VERSION "created by canmatrix"

NS_ :

BS_:

BU_:

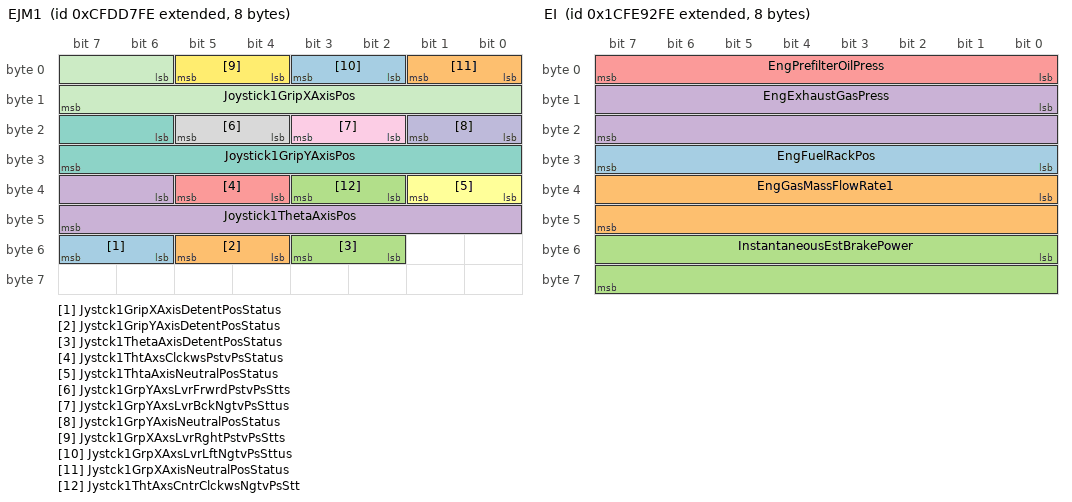
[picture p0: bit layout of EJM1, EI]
BO_ 2365446142 EJM1: 8 Vector__XXX
 SG_ Jystck1GripXAxisDetentPosStatus : 54|2@1+ (1,0) [0|3] "" Vector__XXX
 SG_ Jystck1GripYAxisDetentPosStatus : 52|2@1+ (1,0) [0|3] "" Vector__XXX
 SG_ Jystck1ThetaAxisDetentPosStatus : 50|2@1+ (1,0) [0|3] "" Vector__XXX
 SG_ Joystick1ThetaAxisPos : 38|10@1+ (0.1,0) [0|102] "%" Vector__XXX
 SG_ Jystck1ThtAxsClckwsPstvPsStatus : 36|2@1+ (1,0) [0|3] "" Vector__XXX
 SG_ Jystck1ThtaAxisNeutralPosStatus : 32|2@1+ (1,0) [0|3] "" Vector__XXX
 SG_ Joystick1GripYAxisPos : 22|10@1+ (0.1,0) [0|102] "%" Vector__XXX
 SG_ Jystck1GrpYAxsLvrFrwrdPstvPsStts : 20|2@1+ (1,0) [0|3] "" Vector__XXX
 SG_ Jystck1GrpYAxsLvrBckNgtvPsSttus : 18|2@1+ (1,0) [0|3] "" Vector__XXX
 SG_ Jystck1GrpYAxisNeutralPosStatus : 16|2@1+ (1,0) [0|3] "" Vector__XXX
 SG_ Joystick1GripXAxisPos : 6|10@1+ (0.1,0) [0|102] "%" Vector__XXX
 SG_ Jystck1GrpXAxsLvrRghtPstvPsStts : 4|2@1+ (1,0) [0|3] "" Vector__XXX
 SG_ Jystck1GrpXAxsLvrLftNgtvPsSttus : 2|2@1+ (1,0) [0|3] "" Vector__XXX
 SG_ Jystck1GrpXAxisNeutralPosStatus : 0|2@1+ (1,0) [0|3] "" Vector__XXX
 SG_ Jystck1ThtAxsCntrClckwsNgtvPsStt : 34|2@1+ (1,0) [0|3] "" Vector__XXX

BO_ 2633929470 EI: 8 Vector__XXX
 SG_ EngFuelRackPos : 24|8@1+ (0.4,0) [0|100] "%" Vector__XXX
 SG_ EngGasMassFlowRate1 : 32|16@1+ (0.05,0) [0|3212.75] "kg/h" Vector__XXX
 SG_ InstantaneousEstBrakePower : 48|16@1+ (0.5,0) [0|32127.5] "kW" Vector__XXX
 SG_ EngExhaustGasPress : 8|16@1+ (0.0078125,-250) [-250|251.99] "kPa" Vector__XXX
 SG_ EngPrefilterOilPress : 0|8@1+ (4,0) [0|1000] "kPa" Vector__XXX

BO_ 2633937406 EH: 8 Vector__XXX
 SG_ TotalECURunTime : 32|32@1+ (0.05,0) [0|210554060.75] "hr" Vector__XXX
 SG_ TotalECUDistance : 0|32@1+ (0.125,0) [0|526385151.9] "km" Vector__XXX

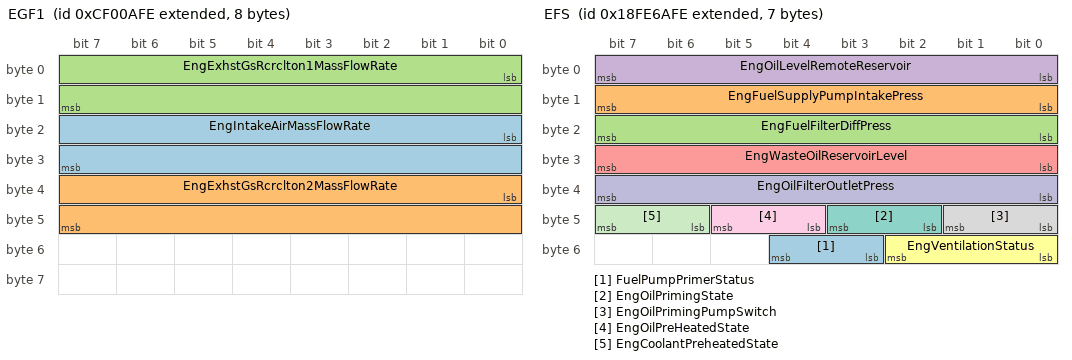
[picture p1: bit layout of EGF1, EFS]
BO_ 2364541694 EGF1: 8 Vector__XXX
 SG_ EngIntakeAirMassFlowRate : 16|16@1+ (0.05,0) [0|3212.75] "kg/h" Vector__XXX
 SG_ EngExhstGsRcrclton2MassFlowRate : 32|16@1+ (0.05,0) [0|3212.75] "kg/h" Vector__XXX
 SG_ EngExhstGsRcrclton1MassFlowRate : 0|16@1+ (0.05,0) [0|3212.75] "kg/h" Vector__XXX

BO_ 2566810366 EFS: 7 Vector__XXX
 SG_ FuelPumpPrimerStatus : 51|2@1+ (1,0) [0|3] "" Vector__XXX
 SG_ EngFuelSupplyPumpIntakePress : 8|8@1+ (2,0) [0|500] "kPa" Vector__XXX
 SG_ EngFuelFilterDiffPress : 16|8@1+ (2,0) [0|500] "kPa" Vector__XXX
 SG_ EngOilLevelRemoteReservoir : 0|8@1+ (0.4,0) [0|100] "%" Vector__XXX
 SG_ EngWasteOilReservoirLevel : 24|8@1+ (0.4,0) [0|100] "%" Vector__XXX
 SG_ EngVentilationStatus : 48|3@1+ (1,0) [0|7] "" Vector__XXX
 SG_ EngOilPrimingState : 42|2@1+ (1,0) [0|3] "" Vector__XXX
 SG_ EngOilPrimingPumpSwitch : 40|2@1+ (1,0) [0|3] "" Vector__XXX
 SG_ EngOilPreHeatedState : 44|2@1+ (1,0) [0|3] "" Vector__XXX
 SG_ EngOilFilterOutletPress : 32|8@1+ (4,0) [0|1000] "kPa" Vector__XXX
 SG_ EngCoolantPreheatedState : 46|2@1+ (1,0) [0|3] "" Vector__XXX

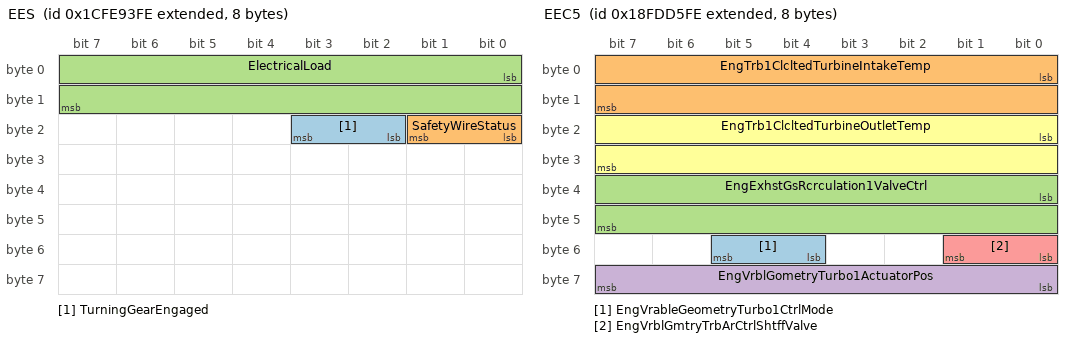
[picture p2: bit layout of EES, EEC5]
BO_ 2633929726 EES: 8 Vector__XXX
 SG_ TurningGearEngaged : 18|2@1+ (1,0) [0|3] "" Vector__XXX
 SG_ SafetyWireStatus : 16|2@1+ (1,0) [0|3] "" Vector__XXX
 SG_ ElectricalLoad : 0|16@1+ (0.5,0) [0|32127.5] "kW" Vector__XXX

BO_ 2566772222 EEC5: 8 Vector__XXX
 SG_ EngVrableGeometryTurbo1CtrlMode : 52|2@1+ (1,0) [0|3] "" Vector__XXX
 SG_ EngTrb1ClcltedTurbineIntakeTemp : 0|16@1+ (0.03125,-273) [-273|1734.96875] "deg C" Vector__XXX
 SG_ EngExhstGsRcrculation1ValveCtrl : 32|16@1+ (0.0025,0) [0|160.6375] "%" Vector__XXX
 SG_ EngVrblGometryTurbo1ActuatorPos : 56|8@1+ (0.4,0) [0|100] "%" Vector__XXX
 SG_ EngVrblGmtryTrbArCtrlShtffValve : 48|2@1+ (1,0) [0|3] "" Vector__XXX
 SG_ EngTrb1ClcltedTurbineOutletTemp : 16|16@1+ (0.03125,-273) [-273|1734.96875] "deg C" Vector__XXX

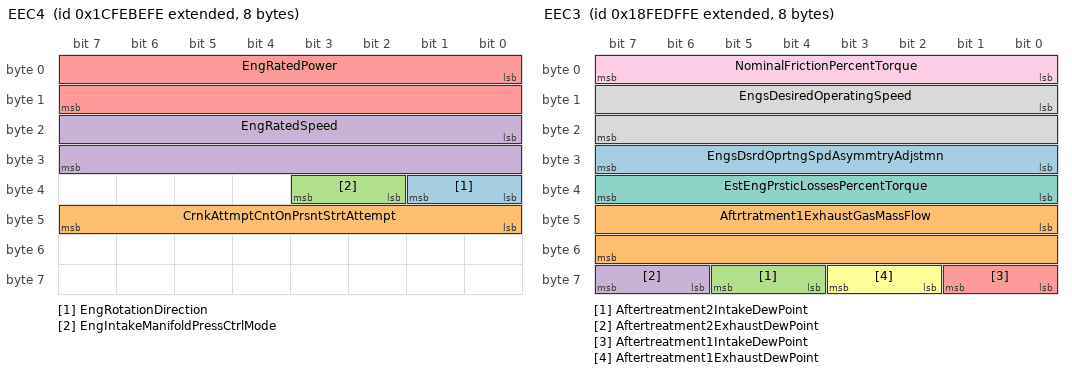
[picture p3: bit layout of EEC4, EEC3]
BO_ 2633940734 EEC4: 8 Vector__XXX
 SG_ EngRotationDirection : 32|2@1+ (1,0) [0|3] "" Vector__XXX
 SG_ CrnkAttmptCntOnPrsntStrtAttempt : 40|8@1+ (1,0) [0|250] "" Vector__XXX
 SG_ EngIntakeManifoldPressCtrlMode : 34|2@1+ (1,0) [0|3] "" Vector__XXX
 SG_ EngRatedSpeed : 16|16@1+ (0.125,0) [0|8031.875] "rpm" Vector__XXX
 SG_ EngRatedPower : 0|16@1+ (0.5,0) [0|32127.5] "kW" Vector__XXX

BO_ 2566840318 EEC3: 8 Vector__XXX
 SG_ EngsDsrdOprtngSpdAsymmtryAdjstmn : 24|8@1+ (1,0) [0|250] "" Vector__XXX
 SG_ Aftrtratment1ExhaustGasMassFlow : 40|16@1+ (0.2,0) [0|12851] "kg/h" Vector__XXX
 SG_ Aftertreatment2IntakeDewPoint : 60|2@1+ (1,0) [0|3] "" Vector__XXX
 SG_ Aftertreatment2ExhaustDewPoint : 62|2@1+ (1,0) [0|3] "" Vector__XXX
 SG_ Aftertreatment1IntakeDewPoint : 56|2@1+ (1,0) [0|3] "" Vector__XXX
 SG_ Aftertreatment1ExhaustDewPoint : 58|2@1+ (1,0) [0|3] "" Vector__XXX
 SG_ EstEngPrsticLossesPercentTorque : 32|8@1+ (1,-125) [-125|125] "%" Vector__XXX
 SG_ EngsDesiredOperatingSpeed : 8|16@1+ (0.125,0) [0|8031.875] "rpm" Vector__XXX
 SG_ NominalFrictionPercentTorque : 0|8@1+ (1,-125) [-125|125] "%" Vector__XXX

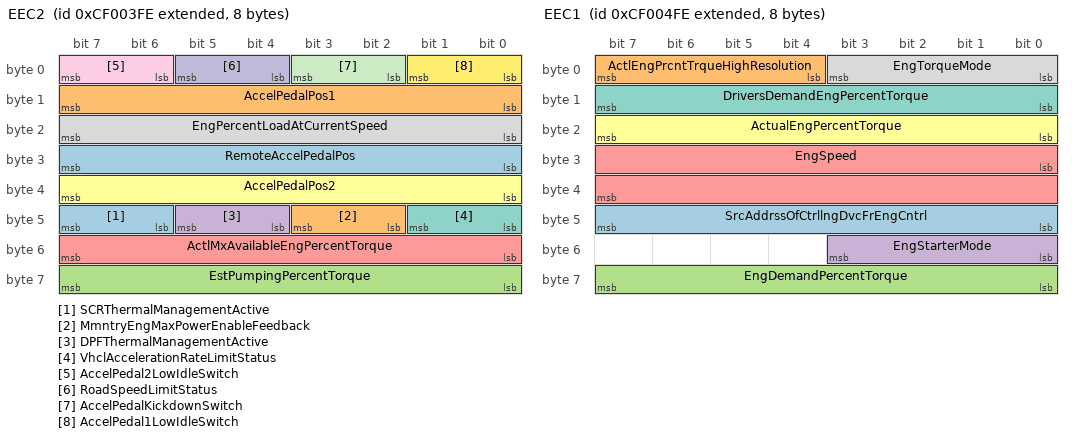
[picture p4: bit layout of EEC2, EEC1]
BO_ 2364539902 EEC2: 8 Vector__XXX
 SG_ SCRThermalManagementActive : 46|2@1+ (1,0) [0|3] "" Vector__XXX
 SG_ MmntryEngMaxPowerEnableFeedback : 42|2@1+ (1,0) [0|3] "" Vector__XXX
 SG_ EstPumpingPercentTorque : 56|8@1+ (1,-125) [-125|125] "%" Vector__XXX
 SG_ DPFThermalManagementActive : 44|2@1+ (1,0) [0|3] "" Vector__XXX
 SG_ ActlMxAvailableEngPercentTorque : 48|8@1+ (0.4,0) [0|100] "%" Vector__XXX
 SG_ AccelPedalPos2 : 32|8@1+ (0.4,0) [0|100] "%" Vector__XXX
 SG_ VhclAccelerationRateLimitStatus : 40|2@1+ (1,0) [0|3] "" Vector__XXX
 SG_ EngPercentLoadAtCurrentSpeed : 16|8@1+ (1,0) [0|250] "%" Vector__XXX
 SG_ AccelPedal2LowIdleSwitch : 6|2@1+ (1,0) [0|3] "" Vector__XXX
 SG_ RoadSpeedLimitStatus : 4|2@1+ (1,0) [0|3] "" Vector__XXX
 SG_ AccelPedalKickdownSwitch : 2|2@1+ (1,0) [0|3] "" Vector__XXX
 SG_ AccelPedal1LowIdleSwitch : 0|2@1+ (1,0) [0|3] "" Vector__XXX
 SG_ RemoteAccelPedalPos : 24|8@1+ (0.4,0) [0|100] "%" Vector__XXX
 SG_ AccelPedalPos1 : 8|8@1+ (0.4,0) [0|100] "%" Vector__XXX

BO_ 2364540158 EEC1: 8 Vector__XXX
 SG_ SrcAddrssOfCtrllngDvcFrEngCntrl : 40|8@1+ (1,0) [0|255] "" Vector__XXX
 SG_ ActlEngPrcntTrqueHighResolution : 4|4@1+ (0.125,0) [0|0.875] "%" Vector__XXX
 SG_ EngDemandPercentTorque : 56|8@1+ (1,-125) [-125|125] "%" Vector__XXX
 SG_ EngStarterMode : 48|4@1+ (1,0) [0|15] "" Vector__XXX
 SG_ EngSpeed : 24|16@1+ (0.125,0) [0|8031.875] "rpm" Vector__XXX
 SG_ ActualEngPercentTorque : 16|8@1+ (1,-125) [-125|125] "%" Vector__XXX
 SG_ DriversDemandEngPercentTorque : 8|8@1+ (1,-125) [-125|125] "%" Vector__XXX
 SG_ EngTorqueMode : 0|4@1+ (1,0) [0|15] "" Vector__XXX

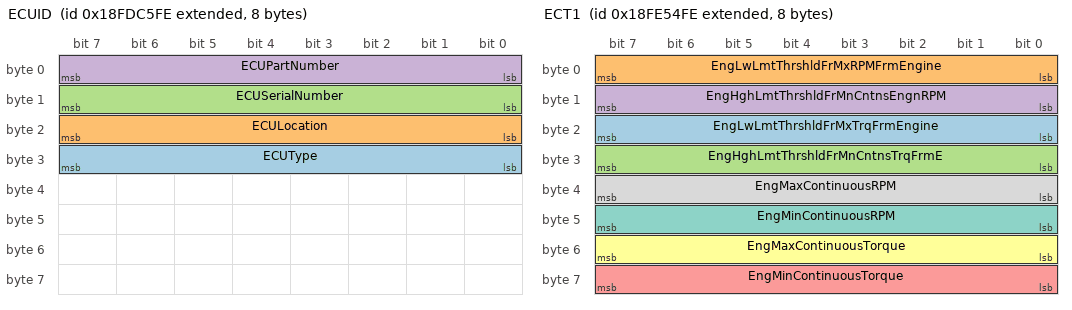
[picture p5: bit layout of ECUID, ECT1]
BO_ 2566768126 ECUID: 8 Vector__XXX
 SG_ ECUType : 24|8@1+ (1,0) [0|255] "" Vector__XXX
 SG_ ECULocation : 16|8@1+ (1,0) [0|255] "" Vector__XXX
 SG_ ECUSerialNumber : 8|8@1+ (1,0) [0|255] "" Vector__XXX
 SG_ ECUPartNumber : 0|8@1+ (1,0) [0|255] "" Vector__XXX

BO_ 2566804734 ECT1: 8 Vector__XXX
 SG_ EngLwLmtThrshldFrMxTrqFrmEngine : 16|8@1+ (1,-125) [-125|125] "%" Vector__XXX
 SG_ EngLwLmtThrshldFrMxRPMFrmEngine : 0|8@1+ (32,0) [0|8000] "rpm" Vector__XXX
 SG_ EngHghLmtThrshldFrMnCntnsTrqFrmE : 24|8@1+ (1,-125) [-125|125] "%" Vector__XXX
 SG_ EngHghLmtThrshldFrMnCntnsEngnRPM : 8|8@1+ (32,0) [0|8000] "rpm" Vector__XXX
 SG_ EngMinContinuousTorque : 56|8@1+ (1,-125) [-125|125] "%" Vector__XXX
 SG_ EngMaxContinuousTorque : 48|8@1+ (1,-125) [-125|125] "%" Vector__XXX
 SG_ EngMinContinuousRPM : 40|8@1+ (32,0) [0|8000] "rpm" Vector__XXX
 SG_ EngMaxContinuousRPM : 32|8@1+ (32,0) [0|8000] "rpm" Vector__XXX

BO_ 2566841342 EC1: 39 Vector__XXX
 SG_ SupportTSC1CtrlPurposeGroup4 : 304|8@1+ (1,0) [0|255] "" Vector__XXX
 SG_ SupportTSC1CtrlPurposeGroup3 : 296|8@1+ (1,0) [0|255] "" Vector__XXX
 SG_ SupportTSC1CtrlPurposeGroup2 : 288|8@1+ (1,0) [0|255] "" Vector__XXX
 SG_ SupportTSC1CtrlPurposeGroup1 : 280|8@1+ (1,0) [0|255] "" Vector__XXX
 SG_ SupportVariableRateTSC1Message : 272|8@1+ (1,0) [0|255] "" Vector__XXX
 SG_ EngDefaultTorqueLimit : 256|16@1+ (1,0) [0|64255] "Nm" Vector__XXX
 SG_ EngMomentOfInertia : 240|16@1+ (0.004,0) [0|257.02] "kg*m*m" Vector__XXX
 SG_ EngExRngRqdSpdCtrlRngUpperLimit : 224|16@1+ (0.125,0) [0|8031.875] "rpm" Vector__XXX
 SG_ EngRqdTorqueCtrlRangeUpperLimit : 216|8@1+ (1,-125) [-125|125] "%" Vector__XXX
 SG_ EngRqdTorqueCtrlRangeLowerLimit : 208|8@1+ (1,-125) [-125|125] "%" Vector__XXX
 SG_ EngRqedSpeedCtrlRangeUpperLimit : 200|8@1+ (10,0) [0|2500] "rpm" Vector__XXX
 SG_ EngRqedSpeedCtrlRangeLowerLimit : 192|8@1+ (10,0) [0|2500] "rpm" Vector__XXX
 SG_ EngMxMomentaryOverrideTimeLimit : 184|8@1+ (0.1,0) [0|25] "s" Vector__XXX
 SG_ EngMxMmntaryOverrideSpeedPoint7 : 168|16@1+ (0.125,0) [0|8031.875] "rpm" Vector__XXX
 SG_ EngReferenceTorque : 152|16@1+ (1,0) [0|64255] "Nm" Vector__XXX
 SG_ EngSpeedAtHighIdlePoint6 : 120|16@1+ (0.125,0) [0|8031.875] "rpm" Vector__XXX
 SG_ EngGainOfEndspeedGovernor : 136|16@1+ (0.00078125,0) [0|50.2] "%/rpm" Vector__XXX
 SG_ EngPercentTorqueAtPoint5 : 112|8@1+ (1,-125) [-125|125] "%" Vector__XXX
 SG_ EngSpeedAtPoint5 : 96|16@1+ (0.125,0) [0|8031.875] "rpm" Vector__XXX
 SG_ EngPercentTorqueAtPoint4 : 88|8@1+ (1,-125) [-125|125] "%" Vector__XXX
 SG_ EngSpeedAtPoint4 : 72|16@1+ (0.125,0) [0|8031.875] "rpm" Vector__XXX
 SG_ EngPercentTorqueAtPoint3 : 64|8@1+ (1,-125) [-125|125] "%" Vector__XXX
 SG_ EngSpeedAtPoint3 : 48|16@1+ (0.125,0) [0|8031.875] "rpm" Vector__XXX
 SG_ EngPercentTorqueAtPoint2 : 40|8@1+ (1,-125) [-125|125] "%" Vector__XXX
 SG_ EngSpeedAtPoint2 : 24|16@1+ (0.125,0) [0|8031.875] "rpm" Vector__XXX
 SG_ EngPercentTorqueAtIdlePoint1 : 16|8@1+ (1,-125) [-125|125] "%" Vector__XXX
 SG_ EngSpeedAtIdlePoint1 : 0|16@1+ (0.125,0) [0|8031.875] "rpm" Vector__XXX

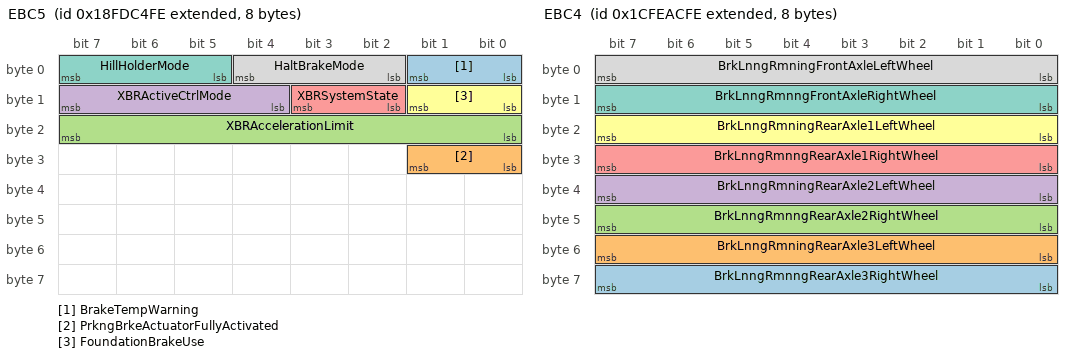
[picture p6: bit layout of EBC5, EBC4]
BO_ 2566767870 EBC5: 8 Vector__XXX
 SG_ BrakeTempWarning : 0|2@1+ (1,0) [0|3] "" Vector__XXX
 SG_ PrkngBrkeActuatorFullyActivated : 24|2@1+ (1,0) [0|3] "" Vector__XXX
 SG_ XBRAccelerationLimit : 16|8@1+ (0.1,-12.5) [-12.5|12.5] "m/s/s" Vector__XXX
 SG_ XBRActiveCtrlMode : 12|4@1+ (1,0) [0|15] "" Vector__XXX
 SG_ XBRSystemState : 10|2@1+ (1,0) [0|3] "" Vector__XXX
 SG_ FoundationBrakeUse : 8|2@1+ (1,0) [0|3] "" Vector__XXX
 SG_ HillHolderMode : 5|3@1+ (1,0) [0|7] "" Vector__XXX
 SG_ HaltBrakeMode : 2|3@1+ (1,0) [0|7] "" Vector__XXX

BO_ 2633936126 EBC4: 8 Vector__XXX
 SG_ BrkLnngRmnngRearAxle3RightWheel : 56|8@1+ (0.4,0) [0|100] "%" Vector__XXX
 SG_ BrkLnngRmningRearAxle3LeftWheel : 48|8@1+ (0.4,0) [0|100] "%" Vector__XXX
 SG_ BrkLnngRmnngRearAxle2RightWheel : 40|8@1+ (0.4,0) [0|100] "%" Vector__XXX
 SG_ BrkLnngRmningRearAxle2LeftWheel : 32|8@1+ (0.4,0) [0|100] "%" Vector__XXX
 SG_ BrkLnngRmnngRearAxle1RightWheel : 24|8@1+ (0.4,0) [0|100] "%" Vector__XXX
 SG_ BrkLnngRmningRearAxle1LeftWheel : 16|8@1+ (0.4,0) [0|100] "%" Vector__XXX
 SG_ BrkLnngRmnngFrontAxleRightWheel : 8|8@1+ (0.4,0) [0|100] "%" Vector__XXX
 SG_ BrkLnngRmningFrontAxleLeftWheel : 0|8@1+ (0.4,0) [0|100] "%" Vector__XXX

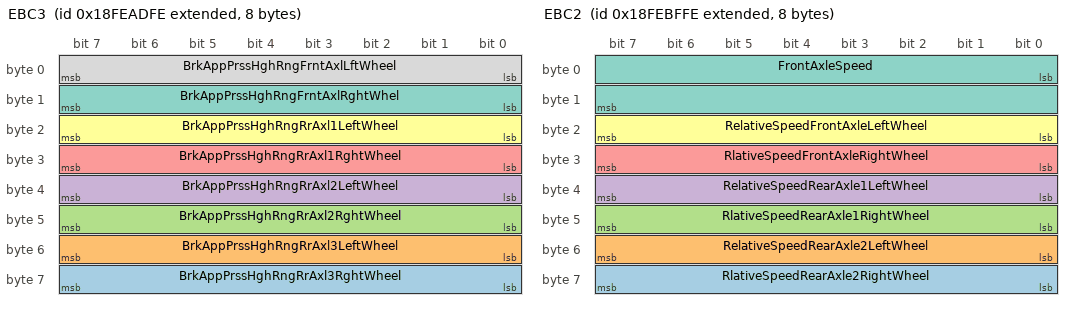
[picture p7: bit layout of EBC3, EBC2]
BO_ 2566827518 EBC3: 8 Vector__XXX
 SG_ BrkAppPrssHghRngRrAxl3RghtWheel : 56|8@1+ (5,0) [0|1250] "kPa" Vector__XXX
 SG_ BrkAppPrssHghRngRrAxl3LeftWheel : 48|8@1+ (5,0) [0|1250] "kPa" Vector__XXX
 SG_ BrkAppPrssHghRngRrAxl2RghtWheel : 40|8@1+ (5,0) [0|1250] "kPa" Vector__XXX
 SG_ BrkAppPrssHghRngRrAxl2LeftWheel : 32|8@1+ (5,0) [0|1250] "kPa" Vector__XXX
 SG_ BrkAppPrssHghRngRrAxl1RghtWheel : 24|8@1+ (5,0) [0|1250] "kPa" Vector__XXX
 SG_ BrkAppPrssHghRngRrAxl1LeftWheel : 16|8@1+ (5,0) [0|1250] "kPa" Vector__XXX
 SG_ BrkAppPrssHghRngFrntAxlRghtWhel : 8|8@1+ (5,0) [0|1250] "kPa" Vector__XXX
 SG_ BrkAppPrssHghRngFrntAxlLftWheel : 0|8@1+ (5,0) [0|1250] "kPa" Vector__XXX

BO_ 2566832126 EBC2: 8 Vector__XXX
 SG_ RlativeSpeedRearAxle2RightWheel : 56|8@1+ (0.0625,-7.8125) [-7.8125|7.8125] "km/h" Vector__XXX
 SG_ RelativeSpeedRearAxle2LeftWheel : 48|8@1+ (0.0625,-7.8125) [-7.8125|7.8125] "km/h" Vector__XXX
 SG_ RlativeSpeedRearAxle1RightWheel : 40|8@1+ (0.0625,-7.8125) [-7.8125|7.8125] "km/h" Vector__XXX
 SG_ RelativeSpeedRearAxle1LeftWheel : 32|8@1+ (0.0625,-7.8125) [-7.8125|7.8125] "km/h" Vector__XXX
 SG_ RlativeSpeedFrontAxleRightWheel : 24|8@1+ (0.0625,-7.8125) [-7.8125|7.8125] "km/h" Vector__XXX
 SG_ RelativeSpeedFrontAxleLeftWheel : 16|8@1+ (0.0625,-7.8125) [-7.8125|7.8125] "km/h" Vector__XXX
 SG_ FrontAxleSpeed : 0|16@1+ (0.00390625,0) [0|250.996] "km/h" Vector__XXX

BO_ 2565865982 EBC1: 8 Vector__XXX
 SG_ EngAuxShutdownSwitch : 28|2@1+ (1,0) [0|3] "" Vector__XXX
 SG_ SrcAddrssOfCtrllngDvcFrBrkCntrl : 48|8@1+ (1,0) [0|255] "" Vector__XXX
 SG_ BrakePedalPos : 8|8@1+ (0.4,0) [0|100] "%" Vector__XXX
 SG_ TrctrMntdTrilerABSWarningSignal : 62|2@1+ (1,0) [0|3] "" Vector__XXX
 SG_ TrailerABSStatus : 60|2@1+ (1,0) [0|3] "" Vector__XXX
 SG_ HaltBrakeSwitch : 58|2@1+ (1,0) [0|3] "" Vector__XXX
 SG_ ATC_ASRInformationSignal : 46|2@1+ (1,0) [0|3] "" Vector__XXX
 SG_ ABS_EBSAmberWarningSignal : 44|2@1+ (1,0) [0|3] "" Vector__XXX
 SG_ EBSRedWarningSignal : 42|2@1+ (1,0) [0|3] "" Vector__XXX
 SG_ ABSFullyOperational : 40|2@1+ (1,0) [0|3] "" Vector__XXX
 SG_ EngRetarderSelection : 32|8@1+ (0.4,0) [0|100] "%" Vector__XXX
 SG_ RemoteAccelEnableSwitch : 30|2@1+ (1,0) [0|3] "" Vector__XXX
 SG_ EngDerateSwitch : 26|2@1+ (1,0) [0|3] "" Vector__XXX
 SG_ AccelInterlockSwitch : 24|2@1+ (1,0) [0|3] "" Vector__XXX
 SG_ TractionCtrlOverrideSwitch : 22|2@1+ (1,0) [0|3] "" Vector__XXX
 SG_ ASRHillHolderSwitch : 20|2@1+ (1,0) [0|3] "" Vector__XXX
 SG_ ASROffroadSwitch : 18|2@1+ (1,0) [0|3] "" Vector__XXX
 SG_ ABSOffroadSwitch : 16|2@1+ (1,0) [0|3] "" Vector__XXX
 SG_ EBSBrakeSwitch : 6|2@1+ (1,0) [0|3] "" Vector__XXX
 SG_ AntiLockBrakingActive : 4|2@1+ (1,0) [0|3] "" Vector__XXX
 SG_ ASRBrakeCtrlActive : 2|2@1+ (1,0) [0|3] "" Vector__XXX
 SG_ ASREngCtrlActive : 0|2@1+ (1,0) [0|3] "" Vector__XXX

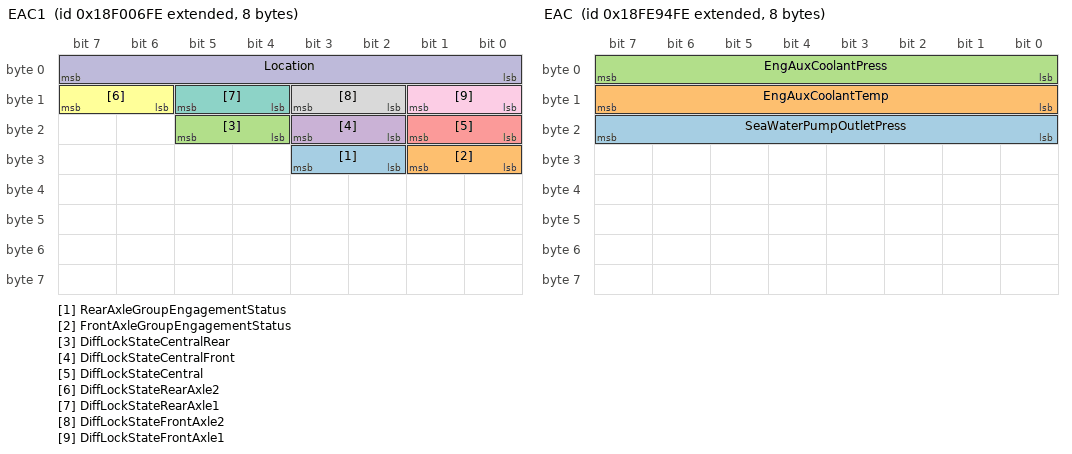
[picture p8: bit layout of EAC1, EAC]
BO_ 2565867262 EAC1: 8 Vector__XXX
 SG_ RearAxleGroupEngagementStatus : 26|2@1+ (1,0) [0|3] "" Vector__XXX
 SG_ FrontAxleGroupEngagementStatus : 24|2@1+ (1,0) [0|3] "" Vector__XXX
 SG_ DiffLockStateCentralRear : 20|2@1+ (1,0) [0|3] "" Vector__XXX
 SG_ DiffLockStateCentralFront : 18|2@1+ (1,0) [0|3] "" Vector__XXX
 SG_ DiffLockStateCentral : 16|2@1+ (1,0) [0|3] "" Vector__XXX
 SG_ DiffLockStateRearAxle2 : 14|2@1+ (1,0) [0|3] "" Vector__XXX
 SG_ DiffLockStateRearAxle1 : 12|2@1+ (1,0) [0|3] "" Vector__XXX
 SG_ DiffLockStateFrontAxle2 : 10|2@1+ (1,0) [0|3] "" Vector__XXX
 SG_ DiffLockStateFrontAxle1 : 8|2@1+ (1,0) [0|3] "" Vector__XXX
 SG_ Location : 0|8@1+ (1,0) [0|255] "" Vector__XXX

BO_ 2566821118 EAC: 8 Vector__XXX
 SG_ SeaWaterPumpOutletPress : 16|8@1+ (2,0) [0|500] "kPa" Vector__XXX
 SG_ EngAuxCoolantTemp : 8|8@1+ (1,-40) [-40|210] "deg C" Vector__XXX
 SG_ EngAuxCoolantPress : 0|8@1+ (4,0) [0|1000] "kPa" Vector__XXX

BO_ 2566810622 DI: 8 Vector__XXX
 SG_ Driver2 : 8|8@1+ (1,0) [0|255] "" Vector__XXX
 SG_ Driver1 : 0|8@1+ (1,0) [0|255] "" Vector__XXX

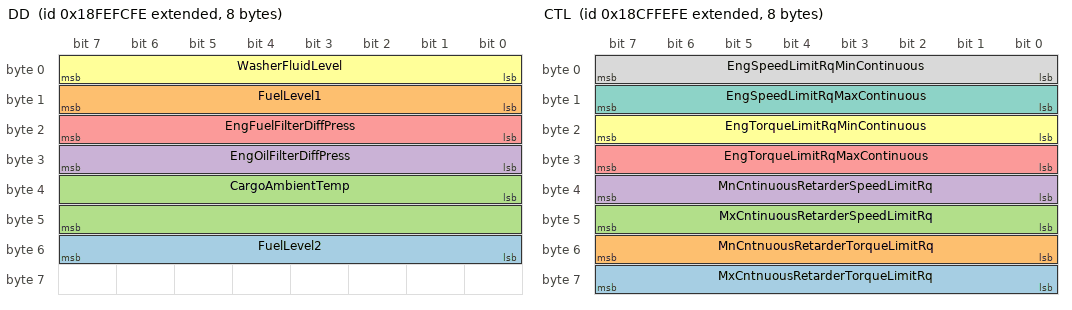
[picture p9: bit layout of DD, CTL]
BO_ 2566847742 DD: 8 Vector__XXX
 SG_ FuelLevel2 : 48|8@1+ (0.4,0) [0|100] "%" Vector__XXX
 SG_ FuelLevel1 : 8|8@1+ (0.4,0) [0|100] "%" Vector__XXX
 SG_ CargoAmbientTemp : 32|16@1+ (0.03125,-273) [-273|1734.96875] "deg C" Vector__XXX
 SG_ EngOilFilterDiffPress : 24|8@1+ (0.5,0) [0|125] "kPa" Vector__XXX
 SG_ EngFuelFilterDiffPress : 16|8@1+ (2,0) [0|500] "kPa" Vector__XXX
 SG_ WasherFluidLevel : 0|8@1+ (0.4,0) [0|100] "%" Vector__XXX

BO_ 2566811902 CVW: 8 Vector__XXX
 SG_ PoweredVehicleWeight : 0|16@1+ (10,0) [0|642550] "kg" Vector__XXX
 SG_ GrossCombinationVehicleWeight : 16|16@1+ (10,0) [0|642550] "kg" Vector__XXX

BO_ 2563768062 CTL: 8 Vector__XXX
 SG_ MxCntnuousRetarderTorqueLimitRq : 56|8@1+ (1,-125) [-125|125] "%" Vector__XXX
 SG_ MnCntnuousRetarderTorqueLimitRq : 48|8@1+ (1,-125) [-125|125] "%" Vector__XXX
 SG_ MxCntinuousRetarderSpeedLimitRq : 40|8@1+ (32,0) [0|8000] "rpm" Vector__XXX
 SG_ MnCntinuousRetarderSpeedLimitRq : 32|8@1+ (32,0) [0|8000] "rpm" Vector__XXX
 SG_ EngTorqueLimitRqMaxContinuous : 24|8@1+ (1,-125) [-125|125] "%" Vector__XXX
 SG_ EngTorqueLimitRqMinContinuous : 16|8@1+ (1,-125) [-125|125] "%" Vector__XXX
 SG_ EngSpeedLimitRqMaxContinuous : 8|8@1+ (32,0) [0|8000] "rpm" Vector__XXX
 SG_ EngSpeedLimitRqMinContinuous : 0|8@1+ (32,0) [0|8000] "rpm" Vector__XXX

BO_ 2633924862 CT6: 8 Vector__XXX
 SG_ EngAverageCombustionTime : 16|16@1+ (0.01,0) [0|642.55] "ms" Vector__XXX
 SG_ EngDesiredCombustionTime : 0|16@1+ (0.01,0) [0|642.55] "ms" Vector__XXX

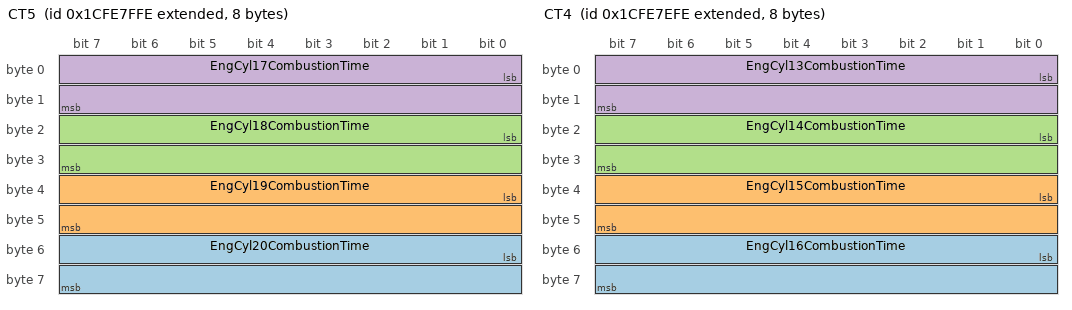
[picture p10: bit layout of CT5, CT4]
BO_ 2633924606 CT5: 8 Vector__XXX
 SG_ EngCyl20CombustionTime : 48|16@1+ (0.01,0) [0|642.55] "ms" Vector__XXX
 SG_ EngCyl19CombustionTime : 32|16@1+ (0.01,0) [0|642.55] "ms" Vector__XXX
 SG_ EngCyl18CombustionTime : 16|16@1+ (0.01,0) [0|642.55] "ms" Vector__XXX
 SG_ EngCyl17CombustionTime : 0|16@1+ (0.01,0) [0|642.55] "ms" Vector__XXX

BO_ 2633924350 CT4: 8 Vector__XXX
 SG_ EngCyl16CombustionTime : 48|16@1+ (0.01,0) [0|642.55] "ms" Vector__XXX
 SG_ EngCyl15CombustionTime : 32|16@1+ (0.01,0) [0|642.55] "ms" Vector__XXX
 SG_ EngCyl14CombustionTime : 16|16@1+ (0.01,0) [0|642.55] "ms" Vector__XXX
 SG_ EngCyl13CombustionTime : 0|16@1+ (0.01,0) [0|642.55] "ms" Vector__XXX

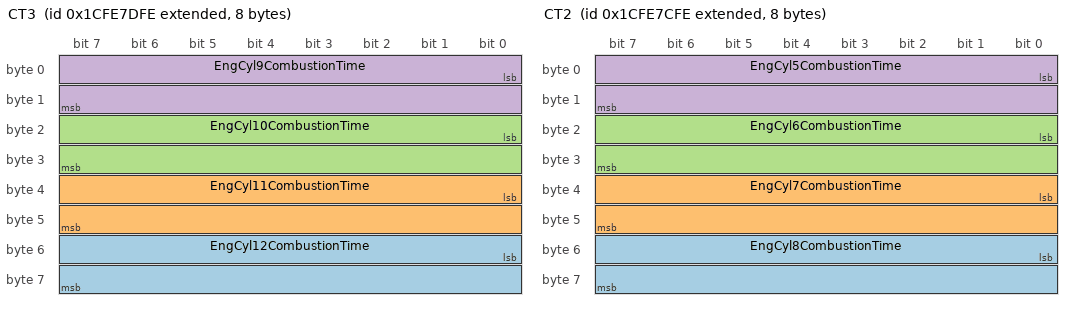
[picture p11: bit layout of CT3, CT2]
BO_ 2633924094 CT3: 8 Vector__XXX
 SG_ EngCyl12CombustionTime : 48|16@1+ (0.01,0) [0|642.55] "ms" Vector__XXX
 SG_ EngCyl11CombustionTime : 32|16@1+ (0.01,0) [0|642.55] "ms" Vector__XXX
 SG_ EngCyl10CombustionTime : 16|16@1+ (0.01,0) [0|642.55] "ms" Vector__XXX
 SG_ EngCyl9CombustionTime : 0|16@1+ (0.01,0) [0|642.55] "ms" Vector__XXX

BO_ 2633923838 CT2: 8 Vector__XXX
 SG_ EngCyl8CombustionTime : 48|16@1+ (0.01,0) [0|642.55] "ms" Vector__XXX
 SG_ EngCyl7CombustionTime : 32|16@1+ (0.01,0) [0|642.55] "ms" Vector__XXX
 SG_ EngCyl6CombustionTime : 16|16@1+ (0.01,0) [0|642.55] "ms" Vector__XXX
 SG_ EngCyl5CombustionTime : 0|16@1+ (0.01,0) [0|642.55] "ms" Vector__XXX

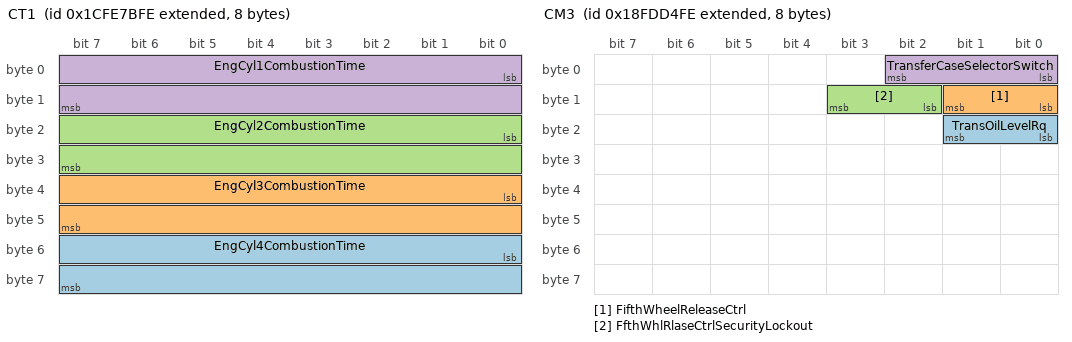
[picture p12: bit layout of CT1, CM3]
BO_ 2633923582 CT1: 8 Vector__XXX
 SG_ EngCyl4CombustionTime : 48|16@1+ (0.01,0) [0|642.55] "ms" Vector__XXX
 SG_ EngCyl3CombustionTime : 32|16@1+ (0.01,0) [0|642.55] "ms" Vector__XXX
 SG_ EngCyl2CombustionTime : 16|16@1+ (0.01,0) [0|642.55] "ms" Vector__XXX
 SG_ EngCyl1CombustionTime : 0|16@1+ (0.01,0) [0|642.55] "ms" Vector__XXX

BO_ 2633878014 CMI: 8 Vector__XXX
 SG_ TotalCountOfConfigChangesMade : 0|16@1+ (1,0) [0|64255] "counts" Vector__XXX

BO_ 2566771966 CM3: 8 Vector__XXX
 SG_ TransOilLevelRq : 16|2@1+ (1,0) [0|3] "" Vector__XXX
 SG_ FifthWheelReleaseCtrl : 8|2@1+ (1,0) [0|3] "" Vector__XXX
 SG_ FfthWhlRlaseCtrlSecurityLockout : 10|2@1+ (1,0) [0|3] "" Vector__XXX
 SG_ TransferCaseSelectorSwitch : 0|3@1+ (1,0) [0|7] "" Vector__XXX

BO_ 2564882174 CM1: 8 Vector__XXX
 SG_ DslPrtcltFltrRgnrtonForceSwitch : 42|2@1+ (1,0) [0|3] "" Vector__XXX
 SG_ DslPrtcltFltrRgnrtnInhbitSwitch : 40|2@1+ (1,0) [0|3] "" Vector__XXX
 SG_ SelectedMaxVehicleSpeedLimit : 56|8@1+ (1,0) [0|250] "" Vector__XXX
 SG_ RqCabZoneHeating : 54|2@1+ (1,0) [0|3] "" Vector__XXX
 SG_ RqEngZoneHeating : 52|2@1+ (1,0) [0|3] "" Vector__XXX
 SG_ AuxHeaterModeRq : 48|4@1+ (1,0) [0|15] "" Vector__XXX
 SG_ EngAutomaticStartEnableSwitch : 46|2@1+ (1,0) [0|3] "" Vector__XXX
 SG_ AtmaticGearShiftingEnableSwitch : 44|2@1+ (1,0) [0|3] "" Vector__XXX
 SG_ VhclLmtngSpdGvernorEnableSwitch : 38|2@1+ (1,0) [0|3] "" Vector__XXX
 SG_ VhclLmtngSpdGvrnrIncrmentSwitch : 36|2@1+ (1,0) [0|3] "" Vector__XXX
 SG_ VhclLmtngSpdGvrnrDcrementSwitch : 34|2@1+ (1,0) [0|3] "" Vector__XXX
 SG_ SeatBeltSwitch : 30|2@1+ (1,0) [0|3] "" Vector__XXX
 SG_ OperatorSeatDirectionSwitch : 28|2@1+ (1,0) [0|3] "" Vector__XXX
 SG_ BatteryMainSwitchHoldRq : 26|2@1+ (1,0) [0|3] "" Vector__XXX
 SG_ AuxHeaterCoolantPumpRq : 24|2@1+ (1,0) [0|3] "" Vector__XXX
 SG_ CabInteriorTempCmd : 8|16@1+ (0.03125,-273) [-273|1734.96875] "deg C" Vector__XXX
 SG_ RqedPercentFanSpeed : 0|8@1+ (0.4,0) [0|100] "%" Vector__XXX

BO_ 2563833598 CL: 8 Vector__XXX
 SG_ IlluminationBrightnessPercent : 0|8@1+ (0.4,0) [0|100] "%" Vector__XXX

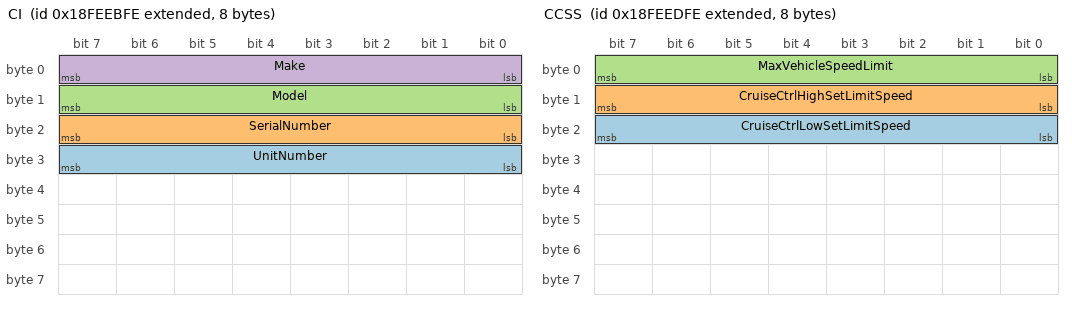
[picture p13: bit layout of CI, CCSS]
BO_ 2566843390 CI: 8 Vector__XXX
 SG_ UnitNumber : 24|8@1+ (1,0) [0|255] "" Vector__XXX
 SG_ SerialNumber : 16|8@1+ (1,0) [0|255] "" Vector__XXX
 SG_ Model : 8|8@1+ (1,0) [0|255] "" Vector__XXX
 SG_ Make : 0|8@1+ (1,0) [0|255] "" Vector__XXX

BO_ 2566844926 CCVS: 8 Vector__XXX
 SG_ ParkBrakeReleaseInhibitRq : 6|2@1+ (1,0) [0|3] "" Vector__XXX
 SG_ PTOGovernorState : 48|5@1+ (1,0) [0|31] "" Vector__XXX
 SG_ EngShutdownOverrideSwitch : 62|2@1+ (1,0) [0|3] "" Vector__XXX
 SG_ EngTestModeSwitch : 60|2@1+ (1,0) [0|3] "" Vector__XXX
 SG_ EngIdleDecrementSwitch : 58|2@1+ (1,0) [0|3] "" Vector__XXX
 SG_ EngIdleIncrementSwitch : 56|2@1+ (1,0) [0|3] "" Vector__XXX
 SG_ CruiseCtrlStates : 53|3@1+ (1,0) [0|7] "" Vector__XXX
 SG_ CruiseCtrlSetSpeed : 40|8@1+ (1,0) [0|250] "km/h" Vector__XXX
 SG_ CruiseCtrlAccelerateSwitch : 38|2@1+ (1,0) [0|3] "" Vector__XXX
 SG_ CruiseCtrlResumeSwitch : 36|2@1+ (1,0) [0|3] "" Vector__XXX
 SG_ CruiseCtrlCoastSwitch : 34|2@1+ (1,0) [0|3] "" Vector__XXX
 SG_ CruiseCtrlSetSwitch : 32|2@1+ (1,0) [0|3] "" Vector__XXX
 SG_ ClutchSwitch : 30|2@1+ (1,0) [0|3] "" Vector__XXX
 SG_ BrakeSwitch : 28|2@1+ (1,0) [0|3] "" Vector__XXX
 SG_ CruiseCtrlEnableSwitch : 26|2@1+ (1,0) [0|3] "" Vector__XXX
 SG_ CruiseCtrlActive : 24|2@1+ (1,0) [0|3] "" Vector__XXX
 SG_ WheelBasedVehicleSpeed : 8|16@1+ (0.00390625,0) [0|250.996] "km/h" Vector__XXX
 SG_ CruiseCtrlPauseSwitch : 4|2@1+ (1,0) [0|3] "" Vector__XXX
 SG_ ParkingBrakeSwitch : 2|2@1+ (1,0) [0|3] "" Vector__XXX
 SG_ TwoSpeedAxleSwitch : 0|2@1+ (1,0) [0|3] "" Vector__XXX

BO_ 2566843902 CCSS: 8 Vector__XXX
 SG_ CruiseCtrlLowSetLimitSpeed : 16|8@1+ (1,0) [0|250] "km/h" Vector__XXX
 SG_ CruiseCtrlHighSetLimitSpeed : 8|8@1+ (1,0) [0|250] "km/h" Vector__XXX
 SG_ MaxVehicleSpeedLimit : 0|8@1+ (1,0) [0|250] "km/h" Vector__XXX

BO_ 2566809598 CCC: 8 Vector__XXX
 SG_ AuxHeaterMaxOutputPower : 0|16@1+ (2,0) [0|128510] "W" Vector__XXX

BO_ 2633940222 CBI: 16 Vector__XXX
 SG_ TripServiceBrakeApps : 96|32@1+ (1,0) [0|4227858431] "appl" Vector__XXX
 SG_ TripServiceBrakeDistance : 64|32@1+ (0.125,0) [0|526385151.9] "km" Vector__XXX
 SG_ TripCompressionBrakeDistance : 32|32@1+ (0.125,0) [0|526385151.9] "km" Vector__XXX
 SG_ TotalCompressionBrakeDistance : 0|32@1+ (0.125,0) [0|526385151.9] "km" Vector__XXX

BO_ 2566775294 CACI: 8 Vector__XXX
 SG_ CbA_CRfrgrntCmprssorOutletPress : 0|8@1+ (16,0) [0|4000] "kPa" Vector__XXX

BO_ 2566803710 BT1: 8 Vector__XXX
 SG_ Battery2Temp : 8|8@1+ (1,-40) [-40|210] "deg C" Vector__XXX
 SG_ Battery1Temp : 0|8@1+ (1,-40) [-40|210] "deg C" Vector__XXX

BO_ 2365400830 BJM9: 8 Vector__XXX
 SG_ Joystick9Button9PressedStatus : 62|2@1+ (1,0) [0|3] "" Vector__XXX
 SG_ Joystick9Button10PressedStatus : 60|2@1+ (1,0) [0|3] "" Vector__XXX
 SG_ Joystick9Button11PressedStatus : 58|2@1+ (1,0) [0|3] "" Vector__XXX
 SG_ Joystick9Button12PressedStatus : 56|2@1+ (1,0) [0|3] "" Vector__XXX
 SG_ Joystick9Button5PressedStatus : 54|2@1+ (1,0) [0|3] "" Vector__XXX
 SG_ Joystick9Button6PressedStatus : 52|2@1+ (1,0) [0|3] "" Vector__XXX
 SG_ Joystick9Button7PressedStatus : 50|2@1+ (1,0) [0|3] "" Vector__XXX
 SG_ Joystick9Button8PressedStatus : 48|2@1+ (1,0) [0|3] "" Vector__XXX
 SG_ Joystick9Button1PressedStatus : 46|2@1+ (1,0) [0|3] "" Vector__XXX
 SG_ Joystick9Button2PressedStatus : 44|2@1+ (1,0) [0|3] "" Vector__XXX
 SG_ Joystick9Button3PressedStatus : 42|2@1+ (1,0) [0|3] "" Vector__XXX
 SG_ Joystick9Button4PressedStatus : 40|2@1+ (1,0) [0|3] "" Vector__XXX
 SG_ Joystick9XAxisDetentPosStatus : 38|2@1+ (1,0) [0|3] "" Vector__XXX
 SG_ Joystick9YAxisDetentPosStatus : 36|2@1+ (1,0) [0|3] "" Vector__XXX
 SG_ Joystick9YAxisPos : 22|10@1+ (0.1,0) [0|102] "%" Vector__XXX
 SG_ Jystck9YAxsLvrFrwrdPstvPsStatus : 20|2@1+ (1,0) [0|3] "" Vector__XXX
 SG_ Jystck9YAxsLvrBckNgtvePosStatus : 18|2@1+ (1,0) [0|3] "" Vector__XXX
 SG_ Joystick9YAxisNeutralPosStatus : 16|2@1+ (1,0) [0|3] "" Vector__XXX
 SG_ Joystick9XAxisPos : 6|10@1+ (0.1,0) [0|102] "%" Vector__XXX
 SG_ Jystck9XAxsLvrRghtPstvPosStatus : 4|2@1+ (1,0) [0|3] "" Vector__XXX
 SG_ Jystck9XAxsLvrLftNgtvePosStatus : 2|2@1+ (1,0) [0|3] "" Vector__XXX
 SG_ Joystick9XAxisNeutralPosStatus : 0|2@1+ (1,0) [0|3] "" Vector__XXX

BO_ 2365401342 BJM8: 8 Vector__XXX
 SG_ Joystick8Button9PressedStatus : 62|2@1+ (1,0) [0|3] "" Vector__XXX
 SG_ Joystick8Button10PressedStatus : 60|2@1+ (1,0) [0|3] "" Vector__XXX
 SG_ Joystick8Button11PressedStatus : 58|2@1+ (1,0) [0|3] "" Vector__XXX
 SG_ Joystick8Button12PressedStatus : 56|2@1+ (1,0) [0|3] "" Vector__XXX
 SG_ Joystick8Button5PressedStatus : 54|2@1+ (1,0) [0|3] "" Vector__XXX
 SG_ Joystick8Button6PressedStatus : 52|2@1+ (1,0) [0|3] "" Vector__XXX
 SG_ Joystick8Button7PressedStatus : 50|2@1+ (1,0) [0|3] "" Vector__XXX
 SG_ Joystick8Button8PressedStatus : 48|2@1+ (1,0) [0|3] "" Vector__XXX
 SG_ Joystick8Button1PressedStatus : 46|2@1+ (1,0) [0|3] "" Vector__XXX
 SG_ Joystick8Button2PressedStatus : 44|2@1+ (1,0) [0|3] "" Vector__XXX
 SG_ Joystick8Button3PressedStatus : 42|2@1+ (1,0) [0|3] "" Vector__XXX
 SG_ Joystick8Button4PressedStatus : 40|2@1+ (1,0) [0|3] "" Vector__XXX
 SG_ Joystick8XAxisDetentPosStatus : 38|2@1+ (1,0) [0|3] "" Vector__XXX
 SG_ Joystick8YAxisDetentPosStatus : 36|2@1+ (1,0) [0|3] "" Vector__XXX
 SG_ Joystick8YAxisPos : 22|10@1+ (0.1,0) [0|102] "%" Vector__XXX
 SG_ Jystck8YAxsLvrFrwrdPstvPsStatus : 20|2@1+ (1,0) [0|3] "" Vector__XXX
 SG_ Jystck8YAxsLvrBckNgtvePosStatus : 18|2@1+ (1,0) [0|3] "" Vector__XXX
 SG_ Joystick8YAxisNeutralPosStatus : 16|2@1+ (1,0) [0|3] "" Vector__XXX
 SG_ Joystick8XAxisPos : 6|10@1+ (0.1,0) [0|102] "%" Vector__XXX
 SG_ Jystck8XAxsLvrRghtPstvPosStatus : 4|2@1+ (1,0) [0|3] "" Vector__XXX
 SG_ Jystck8XAxsLvrLftNgtvePosStatus : 2|2@1+ (1,0) [0|3] "" Vector__XXX
 SG_ Joystick8XAxisNeutralPosStatus : 0|2@1+ (1,0) [0|3] "" Vector__XXX

BO_ 2365401854 BJM7: 8 Vector__XXX
 SG_ Joystick7Button9PressedStatus : 62|2@1+ (1,0) [0|3] "" Vector__XXX
 SG_ Joystick7Button10PressedStatus : 60|2@1+ (1,0) [0|3] "" Vector__XXX
 SG_ Joystick7Button11PressedStatus : 58|2@1+ (1,0) [0|3] "" Vector__XXX
 SG_ Joystick7Button12PressedStatus : 56|2@1+ (1,0) [0|3] "" Vector__XXX
 SG_ Joystick7Button5PressedStatus : 54|2@1+ (1,0) [0|3] "" Vector__XXX
 SG_ Joystick7Button6PressedStatus : 52|2@1+ (1,0) [0|3] "" Vector__XXX
 SG_ Joystick7Button7PressedStatus : 50|2@1+ (1,0) [0|3] "" Vector__XXX
 SG_ Joystick7Button8PressedStatus : 48|2@1+ (1,0) [0|3] "" Vector__XXX
 SG_ Joystick7Button1PressedStatus : 46|2@1+ (1,0) [0|3] "" Vector__XXX
 SG_ Joystick7Button2PressedStatus : 44|2@1+ (1,0) [0|3] "" Vector__XXX
 SG_ Joystick7Button3PressedStatus : 42|2@1+ (1,0) [0|3] "" Vector__XXX
 SG_ Joystick7Button4PressedStatus : 40|2@1+ (1,0) [0|3] "" Vector__XXX
 SG_ Joystick7XAxisDetentPosStatus : 38|2@1+ (1,0) [0|3] "" Vector__XXX
 SG_ Joystick7YAxisDetentPosStatus : 36|2@1+ (1,0) [0|3] "" Vector__XXX
 SG_ Joystick7YAxisPos : 22|10@1+ (0.1,0) [0|102] "%" Vector__XXX
 SG_ Jystck7YAxsLvrFrwrdPstvPsStatus : 20|2@1+ (1,0) [0|3] "" Vector__XXX
 SG_ Jystck7YAxsLvrBckNgtvePosStatus : 18|2@1+ (1,0) [0|3] "" Vector__XXX
 SG_ Joystick7YAxisNeutralPosStatus : 16|2@1+ (1,0) [0|3] "" Vector__XXX
 SG_ Joystick7XAxisPos : 6|10@1+ (0.1,0) [0|102] "%" Vector__XXX
 SG_ Jystck7XAxsLvrRghtPstvPosStatus : 4|2@1+ (1,0) [0|3] "" Vector__XXX
 SG_ Jystck7XAxsLvrLftNgtvePosStatus : 2|2@1+ (1,0) [0|3] "" Vector__XXX
 SG_ Joystick7XAxisNeutralPosStatus : 0|2@1+ (1,0) [0|3] "" Vector__XXX

BO_ 2365402366 BJM6: 8 Vector__XXX
 SG_ Joystick6Button9PressedStatus : 62|2@1+ (1,0) [0|3] "" Vector__XXX
 SG_ Joystick6Button10PressedStatus : 60|2@1+ (1,0) [0|3] "" Vector__XXX
 SG_ Joystick6Button11PressedStatus : 58|2@1+ (1,0) [0|3] "" Vector__XXX
 SG_ Joystick6Button12PressedStatus : 56|2@1+ (1,0) [0|3] "" Vector__XXX
 SG_ Joystick6Button5PressedStatus : 54|2@1+ (1,0) [0|3] "" Vector__XXX
 SG_ Joystick6Button6PressedStatus : 52|2@1+ (1,0) [0|3] "" Vector__XXX
 SG_ Joystick6Button7PressedStatus : 50|2@1+ (1,0) [0|3] "" Vector__XXX
 SG_ Joystick6Button8PressedStatus : 48|2@1+ (1,0) [0|3] "" Vector__XXX
 SG_ Joystick6Button1PressedStatus : 46|2@1+ (1,0) [0|3] "" Vector__XXX
 SG_ Joystick6Button2PressedStatus : 44|2@1+ (1,0) [0|3] "" Vector__XXX
 SG_ Joystick6Button3PressedStatus : 42|2@1+ (1,0) [0|3] "" Vector__XXX
 SG_ Joystick6Button4PressedStatus : 40|2@1+ (1,0) [0|3] "" Vector__XXX
 SG_ Joystick6XAxisDetentPosStatus : 38|2@1+ (1,0) [0|3] "" Vector__XXX
 SG_ Joystick6YAxisDetentPosStatus : 36|2@1+ (1,0) [0|3] "" Vector__XXX
 SG_ Joystick6YAxisPos : 22|10@1+ (0.1,0) [0|102] "%" Vector__XXX
 SG_ Jystck6YAxsLvrFrwrdPstvPsStatus : 20|2@1+ (1,0) [0|3] "" Vector__XXX
 SG_ Jystck6YAxsLvrBckNgtvePosStatus : 18|2@1+ (1,0) [0|3] "" Vector__XXX
 SG_ Joystick6YAxisNeutralPosStatus : 16|2@1+ (1,0) [0|3] "" Vector__XXX
 SG_ Joystick6XAxisPos : 6|10@1+ (0.1,0) [0|102] "%" Vector__XXX
 SG_ Jystck6XAxsLvrRghtPstvPosStatus : 4|2@1+ (1,0) [0|3] "" Vector__XXX
 SG_ Jystck6XAxsLvrLftNgtvePosStatus : 2|2@1+ (1,0) [0|3] "" Vector__XXX
 SG_ Joystick6XAxisNeutralPosStatus : 0|2@1+ (1,0) [0|3] "" Vector__XXX

BO_ 2365402878 BJM5: 8 Vector__XXX
 SG_ Joystick5Button9PressedStatus : 62|2@1+ (1,0) [0|3] "" Vector__XXX
 SG_ Joystick5Button10PressedStatus : 60|2@1+ (1,0) [0|3] "" Vector__XXX
 SG_ Joystick5Button11PressedStatus : 58|2@1+ (1,0) [0|3] "" Vector__XXX
 SG_ Joystick5Button12PressedStatus : 56|2@1+ (1,0) [0|3] "" Vector__XXX
 SG_ Joystick5Button5PressedStatus : 54|2@1+ (1,0) [0|3] "" Vector__XXX
 SG_ Joystick5Button6PressedStatus : 52|2@1+ (1,0) [0|3] "" Vector__XXX
 SG_ Joystick5Button7PressedStatus : 50|2@1+ (1,0) [0|3] "" Vector__XXX
 SG_ Joystick5Button8PressedStatus : 48|2@1+ (1,0) [0|3] "" Vector__XXX
 SG_ Joystick5Button1PressedStatus : 46|2@1+ (1,0) [0|3] "" Vector__XXX
 SG_ Joystick5Button2PressedStatus : 44|2@1+ (1,0) [0|3] "" Vector__XXX
 SG_ Joystick5Button3PressedStatus : 42|2@1+ (1,0) [0|3] "" Vector__XXX
 SG_ Joystick5Button4PressedStatus : 40|2@1+ (1,0) [0|3] "" Vector__XXX
 SG_ Joystick5XAxisDetentPosStatus : 38|2@1+ (1,0) [0|3] "" Vector__XXX
 SG_ Joystick5YAxisDetentPosStatus : 36|2@1+ (1,0) [0|3] "" Vector__XXX
 SG_ Joystick5YAxisPos : 22|10@1+ (0.1,0) [0|102] "%" Vector__XXX
 SG_ Jystck5YAxsLvrFrwrdPstvPsStatus : 20|2@1+ (1,0) [0|3] "" Vector__XXX
 SG_ Jystck5YAxsLvrBckNgtvePosStatus : 18|2@1+ (1,0) [0|3] "" Vector__XXX
 SG_ Joystick5YAxisNeutralPosStatus : 16|2@1+ (1,0) [0|3] "" Vector__XXX
 SG_ Joystick5XAxisPos : 6|10@1+ (0.1,0) [0|102] "%" Vector__XXX
 SG_ Jystck5XAxsLvrRghtPstvPosStatus : 4|2@1+ (1,0) [0|3] "" Vector__XXX
 SG_ Jystck5XAxsLvrLftNgtvePosStatus : 2|2@1+ (1,0) [0|3] "" Vector__XXX
 SG_ Joystick5XAxisNeutralPosStatus : 0|2@1+ (1,0) [0|3] "" Vector__XXX

BO_ 2365403390 BJM4: 8 Vector__XXX
 SG_ Joystick4Button9PressedStatus : 62|2@1+ (1,0) [0|3] "" Vector__XXX
 SG_ Joystick4Button10PressedStatus : 60|2@1+ (1,0) [0|3] "" Vector__XXX
 SG_ Joystick4Button11PressedStatus : 58|2@1+ (1,0) [0|3] "" Vector__XXX
 SG_ Joystick4Button12PressedStatus : 56|2@1+ (1,0) [0|3] "" Vector__XXX
 SG_ Joystick4Button5PressedStatus : 54|2@1+ (1,0) [0|3] "" Vector__XXX
 SG_ Joystick4Button6PressedStatus : 52|2@1+ (1,0) [0|3] "" Vector__XXX
 SG_ Joystick4Button7PressedStatus : 50|2@1+ (1,0) [0|3] "" Vector__XXX
 SG_ Joystick4Button8PressedStatus : 48|2@1+ (1,0) [0|3] "" Vector__XXX
 SG_ Joystick4Button1PressedStatus : 46|2@1+ (1,0) [0|3] "" Vector__XXX
 SG_ Joystick4Button2PressedStatus : 44|2@1+ (1,0) [0|3] "" Vector__XXX
 SG_ Joystick4Button3PressedStatus : 42|2@1+ (1,0) [0|3] "" Vector__XXX
 SG_ Joystick4Button4PressedStatus : 40|2@1+ (1,0) [0|3] "" Vector__XXX
 SG_ Joystick4XAxisDetentPosStatus : 38|2@1+ (1,0) [0|3] "" Vector__XXX
 SG_ Joystick4YAxisDetentPosStatus : 36|2@1+ (1,0) [0|3] "" Vector__XXX
 SG_ Joystick4YAxisPos : 22|10@1+ (0.1,0) [0|102] "%" Vector__XXX
 SG_ Jystck4YAxsLvrFrwrdPstvPsStatus : 20|2@1+ (1,0) [0|3] "" Vector__XXX
 SG_ Jystck4YAxsLvrBckNgtvePosStatus : 18|2@1+ (1,0) [0|3] "" Vector__XXX
 SG_ Joystick4YAxisNeutralPosStatus : 16|2@1+ (1,0) [0|3] "" Vector__XXX
 SG_ Joystick4XAxisPos : 6|10@1+ (0.1,0) [0|102] "%" Vector__XXX
 SG_ Jystck4XAxsLvrRghtPstvPosStatus : 4|2@1+ (1,0) [0|3] "" Vector__XXX
 SG_ Jystck4XAxsLvrLftNgtvePosStatus : 2|2@1+ (1,0) [0|3] "" Vector__XXX
 SG_ Joystick4XAxisNeutralPosStatus : 0|2@1+ (1,0) [0|3] "" Vector__XXX

CM_ BO_ 2365446142  "Extended Joystick Message 1";
CM_ BO_ 2633929470  "Engine Information";
CM_ BO_ 2633937406  "ECU History";
CM_ BO_ 2364541694  "Engine Gas Flow Rate";
CM_ BO_ 2566810366  "Engine Fuel/lube systems";
CM_ BO_ 2633929726  "Engine Electrical System/Module Information";
CM_ BO_ 2566772222  "Electronic Engine Controller 5";
CM_ BO_ 2633940734  "Electronic Engine Controller 4";
CM_ BO_ 2566840318  "Electronic Engine Controller 3";
CM_ BO_ 2364539902  "Electronic Engine Controller 2";
CM_ BO_ 2364540158  "Electronic Engine Controller 1";
CM_ BO_ 2566768126  "ECU Identification Information";
CM_ BO_ 2566804734  "Engine Continuous Torque & Speed Limit";
CM_ BO_ 2566841342  "Engine Configuration 1";
CM_ BO_ 2566767870  "Electronic Brake Controller 5";
CM_ BO_ 2633936126  "Wheel Brake Lining Remaining Information";
CM_ BO_ 2566827518  "Wheel Application Pressure High Range Information";
CM_ BO_ 2566832126  "Wheel Speed Information";
CM_ BO_ 2565865982  "Electronic Brake Controller 1";
CM_ BO_ 2565867262  "Electronic Axle Controller 1";
CM_ BO_ 2566821118  "Engine Auxiliary Coolant";
CM_ BO_ 2566810622  "Driver's Identification";
CM_ BO_ 2566847742  "Dash Display";
CM_ BO_ 2566811902  "Combination Vehicle Weight";
CM_ BO_ 2563768062  "Continuous Torque & Speed Limit Request";
CM_ BO_ 2633924862  "Combustion Time 6";
CM_ BO_ 2633924606  "Combustion Time 5";
CM_ BO_ 2633924350  "Combustion Time 4";
CM_ BO_ 2633924094  "Combustion Time 3";
CM_ BO_ 2633923838  "Combustion Time 2";
CM_ BO_ 2633923582  "Combustion Time 1";
CM_ BO_ 2633878014  "Electronic Control Module Information";
CM_ BO_ 2566771966  "Cab Message 3";
CM_ BO_ 2564882174  "Cab Message 1";
CM_ BO_ 2563833598  "Cab Illumination Message";
CM_ BO_ 2566843390  "Component Identification";
CM_ BO_ 2566844926  "Cruise Control/Vehicle Speed";
CM_ BO_ 2566843902  "Cruise Control/Vehicle Speed Setup";
CM_ BO_ 2566809598  "Climate Control Configuration";
CM_ BO_ 2633940222  "Compression/Service Brake Information";
CM_ BO_ 2566775294  "Cab A/C Climate System Information";
CM_ BO_ 2566803710  "Battery Temperature";
CM_ BO_ 2365400830  "Basic Joystick Message 9";
CM_ BO_ 2365401342  "Basic Joystick Message 8";
CM_ BO_ 2365401854  "Basic Joystick Message 7";
CM_ BO_ 2365402366  "Basic Joystick Message 6";
CM_ BO_ 2365402878  "Basic Joystick Message 5";
CM_ BO_ 2365403390  "Basic Joystick Message 4";
CM_ SG_ 2365446142 Jystck1GripXAxisDetentPosStatus "Reports when the current joystick grip position is in the detent position for that axis of travel.";
CM_ SG_ 2365446142 Jystck1GripYAxisDetentPosStatus "Reports when the current joystick grip position is in the detent position for that axis of travel.";
CM_ SG_ 2365446142 Jystck1ThetaAxisDetentPosStatus "Reports when the current joystick position is in the detent position for that axis of travel.";
CM_ SG_ 2365446142 Joystick1ThetaAxisPos "The position of the joystick in the relative motion of travel from the neutral position.";
CM_ SG_ 2365446142 Jystck1ThtAxsClckwsPstvPsStatus "Reports when the current joystick position is on the positive travel side (forward, right, clockwise, up) relative to the";
CM_ SG_ 2365446142 Jystck1ThtaAxisNeutralPosStatus "Reports when the current joystick position is in the neutral position for that axis of travel.";
CM_ SG_ 2365446142 Joystick1GripYAxisPos "The position of the joystick grip in the relative motion of travel from the neutral position.";
CM_ SG_ 2365446142 Jystck1GrpYAxsLvrFrwrdPstvPsStts "Reports when the current joystick grip position is on the positive travel side (forward, right, clockwise, up) relative to the";
CM_ SG_ 2365446142 Jystck1GrpYAxsLvrBckNgtvPsSttus "Reports when the current joystick grip position is on the negative travel side (back, left, counterclockwise, down) relative";
CM_ SG_ 2365446142 Jystck1GrpYAxisNeutralPosStatus "Reports when the current joystick grip position is in the neutral position for that axis of travel.";
CM_ SG_ 2365446142 Joystick1GripXAxisPos "The position of the joystick grip in the relative motion of travel from the neutral position.";
CM_ SG_ 2365446142 Jystck1GrpXAxsLvrRghtPstvPsStts "Reports when the current joystick grip position is on the positive travel side (forward, right, clockwise, up) relative to the";
CM_ SG_ 2365446142 Jystck1GrpXAxsLvrLftNgtvPsSttus "Reports when the current joystick grip position is on the negative travel side (back, left, counterclockwise, down) relative";
CM_ SG_ 2365446142 Jystck1GrpXAxisNeutralPosStatus "Reports when the current joystick grip position is in the neutral position for that axis of travel.";
CM_ SG_ 2365446142 Jystck1ThtAxsCntrClckwsNgtvPsStt "Reports when the current joystick position is on the negative travel side (back, left, counterclockwise, down) relative to the";
CM_ SG_ 2633929470 EngFuelRackPos "Measured position of the engine fuel rack.";
CM_ SG_ 2633929470 EngGasMassFlowRate1 "Gas mass flow rate delivered to an engine through its first fuel control system.";
CM_ SG_ 2633929470 InstantaneousEstBrakePower "Estimate of the power developed by the engine.";
CM_ SG_ 2633929470 EngExhaustGasPress "Gage pressure of the exhaust gasses as measured at the turbine intake of the turbocharger.";
CM_ SG_ 2633929470 EngPrefilterOilPress "Gage pressure of the engine oil before the oil reaches the oil filter.";
CM_ SG_ 2633937406 TotalECURunTime "Total time accumulated over the life of the ECU, from ignition switch ON to ignition switch OFF.";
CM_ SG_ 2633937406 TotalECUDistance "Total distance accumulated over the life of the ECU.";
CM_ SG_ 2364541694 EngIntakeAirMassFlowRate "Mass flow rate of fresh air entering the engine air intake, before any EGR mixer, if used.";
CM_ SG_ 2364541694 EngExhstGsRcrclton2MassFlowRate "Flow rate of gas through the second EGR system.";
CM_ SG_ 2364541694 EngExhstGsRcrclton1MassFlowRate "Flow rate of gas through the EGR system.";
CM_ SG_ 2566810366 FuelPumpPrimerStatus "Parameter used to transmit the actual status of the fuel priming system.";
CM_ SG_ 2566810366 EngFuelSupplyPumpIntakePress "Absolute pressure of fuel at the fuel supply pump intake.";
CM_ SG_ 2566810366 EngFuelFilterDiffPress "Differential pressure measured across the fuel filter located between the fuel tank and the supply pump.";
CM_ SG_ 2566810366 EngOilLevelRemoteReservoir "Ratio of current volume of engine oil in a remote reservoir to the maximum required volume.";
CM_ SG_ 2566810366 EngWasteOilReservoirLevel "Level of crankcase blowby emulsion collected by a container.";
CM_ SG_ 2566810366 EngVentilationStatus "Engine ventilation control states.";
CM_ SG_ 2566810366 EngOilPrimingState "Determination of whether or not the engine is (or has recently been) sufficiently lubricated for starting purposes.";
CM_ SG_ 2566810366 EngOilPrimingPumpSwitch "Switch input for activating the engine oil priming pump.";
CM_ SG_ 2566810366 EngOilPreHeatedState "Indicates whether the engine oil pre-heated sufficiently for starting purposes.";
CM_ SG_ 2566810366 EngOilFilterOutletPress "Oil pressure (gauge) measured just downstream of oil filter.";
CM_ SG_ 2566810366 EngCoolantPreheatedState "Indicates whether the engine coolant is pre-heated sufficiently for starting purposes.";
CM_ SG_ 2633929726 TurningGearEngaged "Status signal which indicates that the turning gear is engaged.";
CM_ SG_ 2633929726 SafetyWireStatus "Status signal which indicates that the safety wire has been activated.";
CM_ SG_ 2633929726 ElectricalLoad "Electrical power delivered by the engine to the electrical system connected to the generator.";
CM_ SG_ 2566772222 EngVrableGeometryTurbo1CtrlMode "Indicates if the variable geometry turbocharger control status is either open loop or closed loop.";
CM_ SG_ 2566772222 EngTrb1ClcltedTurbineIntakeTemp "Calculated value of turbine intake temperature based on engine operating conditions, such as intake manifold";
CM_ SG_ 2566772222 EngExhstGsRcrculation1ValveCtrl "Desired percentage of maximum Exhaust Gas Recirculation (EGR) valve opening.";
CM_ SG_ 2566772222 EngVrblGometryTurbo1ActuatorPos "Sensor that measures the position of the variable geometry turbocharger actuator.";
CM_ SG_ 2566772222 EngVrblGmtryTrbArCtrlShtffValve "Isolates vehicle brake air from the Variable Geometry Turbocharger (VGT) system when engine is not running.";
CM_ SG_ 2566772222 EngTrb1ClcltedTurbineOutletTemp "Calculated value of turbocharger compressor outlet air temperature.";
CM_ SG_ 2633940734 EngRotationDirection "Direction of engine rotation, as reported by the engine.";
CM_ SG_ 2633940734 CrnkAttmptCntOnPrsntStrtAttempt "Reports the number of cranking cycles undergone during the present start attempt.";
CM_ SG_ 2633940734 EngIntakeManifoldPressCtrlMode "Indicates that the Boost Pressure Closed Loop Control status either open loop or closed loop.";
CM_ SG_ 2633940734 EngRatedSpeed "The maximum governed rotational velocity of the engine crankshaft under full load conditions.";
CM_ SG_ 2633940734 EngRatedPower "Net brake power that the engine will deliver continuously, specified for a given application at a rated speed.";
CM_ SG_ 2566840318 EngsDsrdOprtngSpdAsymmtryAdjstmn "This byte is utilized in transmission gear selection routines and indicates the engine's preference of lower versus higher";
CM_ SG_ 2566840318 Aftrtratment1ExhaustGasMassFlow "Measured/calculated exhaust gas mass upstream of the aftertreatment system in exhaust bank 1 and 2.";
CM_ SG_ 2566840318 Aftertreatment2IntakeDewPoint "Indicates that the temperature on the intake side of the aftertreatment system has exceeded the dew point, as estimated";
CM_ SG_ 2566840318 Aftertreatment2ExhaustDewPoint "Indicates that the temperature on the exhaust side of the aftertreatment has exceeded the dew point, as estimated by the";
CM_ SG_ 2566840318 Aftertreatment1IntakeDewPoint "Indicates that the temperature on the intake side of the aftertreatment system has exceeded the dew point, as estimated";
CM_ SG_ 2566840318 Aftertreatment1ExhaustDewPoint "Indicates that the temperature on the exhaust side of the aftertreatment has exceeded the dew point, as estimated by the";
CM_ SG_ 2566840318 EstEngPrsticLossesPercentTorque "The calculated torque that indicates the estimated amount of torque loss due to engine parasitics, such as cooling fan, air";
CM_ SG_ 2566840318 EngsDesiredOperatingSpeed "An indication by the engine of the optimal operating speed of the engine for the current existing conditions.";
CM_ SG_ 2566840318 NominalFrictionPercentTorque "The calculated torque that indicates the amount of torque required by the basic engine itself added by the loss torque of";
CM_ SG_ 2364539902 SCRThermalManagementActive "Indicates that the exhaust temperatures have been elevated for regeneration of the SCR aftertreatment system or in";
CM_ SG_ 2364539902 MmntryEngMaxPowerEnableFeedback "Momentarily requesting Engine Maximum Power Enable - feature support feedback";
CM_ SG_ 2364539902 EstPumpingPercentTorque "The calculated torque that indicates the estimated amount of torque loss due to the engine air handling system.";
CM_ SG_ 2364539902 DPFThermalManagementActive "Indicates that the exhaust temperatures have been elevated for regeneration of the diesel particulate filter aftertreatment";
CM_ SG_ 2364539902 ActlMxAvailableEngPercentTorque "This is the maximum amount of torque that the engine can immediately deliver as a percentage of the reference engine";
CM_ SG_ 2364539902 AccelPedalPos2 "The ratio of actual position of the second analog engine speed/torque request input device (such as an accelerator pedal";
CM_ SG_ 2364539902 VhclAccelerationRateLimitStatus "Status (active or not active) of the system used to limit maximum forward vehicle acceleration.";
CM_ SG_ 2364539902 EngPercentLoadAtCurrentSpeed "The ratio of actual engine percent torque (indicated) to maximum indicated torque available at the current engine speed,";
CM_ SG_ 2364539902 AccelPedal2LowIdleSwitch "Switch signal which indicates the state of the accelerator pedal 2 low idle switch.";
CM_ SG_ 2364539902 RoadSpeedLimitStatus "Status (active or not active) of the system used to limit maximum vehicle velocity.";
CM_ SG_ 2364539902 AccelPedalKickdownSwitch "Switch signal which indicates whether the accelerator pedal kickdown switch is opened or closed.";
CM_ SG_ 2364539902 AccelPedal1LowIdleSwitch "Switch signal which indicates the state of the accelerator pedal 1 low idle switch.";
CM_ SG_ 2364539902 RemoteAccelPedalPos "The ratio of actual position of the remote analog engine speed/torque request input device (such as an accelerator pedal";
CM_ SG_ 2364539902 AccelPedalPos1 "The ratio of actual position of the analog engine speed/torque request input device (such as an accelerator pedal or";
CM_ SG_ 2364540158 SrcAddrssOfCtrllngDvcFrEngCntrl "The source address of the SAE J1939 device currently controlling the engine.";
CM_ SG_ 2364540158 ActlEngPrcntTrqueHighResolution "This parameter displays an additional torque in percent of the reference engine torque.";
CM_ SG_ 2364540158 EngDemandPercentTorque "The requested torque output of the engine by all dynamic internal inputs, including smoke control, noise control and low";
CM_ SG_ 2364540158 EngStarterMode "There are several phases in a starting action and different reasons why a start cannot take place.";
CM_ SG_ 2364540158 EngSpeed "Actual engine speed which is calculated over a minimum crankshaft angle of 720 degrees divided by the number of cylinders.";
CM_ SG_ 2364540158 ActualEngPercentTorque "The calculated output torque of the engine.";
CM_ SG_ 2364540158 DriversDemandEngPercentTorque "The requested torque output of the engine by the driver.";
CM_ SG_ 2364540158 EngTorqueMode "State signal which indicates which engine torque mode is currently generating, limiting, or controlling the torque.";
CM_ SG_ 2566804734 EngLwLmtThrshldFrMxTrqFrmEngine "Minimum allowable value for maximum continuous torque from engine";
CM_ SG_ 2566804734 EngLwLmtThrshldFrMxRPMFrmEngine "Minimum allowable value for maximum continuous RPM from engine";
CM_ SG_ 2566804734 EngHghLmtThrshldFrMnCntnsTrqFrmE "Maximum allowable value for minimum continuous torque from engine";
CM_ SG_ 2566804734 EngHghLmtThrshldFrMnCntnsEngnRPM "Maximum allowable value for minimum continuous RPM from engine";
CM_ SG_ 2566804734 EngMinContinuousTorque "Applied limit for minimum continuous engine torque";
CM_ SG_ 2566804734 EngMaxContinuousTorque "Applied limit for maximum continuous engine torque.";
CM_ SG_ 2566804734 EngMinContinuousRPM "Applied limit for minimum continuous engine RPM";
CM_ SG_ 2566804734 EngMaxContinuousRPM "Applied limit for maximum continuous engine RPM";
CM_ SG_ 2566841342 SupportTSC1CtrlPurposeGroup4 "This parameter indicates which TSC1 control purposes are supported in group 4 of 4.";
CM_ SG_ 2566841342 SupportTSC1CtrlPurposeGroup3 "This parameter indicates which TSC1 control purposes are supported in group 3 of 4.";
CM_ SG_ 2566841342 SupportTSC1CtrlPurposeGroup2 "This parameter indicates which TSC1 control purposes are supported in group 2 of 4.";
CM_ SG_ 2566841342 SupportTSC1CtrlPurposeGroup1 "This parameter indicates which TSC1 control purposes are supported in group 1 of 4.";
CM_ SG_ 2566841342 SupportVariableRateTSC1Message "This parameter indicates which TSC1 transmission rates are supported by the engine ECU in addition to the required";
CM_ SG_ 2566841342 EngDefaultTorqueLimit "Companion parameter to Transmission Torque Limit (SPN 1845).";
CM_ SG_ 2566841342 EngMomentOfInertia "Moment of inertia for the engine, including items driven full-time by the engine such as fuel, oil and cooling pumps.";
CM_ SG_ 2566841342 EngExRngRqdSpdCtrlRngUpperLimit "The maximum engine speed regardless of load that the engine will allow when operating in a speed control/limit mode,";
CM_ SG_ 2566841342 EngRqdTorqueCtrlRangeUpperLimit "The maximum engine torque that the engine will allow when operating in a torque control/limit mode.";
CM_ SG_ 2566841342 EngRqdTorqueCtrlRangeLowerLimit "The minimum engine torque that the engine will allow when operating in a torque control/limit mode.";
CM_ SG_ 2566841342 EngRqedSpeedCtrlRangeUpperLimit "The maximum engine speed regardless of load that the engine will allow when operating in a speed control/limit mode,";
CM_ SG_ 2566841342 EngRqedSpeedCtrlRangeLowerLimit "The minimum engine speed that the engine will allow when operating in a speed control/limit mode.";
CM_ SG_ 2566841342 EngMxMomentaryOverrideTimeLimit "The maximum time limit allowed to override the engine's high idle speed.";
CM_ SG_ 2566841342 EngMxMmntaryOverrideSpeedPoint7 "The maximum engine speed above high idle allowed by the engine control during a momentary high idle override.";
CM_ SG_ 2566841342 EngReferenceTorque "This parameter is the 100% reference value for all defined indicated engine torque parameters.";
CM_ SG_ 2566841342 EngSpeedAtHighIdlePoint6 "Engine speed of high idle (point 6) of the engine torque map (see PGN 65251 and supporting document).";
CM_ SG_ 2566841342 EngGainOfEndspeedGovernor "The endspeed governor is defined as a linear line with the following equations (Capital letters mean physical values, small";
CM_ SG_ 2566841342 EngPercentTorqueAtPoint5 "The torque limit that indicates the available engine torque which can be provided by the engine at point 3, 4, and 5 of the";
CM_ SG_ 2566841342 EngSpeedAtPoint5 "Engine speed of point 3, 4, and 5 of the engine torque map (see PGN 65251 and supporting document).";
CM_ SG_ 2566841342 EngPercentTorqueAtPoint4 "The torque limit that indicates the available engine torque which can be provided by the engine at point 3, 4, and 5 of the";
CM_ SG_ 2566841342 EngSpeedAtPoint4 "Engine speed of point 3, 4, and 5 of the engine torque map (see PGN 65251 and supporting document).";
CM_ SG_ 2566841342 EngPercentTorqueAtPoint3 "The torque limit that indicates the available engine torque which can be provided by the engine at point 3, 4, and 5 of the";
CM_ SG_ 2566841342 EngSpeedAtPoint3 "Engine speed of point 3, 4, and 5 of the engine torque map (see PGN 65251 and supporting document).";
CM_ SG_ 2566841342 EngPercentTorqueAtPoint2 "The torque limit that indicates the available engine torque which can be provided by the engine at point 2 of the engine";
CM_ SG_ 2566841342 EngSpeedAtPoint2 "Engine speed of point 2 of the engine torque map (see PGN 65251 and supporting document).";
CM_ SG_ 2566841342 EngPercentTorqueAtIdlePoint1 "The torque limit that indicates the available engine torque which can be provided by the engine at idle speed.";
CM_ SG_ 2566841342 EngSpeedAtIdlePoint1 "Stationary low idle speed of engine which includes influences due to engine temperature (after power up) and other";
CM_ SG_ 2566767870 BrakeTempWarning "This parameter indicates if the temperature in the service brakes exceeds a certain value.";
CM_ SG_ 2566767870 PrkngBrkeActuatorFullyActivated "Signal which indicates when the parking brake actuator is fully activated.";
CM_ SG_ 2566767870 XBRAccelerationLimit "The brake system may temporarily or generally limit the maximum brake performance available for external systems.";
CM_ SG_ 2566767870 XBRActiveCtrlMode "This parameter indicates which XBR Control Mode is executed by the brake system.";
CM_ SG_ 2566767870 XBRSystemState "This parameter indicates which external brake control is allowed.";
CM_ SG_ 2566767870 FoundationBrakeUse "This parameter indicates if the brake system presently uses the foundation brakes.";
CM_ SG_ 2566767870 HillHolderMode "Signal which indicates the current mode of the hill holder function.";
CM_ SG_ 2566767870 HaltBrakeMode "Signal which indicates the current mode of the halt brake function.";
CM_ SG_ 2633936126 BrkLnngRmnngRearAxle3RightWheel "The percentage of brake lining which can still be measured for the right wheel on the rear axle #3.";
CM_ SG_ 2633936126 BrkLnngRmningRearAxle3LeftWheel "The percentage of brake lining which can still be measured for the left wheel on the rear axle #3.";
CM_ SG_ 2633936126 BrkLnngRmnngRearAxle2RightWheel "The percentage of brake lining which can still be measured for the right wheel on the rear axle #2.";
CM_ SG_ 2633936126 BrkLnngRmningRearAxle2LeftWheel "The percentage of brake lining which can still be measured for the left wheel on the rear axle #2.";
CM_ SG_ 2633936126 BrkLnngRmnngRearAxle1RightWheel "The percentage of brake lining which can still be measured for the right wheel on the rear axle #1.";
CM_ SG_ 2633936126 BrkLnngRmningRearAxle1LeftWheel "The percentage of brake lining which can still be measured for the left wheel on the rear axle #1.";
CM_ SG_ 2633936126 BrkLnngRmnngFrontAxleRightWheel "The percentage of brake lining which can still be measured for the right wheel on the front axle.";
CM_ SG_ 2633936126 BrkLnngRmningFrontAxleLeftWheel "The percentage of brake lining which can still be measured for the left wheel on the front axle.";
CM_ SG_ 2566827518 BrkAppPrssHghRngRrAxl3RghtWheel "The brake application pressure for the right wheel on the rear axle #3.";
CM_ SG_ 2566827518 BrkAppPrssHghRngRrAxl3LeftWheel "The brake application pressure for the left wheel on the rear axle #3.";
CM_ SG_ 2566827518 BrkAppPrssHghRngRrAxl2RghtWheel "The brake application pressure for the right wheel on the rear axle #2.";
CM_ SG_ 2566827518 BrkAppPrssHghRngRrAxl2LeftWheel "The brake application pressure for the left wheel on the rear axle #2.";
CM_ SG_ 2566827518 BrkAppPrssHghRngRrAxl1RghtWheel "The brake application pressure for the right wheel on the rear axle #1.";
CM_ SG_ 2566827518 BrkAppPrssHghRngRrAxl1LeftWheel "The brake application pressure for the left wheel on the rear axle #1.";
CM_ SG_ 2566827518 BrkAppPrssHghRngFrntAxlRghtWhel "The brake application pressure for the right wheel on the front axle.";
CM_ SG_ 2566827518 BrkAppPrssHghRngFrntAxlLftWheel "The brake application pressure for the left wheel on the front axle.";
CM_ SG_ 2566832126 RlativeSpeedRearAxle2RightWheel "The speed of the rear axle #2, right wheel relative to the front axle speed, SPN 904.";
CM_ SG_ 2566832126 RelativeSpeedRearAxle2LeftWheel "The speed of the rear axle #2, left wheel relative to the front axle speed, SPN 904.";
CM_ SG_ 2566832126 RlativeSpeedRearAxle1RightWheel "The speed of the rear axle #1, right wheel relative to the front axle speed, SPN 904.";
CM_ SG_ 2566832126 RelativeSpeedRearAxle1LeftWheel "The speed of the rear axle #1, left wheel relative to the front axle speed, SPN 904.";
CM_ SG_ 2566832126 RlativeSpeedFrontAxleRightWheel "The speed of the front axle, right wheel relative to the front axle speed, SPN 904.";
CM_ SG_ 2566832126 RelativeSpeedFrontAxleLeftWheel "The speed of the front axle, left wheel relative to the front axle speed, SPN 904.";
CM_ SG_ 2566832126 FrontAxleSpeed "The average speed of the two front wheels.";
CM_ SG_ 2565865982 EngAuxShutdownSwitch "Switch signal which requests that all engine fueling stop.";
CM_ SG_ 2565865982 SrcAddrssOfCtrllngDvcFrBrkCntrl "The source address of the SAE J1939 device currently controlling the brake system.";
CM_ SG_ 2565865982 BrakePedalPos "Ratio of brake pedal position to maximum pedal position.";
CM_ SG_ 2565865982 TrctrMntdTrilerABSWarningSignal "This parameter commands the tractor-mounted trailer ABS optical warning signal.";
CM_ SG_ 2565865982 TrailerABSStatus "State signal which indicates that ABS in the trailer is actively controlling the brakes.";
CM_ SG_ 2565865982 HaltBrakeSwitch "Switch signal which indicates the position of the halt brake switch.";
CM_ SG_ 2565865982 ATC_ASRInformationSignal "This parameter commands the ATC/ASR driver information signal, for example a dash lamp.";
CM_ SG_ 2565865982 ABS_EBSAmberWarningSignal "This parameter commands the ABS/EBS amber/yellow optical warning signal";
CM_ SG_ 2565865982 EBSRedWarningSignal "This parameter commands the EBS red optical warning signal";
CM_ SG_ 2565865982 ABSFullyOperational "Signal which indicates whether an ABS system is fully operational or whether its functionality is reduced by a defect or by";
CM_ SG_ 2565865982 EngRetarderSelection "The position of the operator controlled selector, expressed as a percentage and determined by the ratio of the current";
CM_ SG_ 2565865982 RemoteAccelEnableSwitch "Switch signal which indicates that the remote accelerator has been enabled and controls the engine.";
CM_ SG_ 2565865982 EngDerateSwitch "Switch signal used to activate the torque limiting feature of the engine.";
CM_ SG_ 2565865982 AccelInterlockSwitch "Switch signal used to disable the accelerator and remote accelerator inputs, causing the engine to return to idle.";
CM_ SG_ 2565865982 TractionCtrlOverrideSwitch "Switch signal which indicates the position of the traction control override switch.";
CM_ SG_ 2565865982 ASRHillHolderSwitch "Switch signal which indicates the position of the ASR [hill holder] switch.";
CM_ SG_ 2565865982 ASROffroadSwitch "Switch signal which indicates the position of the ASR off-road switch.";
CM_ SG_ 2565865982 ABSOffroadSwitch "Switch signal which indicates the position of the ABS off-road switch.";
CM_ SG_ 2565865982 EBSBrakeSwitch "Switch signal which indicates that the brake pedal is being pressed.";
CM_ SG_ 2565865982 AntiLockBrakingActive "State signal which indicates that the ABS is active.";
CM_ SG_ 2565865982 ASRBrakeCtrlActive "State signal which indicates that ASR brake control is active.";
CM_ SG_ 2565865982 ASREngCtrlActive "State signal which indicates that ASR engine control has been commanded to be active.";
CM_ SG_ 2565867262 RearAxleGroupEngagementStatus "Rear axle group engagement status";
CM_ SG_ 2565867262 FrontAxleGroupEngagementStatus "Front axle group engagement status";
CM_ SG_ 2565867262 DiffLockStateCentralRear "State used which indicates the condition of the central rear differential lock.";
CM_ SG_ 2565867262 DiffLockStateCentralFront "State used which indicates the condition of the central front differential lock.";
CM_ SG_ 2565867262 DiffLockStateCentral "State used which indicates the condition of the central differential lock.";
CM_ SG_ 2565867262 DiffLockStateRearAxle2 "State used which indicates the condition of the rear axle 2 differential lock.";
CM_ SG_ 2565867262 DiffLockStateRearAxle1 "State used which indicates the condition of the rear axle 1 differential lock.";
CM_ SG_ 2565867262 DiffLockStateFrontAxle2 "State used which indicates the condition of the front axle 2 differential lock.";
CM_ SG_ 2565867262 DiffLockStateFrontAxle1 "State used which indicates the condition of the front axle 1 differential lock.";
CM_ SG_ 2565867262 Location "To identify to which of several similar devices (such as tires or fuel tanks) the information applies.";
CM_ SG_ 2566821118 SeaWaterPumpOutletPress "Gauge pressure of liquid found at outlet of sea water pump in sea water cooling system.";
CM_ SG_ 2566821118 EngAuxCoolantTemp "Temperature of coolant found in the intercooler which is located after the turbocharger.";
CM_ SG_ 2566821118 EngAuxCoolantPress "Gage pressure of coolant found in the intercooler which is located after the turbocharger.";
CM_ SG_ 2566847742 FuelLevel2 "Ratio of volume of fuel to the total volume of fuel in the second or right-side storage container.";
CM_ SG_ 2566847742 FuelLevel1 "Ratio of volume of fuel to the total volume of fuel storage container.";
CM_ SG_ 2566847742 CargoAmbientTemp "Temperature of air inside vehicle container used to accommodate cargo.";
CM_ SG_ 2566847742 EngOilFilterDiffPress "Change in engine oil pressure, measured across the filter, due to the filter and any accumulation of solid or semisolid";
CM_ SG_ 2566847742 EngFuelFilterDiffPress "Differential pressure measured across the fuel filter located between the fuel tank and the supply pump.";
CM_ SG_ 2566847742 WasherFluidLevel "Ratio of volume of liquid to total container volume of fluid reservoir in windshield wash system.";
CM_ SG_ 2566811902 PoweredVehicleWeight "Total mass imposed by the tires of the powered vehicle on the road surface.";
CM_ SG_ 2566811902 GrossCombinationVehicleWeight "The total weight of the truck and all attached trailers.";
CM_ SG_ 2563768062 MxCntnuousRetarderTorqueLimitRq "Requested maximum continuous retarder torque (operating range: -125 to 0%)";
CM_ SG_ 2563768062 MnCntnuousRetarderTorqueLimitRq "Requested minimum continuous retarder torque (operating range: -125 to 0%)";
CM_ SG_ 2563768062 MxCntinuousRetarderSpeedLimitRq "Requested maximum continuous retarder speed";
CM_ SG_ 2563768062 MnCntinuousRetarderSpeedLimitRq "Requested minimum continuous retarder speed";
CM_ SG_ 2563768062 EngTorqueLimitRqMaxContinuous "Requested maximum continuous engine torque (operating range: 0 to 125%)";
CM_ SG_ 2563768062 EngTorqueLimitRqMinContinuous "Requested minimum continuous engine torque (operating range: 0 to 125%)";
CM_ SG_ 2563768062 EngSpeedLimitRqMaxContinuous "Requested maximum continuous engine speed";
CM_ SG_ 2563768062 EngSpeedLimitRqMinContinuous "Requested minimum continuous engine speed";
CM_ SG_ 2633924862 EngAverageCombustionTime "The average combustion time of all cylinders of an engine.";
CM_ SG_ 2633924862 EngDesiredCombustionTime "The desired combustion time based upon engine load and speed lookup maps.";
CM_ SG_ 2633924606 EngCyl20CombustionTime "The amount of time from when the ignition of the fuel is initiated to when the fuel is completely ignited (i.";
CM_ SG_ 2633924606 EngCyl19CombustionTime "The amount of time from when the ignition of the fuel is initiated to when the fuel is completely ignited (i.";
CM_ SG_ 2633924606 EngCyl18CombustionTime "The amount of time from when the ignition of the fuel is initiated to when the fuel is completely ignited (i.";
CM_ SG_ 2633924606 EngCyl17CombustionTime "The amount of time from when the ignition of the fuel is initiated to when the fuel is completely ignited (i.";
CM_ SG_ 2633924350 EngCyl16CombustionTime "The amount of time from when the ignition of the fuel is initiated to when the fuel is completely ignited (i.";
CM_ SG_ 2633924350 EngCyl15CombustionTime "The amount of time from when the ignition of the fuel is initiated to when the fuel is completely ignited (i.";
CM_ SG_ 2633924350 EngCyl14CombustionTime "The amount of time from when the ignition of the fuel is initiated to when the fuel is completely ignited (i.";
CM_ SG_ 2633924350 EngCyl13CombustionTime "The amount of time from when the ignition of the fuel is initiated to when the fuel is completely ignited (i.";
CM_ SG_ 2633924094 EngCyl12CombustionTime "The amount of time from when the ignition of the fuel is initiated to when the fuel is completely ignited (i.";
CM_ SG_ 2633924094 EngCyl11CombustionTime "The amount of time from when the ignition of the fuel is initiated to when the fuel is completely ignited (i.";
CM_ SG_ 2633924094 EngCyl10CombustionTime "The amount of time from when the ignition of the fuel is initiated to when the fuel is completely ignited (i.";
CM_ SG_ 2633924094 EngCyl9CombustionTime "The amount of time from when the ignition of the fuel is initiated to when the fuel is completely ignited (i.";
CM_ SG_ 2633923838 EngCyl8CombustionTime "The amount of time from when the ignition of the fuel is initiated to when the fuel is completely ignited (i.";
CM_ SG_ 2633923838 EngCyl7CombustionTime "The amount of time from when the ignition of the fuel is initiated to when the fuel is completely ignited (i.";
CM_ SG_ 2633923838 EngCyl6CombustionTime "The amount of time from when the ignition of the fuel is initiated to when the fuel is completely ignited (i.";
CM_ SG_ 2633923838 EngCyl5CombustionTime "The amount of time from when the ignition of the fuel is initiated to when the fuel is completely ignited (i.";
CM_ SG_ 2633923582 EngCyl4CombustionTime "The amount of time from when the ignition of the fuel is initiated to when the fuel is completely ignited (i.";
CM_ SG_ 2633923582 EngCyl3CombustionTime "The amount of time from when the ignition of the fuel is initiated to when the fuel is completely ignited (i.";
CM_ SG_ 2633923582 EngCyl2CombustionTime "The amount of time from when the ignition of the fuel is initiated to when the fuel is completely ignited (i.";
CM_ SG_ 2633923582 EngCyl1CombustionTime "The amount of time from when the ignition of the fuel is initiated to when the fuel is completely ignited (i.";
CM_ SG_ 2633878014 TotalCountOfConfigChangesMade "Total number of times changes have been made to any of the configurable parameters.";
CM_ SG_ 2566771966 TransOilLevelRq "Conveys operator or vehicle system desire for a transmission oil level reading to be taken.";
CM_ SG_ 2566771966 FifthWheelReleaseCtrl "Operator input used to release the fifth wheel.";
CM_ SG_ 2566771966 FfthWhlRlaseCtrlSecurityLockout "Operator's fifth wheel release control interlock.";
CM_ SG_ 2566771966 TransferCaseSelectorSwitch "Operator switch to select the condition of the transfer case.";
CM_ SG_ 2564882174 DslPrtcltFltrRgnrtonForceSwitch "Indicates the state of a switch available to the operator that forces diesel particulate filter regeneration.";
CM_ SG_ 2564882174 DslPrtcltFltrRgnrtnInhbitSwitch "Indicates the state of a switch available to the operator that inhibits diesel particulate filter regeneration.";
CM_ SG_ 2564882174 SelectedMaxVehicleSpeedLimit "User selected maximum vehicle speed.";
CM_ SG_ 2564882174 RqCabZoneHeating "Request to activate cab zone heating.";
CM_ SG_ 2564882174 RqEngZoneHeating "Request to activate engine zone heating.";
CM_ SG_ 2564882174 AuxHeaterModeRq "Request to activate the auxiliary heater.";
CM_ SG_ 2564882174 EngAutomaticStartEnableSwitch "Switch signal which enables the idle management system to be enabled.";
CM_ SG_ 2564882174 AtmaticGearShiftingEnableSwitch "Indicates that automated gear shifting is enabled via a switch";
CM_ SG_ 2564882174 VhclLmtngSpdGvernorEnableSwitch "Switch signal which enables the Vehicle Limiting Speed Governor (VLSG) such that the vehicle speed may be either";
CM_ SG_ 2564882174 VhclLmtngSpdGvrnrIncrmentSwitch "Switch signal which increases the Vehicle Limiting Speed Governor (VLSG).";
CM_ SG_ 2564882174 VhclLmtngSpdGvrnrDcrementSwitch "Switch signal which decreases the Vehicle Limiting Speed Governor (VLSG).";
CM_ SG_ 2564882174 SeatBeltSwitch "State of switch used to determine if Seat Belt is buckled";
CM_ SG_ 2564882174 OperatorSeatDirectionSwitch "Senses whether the operator seat is in the forward driving position";
CM_ SG_ 2564882174 BatteryMainSwitchHoldRq "Request to hold the battery main switch.";
CM_ SG_ 2564882174 AuxHeaterCoolantPumpRq "Indicates whether to activate the auxiliary heater coolant water pump.";
CM_ SG_ 2564882174 CabInteriorTempCmd "Parameter used to command a certain cab interior temperature.";
CM_ SG_ 2564882174 RqedPercentFanSpeed "Fan speed as a ratio of the actual fan drive (current speed) to the fully engaged fan drive (maximum fan speed).";
CM_ SG_ 2563833598 IlluminationBrightnessPercent "Commanded backlight brightness level for all cab displays";
CM_ SG_ 2566844926 ParkBrakeReleaseInhibitRq "Park Brake Release Inhibit Request signals the desire that an applied park brake remain applied and limit the ability of the";
CM_ SG_ 2566844926 PTOGovernorState "This parameter is used to indicate the current state or mode of operation by the power takeoff (PTO) governor.";
CM_ SG_ 2566844926 EngShutdownOverrideSwitch "Switch signal which indicates the position of the engine shutdown override switch.";
CM_ SG_ 2566844926 EngTestModeSwitch "Switch signal which indicates the position of the engine test mode switch.";
CM_ SG_ 2566844926 EngIdleDecrementSwitch "Switch signal which indicates the position of the idle decrement switch.";
CM_ SG_ 2566844926 EngIdleIncrementSwitch "Switch signal which indicates the position of the idle increment switch.";
CM_ SG_ 2566844926 CruiseCtrlStates "This parameter is used to indicate the current state, or mode, of operation by the cruise control device.";
CM_ SG_ 2566844926 CruiseCtrlSetSpeed "Value of set (chosen) velocity of velocity control system.";
CM_ SG_ 2566844926 CruiseCtrlAccelerateSwitch "Switch signal of the cruise control activator which indicates that the activator is in the position [accelerate.";
CM_ SG_ 2566844926 CruiseCtrlResumeSwitch "Switch signal of the cruise control activator which indicates that the activator is in the position [resume.";
CM_ SG_ 2566844926 CruiseCtrlCoastSwitch "Switch signal of the cruise control activator which indicates that the activator is in the position [coast (decelerate).";
CM_ SG_ 2566844926 CruiseCtrlSetSwitch "Switch signal of the cruise control activator which indicates that the activator is in the position [set.";
CM_ SG_ 2566844926 ClutchSwitch "Switch signal which indicates that the clutch pedal is being pressed.";
CM_ SG_ 2566844926 BrakeSwitch "Switch signal which indicates that the driver operated brake foot pedal is being pressed.";
CM_ SG_ 2566844926 CruiseCtrlEnableSwitch "Switch signal which indicates that it is possible to manage the cruise control function.";
CM_ SG_ 2566844926 CruiseCtrlActive "Cruise control is switched on.";
CM_ SG_ 2566844926 WheelBasedVehicleSpeed "Speed of the vehicle as calculated from wheel or tailshaft speed.";
CM_ SG_ 2566844926 CruiseCtrlPauseSwitch "Switch signal which indicates the position of the Cruise Control Pause Switch used on Remote Cruise Control applications.";
CM_ SG_ 2566844926 ParkingBrakeSwitch "Switch signal which indicates when the parking brake is set.";
CM_ SG_ 2566844926 TwoSpeedAxleSwitch "Switch signal which indicates the current axle range.";
CM_ SG_ 2566843902 CruiseCtrlLowSetLimitSpeed "Minimum vehicle velocity at which cruise can be set or minimum vehicle velocity for cruise operation before it will exit";
CM_ SG_ 2566843902 CruiseCtrlHighSetLimitSpeed "Maximum vehicle velocity at which cruise can be set.";
CM_ SG_ 2566843902 MaxVehicleSpeedLimit "Maximum vehicle velocity allowed.";
CM_ SG_ 2566809598 AuxHeaterMaxOutputPower "The maximum output power of the auxiliary heater.";
CM_ SG_ 2633940222 TripServiceBrakeApps "Total number of times the service brakes have been activated since the last trip reset.";
CM_ SG_ 2633940222 TripServiceBrakeDistance "Total distance over which the service brakes have been active since the last trip reset.";
CM_ SG_ 2633940222 TripCompressionBrakeDistance "Total distance over which the compression brakes have been active since the last trip reset.";
CM_ SG_ 2633940222 TotalCompressionBrakeDistance "Total distance over which the compression brakes have been active for the life of the engine.";
CM_ SG_ 2566775294 CbA_CRfrgrntCmprssorOutletPress "This is the gage pressure at the compressor outlet in the cab air conditioning system.";
CM_ SG_ 2566803710 Battery2Temp "Temperature of the battery 2.";
CM_ SG_ 2566803710 Battery1Temp "Temperature of the battery 1.";
CM_ SG_ 2365400830 Joystick9Button9PressedStatus "Reports when the joystick button has been pressed.";
CM_ SG_ 2365400830 Joystick9Button10PressedStatus "Reports when the joystick button has been pressed.";
CM_ SG_ 2365400830 Joystick9Button11PressedStatus "Reports when the joystick button has been pressed.";
CM_ SG_ 2365400830 Joystick9Button12PressedStatus "Reports when the joystick button has been pressed.";
CM_ SG_ 2365400830 Joystick9Button5PressedStatus "Reports when the joystick button has been pressed.";
CM_ SG_ 2365400830 Joystick9Button6PressedStatus "Reports when the joystick button has been pressed.";
CM_ SG_ 2365400830 Joystick9Button7PressedStatus "Reports when the joystick button has been pressed.";
CM_ SG_ 2365400830 Joystick9Button8PressedStatus "Reports when the joystick button has been pressed.";
CM_ SG_ 2365400830 Joystick9Button1PressedStatus "Reports when the joystick button has been pressed.";
CM_ SG_ 2365400830 Joystick9Button2PressedStatus "Reports when the joystick button has been pressed.";
CM_ SG_ 2365400830 Joystick9Button3PressedStatus "Reports when the joystick button has been pressed.";
CM_ SG_ 2365400830 Joystick9Button4PressedStatus "Reports when the joystick button has been pressed.";
CM_ SG_ 2365400830 Joystick9XAxisDetentPosStatus "Reports when the current joystick position is in the detent position for that axis of travel.";
CM_ SG_ 2365400830 Joystick9YAxisDetentPosStatus "Reports when the current joystick position is in the detent position for that axis of travel.";
CM_ SG_ 2365400830 Joystick9YAxisPos "The position of the joystick in the relative motion of travel from the neutral position.";
CM_ SG_ 2365400830 Jystck9YAxsLvrFrwrdPstvPsStatus "Reports when the current joystick position is on the positive travel side (forward, right, clockwise, up) relative to the";
CM_ SG_ 2365400830 Jystck9YAxsLvrBckNgtvePosStatus "Reports when the current joystick position is on the negative travel side (back, left, counterclockwise, down) relative to the";
CM_ SG_ 2365400830 Joystick9YAxisNeutralPosStatus "Reports when the current joystick position is in the neutral position for that axis of travel.";
CM_ SG_ 2365400830 Joystick9XAxisPos "The position of the joystick in the relative motion of travel from the neutral position.";
CM_ SG_ 2365400830 Jystck9XAxsLvrRghtPstvPosStatus "Reports when the current joystick position is on the positive travel side (forward, right, clockwise, up) relative to the";
CM_ SG_ 2365400830 Jystck9XAxsLvrLftNgtvePosStatus "Reports when the current joystick position is on the negative travel side (back, left, counterclockwise, down) relative to the";
CM_ SG_ 2365400830 Joystick9XAxisNeutralPosStatus "Reports when the current joystick position is in the neutral position for that axis of travel.";
CM_ SG_ 2365401342 Joystick8Button9PressedStatus "Reports when the joystick button has been pressed.";
CM_ SG_ 2365401342 Joystick8Button10PressedStatus "Reports when the joystick button has been pressed.";
CM_ SG_ 2365401342 Joystick8Button11PressedStatus "Reports when the joystick button has been pressed.";
CM_ SG_ 2365401342 Joystick8Button12PressedStatus "Reports when the joystick button has been pressed.";
CM_ SG_ 2365401342 Joystick8Button5PressedStatus "Reports when the joystick button has been pressed.";
CM_ SG_ 2365401342 Joystick8Button6PressedStatus "Reports when the joystick button has been pressed.";
CM_ SG_ 2365401342 Joystick8Button7PressedStatus "Reports when the joystick button has been pressed.";
CM_ SG_ 2365401342 Joystick8Button8PressedStatus "Reports when the joystick button has been pressed.";
CM_ SG_ 2365401342 Joystick8Button1PressedStatus "Reports when the joystick button has been pressed.";
CM_ SG_ 2365401342 Joystick8Button2PressedStatus "Reports when the joystick button has been pressed.";
CM_ SG_ 2365401342 Joystick8Button3PressedStatus "Reports when the joystick button has been pressed.";
CM_ SG_ 2365401342 Joystick8Button4PressedStatus "Reports when the joystick button has been pressed.";
CM_ SG_ 2365401342 Joystick8XAxisDetentPosStatus "Reports when the current joystick position is in the detent position for that axis of travel.";
CM_ SG_ 2365401342 Joystick8YAxisDetentPosStatus "Reports when the current joystick position is in the detent position for that axis of travel.";
CM_ SG_ 2365401342 Joystick8YAxisPos "The position of the joystick in the relative motion of travel from the neutral position.";
CM_ SG_ 2365401342 Jystck8YAxsLvrFrwrdPstvPsStatus "Reports when the current joystick position is on the positive travel side (forward, right, clockwise, up) relative to the";
CM_ SG_ 2365401342 Jystck8YAxsLvrBckNgtvePosStatus "Reports when the current joystick position is on the negative travel side (back, left, counterclockwise, down) relative to the";
CM_ SG_ 2365401342 Joystick8YAxisNeutralPosStatus "Reports when the current joystick position is in the neutral position for that axis of travel.";
CM_ SG_ 2365401342 Joystick8XAxisPos "The position of the joystick in the relative motion of travel from the neutral position.";
CM_ SG_ 2365401342 Jystck8XAxsLvrRghtPstvPosStatus "Reports when the current joystick position is on the positive travel side (forward, right, clockwise, up) relative to the";
CM_ SG_ 2365401342 Jystck8XAxsLvrLftNgtvePosStatus "Reports when the current joystick position is on the negative travel side (back, left, counterclockwise, down) relative to the";
CM_ SG_ 2365401342 Joystick8XAxisNeutralPosStatus "Reports when the current joystick position is in the neutral position for that axis of travel.";
CM_ SG_ 2365401854 Joystick7Button9PressedStatus "Reports when the joystick button has been pressed.";
CM_ SG_ 2365401854 Joystick7Button10PressedStatus "Reports when the joystick button has been pressed.";
CM_ SG_ 2365401854 Joystick7Button11PressedStatus "Reports when the joystick button has been pressed.";
CM_ SG_ 2365401854 Joystick7Button12PressedStatus "Reports when the joystick button has been pressed.";
CM_ SG_ 2365401854 Joystick7Button5PressedStatus "Reports when the joystick button has been pressed.";
CM_ SG_ 2365401854 Joystick7Button6PressedStatus "Reports when the joystick button has been pressed.";
CM_ SG_ 2365401854 Joystick7Button7PressedStatus "Reports when the joystick button has been pressed.";
CM_ SG_ 2365401854 Joystick7Button8PressedStatus "Reports when the joystick button has been pressed.";
CM_ SG_ 2365401854 Joystick7Button1PressedStatus "Reports when the joystick button has been pressed.";
CM_ SG_ 2365401854 Joystick7Button2PressedStatus "Reports when the joystick button has been pressed.";
CM_ SG_ 2365401854 Joystick7Button3PressedStatus "Reports when the joystick button has been pressed.";
CM_ SG_ 2365401854 Joystick7Button4PressedStatus "Reports when the joystick button has been pressed.";
CM_ SG_ 2365401854 Joystick7XAxisDetentPosStatus "Reports when the current joystick position is in the detent position for that axis of travel.";
CM_ SG_ 2365401854 Joystick7YAxisDetentPosStatus "Reports when the current joystick position is in the detent position for that axis of travel.";
CM_ SG_ 2365401854 Joystick7YAxisPos "The position of the joystick in the relative motion of travel from the neutral position.";
CM_ SG_ 2365401854 Jystck7YAxsLvrFrwrdPstvPsStatus "Reports when the current joystick position is on the positive travel side (forward, right, clockwise, up) relative to the";
CM_ SG_ 2365401854 Jystck7YAxsLvrBckNgtvePosStatus "Reports when the current joystick position is on the negative travel side (back, left, counterclockwise, down) relative to the";
CM_ SG_ 2365401854 Joystick7YAxisNeutralPosStatus "Reports when the current joystick position is in the neutral position for that axis of travel.";
CM_ SG_ 2365401854 Joystick7XAxisPos "The position of the joystick in the relative motion of travel from the neutral position.";
CM_ SG_ 2365401854 Jystck7XAxsLvrRghtPstvPosStatus "Reports when the current joystick position is on the positive travel side (forward, right, clockwise, up) relative to the";
CM_ SG_ 2365401854 Jystck7XAxsLvrLftNgtvePosStatus "Reports when the current joystick position is on the negative travel side (back, left, counterclockwise, down) relative to the";
CM_ SG_ 2365401854 Joystick7XAxisNeutralPosStatus "Reports when the current joystick position is in the neutral position for that axis of travel.";
CM_ SG_ 2365402366 Joystick6Button9PressedStatus "Reports when the joystick button has been pressed.";
CM_ SG_ 2365402366 Joystick6Button10PressedStatus "Reports when the joystick button has been pressed.";
CM_ SG_ 2365402366 Joystick6Button11PressedStatus "Reports when the joystick button has been pressed.";
CM_ SG_ 2365402366 Joystick6Button12PressedStatus "Reports when the joystick button has been pressed.";
CM_ SG_ 2365402366 Joystick6Button5PressedStatus "Reports when the joystick button has been pressed.";
CM_ SG_ 2365402366 Joystick6Button6PressedStatus "Reports when the joystick button has been pressed.";
CM_ SG_ 2365402366 Joystick6Button7PressedStatus "Reports when the joystick button has been pressed.";
CM_ SG_ 2365402366 Joystick6Button8PressedStatus "Reports when the joystick button has been pressed.";
CM_ SG_ 2365402366 Joystick6Button1PressedStatus "Reports when the joystick button has been pressed.";
CM_ SG_ 2365402366 Joystick6Button2PressedStatus "Reports when the joystick button has been pressed.";
CM_ SG_ 2365402366 Joystick6Button3PressedStatus "Reports when the joystick button has been pressed.";
CM_ SG_ 2365402366 Joystick6Button4PressedStatus "Reports when the joystick button has been pressed.";
CM_ SG_ 2365402366 Joystick6XAxisDetentPosStatus "Reports when the current joystick position is in the detent position for that axis of travel.";
CM_ SG_ 2365402366 Joystick6YAxisDetentPosStatus "Reports when the current joystick position is in the detent position for that axis of travel.";
CM_ SG_ 2365402366 Joystick6YAxisPos "The position of the joystick in the relative motion of travel from the neutral position.";
CM_ SG_ 2365402366 Jystck6YAxsLvrFrwrdPstvPsStatus "Reports when the current joystick position is on the positive travel side (forward, right, clockwise, up) relative to the";
CM_ SG_ 2365402366 Jystck6YAxsLvrBckNgtvePosStatus "Reports when the current joystick position is on the negative travel side (back, left, counterclockwise, down) relative to the";
CM_ SG_ 2365402366 Joystick6YAxisNeutralPosStatus "Reports when the current joystick position is in the neutral position for that axis of travel.";
CM_ SG_ 2365402366 Joystick6XAxisPos "The position of the joystick in the relative motion of travel from the neutral position.";
CM_ SG_ 2365402366 Jystck6XAxsLvrRghtPstvPosStatus "Reports when the current joystick position is on the positive travel side (forward, right, clockwise, up) relative to the";
CM_ SG_ 2365402366 Jystck6XAxsLvrLftNgtvePosStatus "Reports when the current joystick position is on the negative travel side (back, left, counterclockwise, down) relative to the";
CM_ SG_ 2365402366 Joystick6XAxisNeutralPosStatus "Reports when the current joystick position is in the neutral position for that axis of travel.";
CM_ SG_ 2365402878 Joystick5Button9PressedStatus "Reports when the joystick button has been pressed.";
CM_ SG_ 2365402878 Joystick5Button10PressedStatus "Reports when the joystick button has been pressed.";
CM_ SG_ 2365402878 Joystick5Button11PressedStatus "Reports when the joystick button has been pressed.";
CM_ SG_ 2365402878 Joystick5Button12PressedStatus "Reports when the joystick button has been pressed.";
CM_ SG_ 2365402878 Joystick5Button5PressedStatus "Reports when the joystick button has been pressed.";
CM_ SG_ 2365402878 Joystick5Button6PressedStatus "Reports when the joystick button has been pressed.";
CM_ SG_ 2365402878 Joystick5Button7PressedStatus "Reports when the joystick button has been pressed.";
CM_ SG_ 2365402878 Joystick5Button8PressedStatus "Reports when the joystick button has been pressed.";
CM_ SG_ 2365402878 Joystick5Button1PressedStatus "Reports when the joystick button has been pressed.";
CM_ SG_ 2365402878 Joystick5Button2PressedStatus "Reports when the joystick button has been pressed.";
CM_ SG_ 2365402878 Joystick5Button3PressedStatus "Reports when the joystick button has been pressed.";
CM_ SG_ 2365402878 Joystick5Button4PressedStatus "Reports when the joystick button has been pressed.";
CM_ SG_ 2365402878 Joystick5XAxisDetentPosStatus "Reports when the current joystick position is in the detent position for that axis of travel.";
CM_ SG_ 2365402878 Joystick5YAxisDetentPosStatus "Reports when the current joystick position is in the detent position for that axis of travel.";
CM_ SG_ 2365402878 Joystick5YAxisPos "The position of the joystick in the relative motion of travel from the neutral position.";
CM_ SG_ 2365402878 Jystck5YAxsLvrFrwrdPstvPsStatus "Reports when the current joystick position is on the positive travel side (forward, right, clockwise, up) relative to the";
CM_ SG_ 2365402878 Jystck5YAxsLvrBckNgtvePosStatus "Reports when the current joystick position is on the negative travel side (back, left, counterclockwise, down) relative to the";
CM_ SG_ 2365402878 Joystick5YAxisNeutralPosStatus "Reports when the current joystick position is in the neutral position for that axis of travel.";
CM_ SG_ 2365402878 Joystick5XAxisPos "The position of the joystick in the relative motion of travel from the neutral position.";
CM_ SG_ 2365402878 Jystck5XAxsLvrRghtPstvPosStatus "Reports when the current joystick position is on the positive travel side (forward, right, clockwise, up) relative to the";
CM_ SG_ 2365402878 Jystck5XAxsLvrLftNgtvePosStatus "Reports when the current joystick position is on the negative travel side (back, left, counterclockwise, down) relative to the";
CM_ SG_ 2365402878 Joystick5XAxisNeutralPosStatus "Reports when the current joystick position is in the neutral position for that axis of travel.";
CM_ SG_ 2365403390 Joystick4Button9PressedStatus "Reports when the joystick button has been pressed.";
CM_ SG_ 2365403390 Joystick4Button10PressedStatus "Reports when the joystick button has been pressed.";
CM_ SG_ 2365403390 Joystick4Button11PressedStatus "Reports when the joystick button has been pressed.";
CM_ SG_ 2365403390 Joystick4Button12PressedStatus "Reports when the joystick button has been pressed.";
CM_ SG_ 2365403390 Joystick4Button5PressedStatus "Reports when the joystick button has been pressed.";
CM_ SG_ 2365403390 Joystick4Button6PressedStatus "Reports when the joystick button has been pressed.";
CM_ SG_ 2365403390 Joystick4Button7PressedStatus "Reports when the joystick button has been pressed.";
CM_ SG_ 2365403390 Joystick4Button8PressedStatus "Reports when the joystick button has been pressed.";
CM_ SG_ 2365403390 Joystick4Button1PressedStatus "Reports when the joystick button has been pressed.";
CM_ SG_ 2365403390 Joystick4Button2PressedStatus "Reports when the joystick button has been pressed.";
CM_ SG_ 2365403390 Joystick4Button3PressedStatus "Reports when the joystick button has been pressed.";
CM_ SG_ 2365403390 Joystick4Button4PressedStatus "Reports when the joystick button has been pressed.";
CM_ SG_ 2365403390 Joystick4XAxisDetentPosStatus "Reports when the current joystick position is in the detent position for that axis of travel.";
CM_ SG_ 2365403390 Joystick4YAxisDetentPosStatus "Reports when the current joystick position is in the detent position for that axis of travel.";
CM_ SG_ 2365403390 Joystick4YAxisPos "The position of the joystick in the relative motion of travel from the neutral position.";
CM_ SG_ 2365403390 Jystck4YAxsLvrFrwrdPstvPsStatus "Reports when the current joystick position is on the positive travel side (forward, right, clockwise, up) relative to the";
CM_ SG_ 2365403390 Jystck4YAxsLvrBckNgtvePosStatus "Reports when the current joystick position is on the negative travel side (back, left, counterclockwise, down) relative to the";
CM_ SG_ 2365403390 Joystick4YAxisNeutralPosStatus "Reports when the current joystick position is in the neutral position for that axis of travel.";
CM_ SG_ 2365403390 Joystick4XAxisPos "The position of the joystick in the relative motion of travel from the neutral position.";
CM_ SG_ 2365403390 Jystck4XAxsLvrRghtPstvPosStatus "Reports when the current joystick position is on the positive travel side (forward, right, clockwise, up) relative to the";
CM_ SG_ 2365403390 Jystck4XAxsLvrLftNgtvePosStatus "Reports when the current joystick position is on the negative travel side (back, left, counterclockwise, down) relative to the";
CM_ SG_ 2365403390 Joystick4XAxisNeutralPosStatus "Reports when the current joystick position is in the neutral position for that axis of travel.";

BA_DEF_ BO_ "GenMsgCycleTime" INT 0 3600000;
BA_DEF_ BO_ "GenMsgSendType" ENUM  "cyclic","reserved","cyclicIfActive","reserved","reserved","reserved","reserved","reserved","noMsgSendType";
BA_DEF_ BO_ "GenMsgStartDelayTime" INT 0 100000;
BA_DEF_ BO_ "VFrameFormat" ENUM  "StandardCAN","ExtendedCAN","reserved","J1939PG";
BA_DEF_ SG_ "GenSigStartValue" INT 0 10000;
BA_DEF_ SG_ "SPN" INT 0 524287;
BA_DEF_ SG_ "SigType" ENUM  "Default","Range","RangeSigned","ASCII","Discrete","Control","ReferencePGN","DTC","StringDelimiter","StringLength","StringLengthControl";
BA_DEF_ SG_ "SystemSignalLongSymbol" STRING;
BA_DEF_DEF_ "GenMsgCycleTime" 0;
BA_DEF_DEF_ "GenMsgSendType" "noMsgSendType";
BA_DEF_DEF_ "GenMsgStartDelayTime" 0;
BA_DEF_DEF_ "GenSigStartValue" 0;
BA_DEF_DEF_ "SPN" 0;
BA_DEF_DEF_ "SigType" "Default";
BA_DEF_DEF_ "VFrameFormat" "J1939PG";
BA_ "GenMsgCycleTime" BO_ 2365446142 100;
BA_ "GenMsgSendType" BO_ 2365446142 0;
BA_ "GenMsgCycleTime" BO_ 2633929470 100;
BA_ "GenMsgSendType" BO_ 2633929470 0;
BA_ "GenMsgCycleTime" BO_ 2364541694 50;
BA_ "GenMsgSendType" BO_ 2364541694 0;
BA_ "GenMsgCycleTime" BO_ 2566810366 500;
BA_ "GenMsgSendType" BO_ 2566810366 0;
BA_ "GenMsgCycleTime" BO_ 2633929726 100;
BA_ "GenMsgSendType" BO_ 2633929726 0;
BA_ "GenMsgCycleTime" BO_ 2566840318 250;
BA_ "GenMsgSendType" BO_ 2566840318 0;
BA_ "GenMsgCycleTime" BO_ 2364539902 50;
BA_ "GenMsgSendType" BO_ 2364539902 0;
BA_ "GenMsgCycleTime" BO_ 2364540158 100;
BA_ "GenMsgSendType" BO_ 2364540158 0;
BA_ "GenMsgCycleTime" BO_ 2566804734 5000;
BA_ "GenMsgSendType" BO_ 2566804734 0;
BA_ "GenMsgCycleTime" BO_ 2566767870 100;
BA_ "GenMsgSendType" BO_ 2566767870 0;
BA_ "GenMsgCycleTime" BO_ 2566827518 100;
BA_ "GenMsgSendType" BO_ 2566827518 0;
BA_ "GenMsgCycleTime" BO_ 2566832126 100;
BA_ "GenMsgSendType" BO_ 2566832126 0;
BA_ "GenMsgCycleTime" BO_ 2565865982 100;
BA_ "GenMsgSendType" BO_ 2565865982 0;
BA_ "GenMsgCycleTime" BO_ 2565867262 500;
BA_ "GenMsgSendType" BO_ 2565867262 0;
BA_ "GenMsgCycleTime" BO_ 2566821118 500;
BA_ "GenMsgSendType" BO_ 2566821118 0;
BA_ "GenMsgCycleTime" BO_ 2566847742 1000;
BA_ "GenMsgSendType" BO_ 2566847742 0;
BA_ "GenMsgCycleTime" BO_ 2563768062 5000;
BA_ "GenMsgSendType" BO_ 2563768062 0;
BA_ "GenMsgCycleTime" BO_ 2564882174 1000;
BA_ "GenMsgSendType" BO_ 2564882174 0;
BA_ "GenMsgCycleTime" BO_ 2566844926 100;
BA_ "GenMsgSendType" BO_ 2566844926 0;
BA_ "GenMsgCycleTime" BO_ 2566775294 1000;
BA_ "GenMsgSendType" BO_ 2566775294 0;
BA_ "GenMsgCycleTime" BO_ 2566803710 1000;
BA_ "GenMsgSendType" BO_ 2566803710 0;
BA_ "SPN" SG_ 2365446142 Jystck1GripXAxisDetentPosStatus 2682;
BA_ "SigType" SG_ 2365446142 Jystck1GripXAxisDetentPosStatus 4;
BA_ "SPN" SG_ 2365446142 Jystck1GripYAxisDetentPosStatus 2683;
BA_ "SigType" SG_ 2365446142 Jystck1GripYAxisDetentPosStatus 4;
BA_ "SPN" SG_ 2365446142 Jystck1ThetaAxisDetentPosStatus 2684;
BA_ "SigType" SG_ 2365446142 Jystck1ThetaAxisDetentPosStatus 4;
BA_ "SPN" SG_ 2365446142 Joystick1ThetaAxisPos 2664;
BA_ "SigType" SG_ 2365446142 Joystick1ThetaAxisPos 1;
BA_ "SPN" SG_ 2365446142 Jystck1ThtAxsClckwsPstvPsStatus 2669;
BA_ "SigType" SG_ 2365446142 Jystck1ThtAxsClckwsPstvPsStatus 4;
BA_ "SPN" SG_ 2365446142 Jystck1ThtaAxisNeutralPosStatus 2679;
BA_ "SigType" SG_ 2365446142 Jystck1ThtaAxisNeutralPosStatus 4;
BA_ "SPN" SG_ 2365446142 Joystick1GripYAxisPos 2663;
BA_ "SigType" SG_ 2365446142 Joystick1GripYAxisPos 1;
BA_ "SPN" SG_ 2365446142 Jystck1GrpYAxsLvrFrwrdPstvPsStts 2668;
BA_ "SigType" SG_ 2365446142 Jystck1GrpYAxsLvrFrwrdPstvPsStts 4;
BA_ "SPN" SG_ 2365446142 Jystck1GrpYAxsLvrBckNgtvPsSttus 2673;
BA_ "SigType" SG_ 2365446142 Jystck1GrpYAxsLvrBckNgtvPsSttus 4;
BA_ "SPN" SG_ 2365446142 Jystck1GrpYAxisNeutralPosStatus 2678;
BA_ "SigType" SG_ 2365446142 Jystck1GrpYAxisNeutralPosStatus 4;
BA_ "SPN" SG_ 2365446142 Joystick1GripXAxisPos 2662;
BA_ "SigType" SG_ 2365446142 Joystick1GripXAxisPos 1;
BA_ "SPN" SG_ 2365446142 Jystck1GrpXAxsLvrRghtPstvPsStts 2667;
BA_ "SigType" SG_ 2365446142 Jystck1GrpXAxsLvrRghtPstvPsStts 4;
BA_ "SPN" SG_ 2365446142 Jystck1GrpXAxsLvrLftNgtvPsSttus 2672;
BA_ "SigType" SG_ 2365446142 Jystck1GrpXAxsLvrLftNgtvPsSttus 4;
BA_ "SPN" SG_ 2365446142 Jystck1GrpXAxisNeutralPosStatus 2677;
BA_ "SigType" SG_ 2365446142 Jystck1GrpXAxisNeutralPosStatus 4;
BA_ "SPN" SG_ 2365446142 Jystck1ThtAxsCntrClckwsNgtvPsStt 2674;
BA_ "SigType" SG_ 2365446142 Jystck1ThtAxsCntrClckwsNgtvPsStt 4;
BA_ "SystemSignalLongSymbol" SG_ 2365446142 Jystck1ThtAxsCntrClckwsNgtvPsStt "Jystck1ThtAxsCntrClckwsNgtvPsStts";
BA_ "SPN" SG_ 2633929470 EngFuelRackPos 1210;
BA_ "SigType" SG_ 2633929470 EngFuelRackPos 1;
BA_ "SPN" SG_ 2633929470 EngGasMassFlowRate1 1241;
BA_ "SigType" SG_ 2633929470 EngGasMassFlowRate1 1;
BA_ "SPN" SG_ 2633929470 InstantaneousEstBrakePower 1242;
BA_ "SigType" SG_ 2633929470 InstantaneousEstBrakePower 1;
BA_ "SPN" SG_ 2633929470 EngExhaustGasPress 1209;
BA_ "SigType" SG_ 2633929470 EngExhaustGasPress 1;
BA_ "SPN" SG_ 2633929470 EngPrefilterOilPress 1208;
BA_ "SigType" SG_ 2633929470 EngPrefilterOilPress 1;
BA_ "SPN" SG_ 2633937406 TotalECURunTime 1033;
BA_ "SigType" SG_ 2633937406 TotalECURunTime 1;
BA_ "SPN" SG_ 2633937406 TotalECUDistance 1032;
BA_ "SigType" SG_ 2633937406 TotalECUDistance 1;
BA_ "SPN" SG_ 2364541694 EngIntakeAirMassFlowRate 132;
BA_ "SigType" SG_ 2364541694 EngIntakeAirMassFlowRate 1;
BA_ "SPN" SG_ 2364541694 EngExhstGsRcrclton2MassFlowRate 5257;
BA_ "SigType" SG_ 2364541694 EngExhstGsRcrclton2MassFlowRate 1;
BA_ "SPN" SG_ 2364541694 EngExhstGsRcrclton1MassFlowRate 2659;
BA_ "SigType" SG_ 2364541694 EngExhstGsRcrclton1MassFlowRate 1;
BA_ "SPN" SG_ 2566810366 FuelPumpPrimerStatus 4083;
BA_ "SigType" SG_ 2566810366 FuelPumpPrimerStatus 4;
BA_ "SPN" SG_ 2566810366 EngFuelSupplyPumpIntakePress 1381;
BA_ "SigType" SG_ 2566810366 EngFuelSupplyPumpIntakePress 1;
BA_ "SPN" SG_ 2566810366 EngFuelFilterDiffPress 1382;
BA_ "SigType" SG_ 2566810366 EngFuelFilterDiffPress 1;
BA_ "SPN" SG_ 2566810366 EngOilLevelRemoteReservoir 1380;
BA_ "SigType" SG_ 2566810366 EngOilLevelRemoteReservoir 1;
BA_ "SPN" SG_ 2566810366 EngWasteOilReservoirLevel 3548;
BA_ "SigType" SG_ 2566810366 EngWasteOilReservoirLevel 1;
BA_ "SPN" SG_ 2566810366 EngVentilationStatus 3554;
BA_ "SPN" SG_ 2566810366 EngOilPrimingState 3551;
BA_ "SigType" SG_ 2566810366 EngOilPrimingState 4;
BA_ "SPN" SG_ 2566810366 EngOilPrimingPumpSwitch 3550;
BA_ "SigType" SG_ 2566810366 EngOilPrimingPumpSwitch 4;
BA_ "SPN" SG_ 2566810366 EngOilPreHeatedState 3552;
BA_ "SigType" SG_ 2566810366 EngOilPreHeatedState 4;
BA_ "SPN" SG_ 2566810366 EngOilFilterOutletPress 3549;
BA_ "SigType" SG_ 2566810366 EngOilFilterOutletPress 1;
BA_ "SPN" SG_ 2566810366 EngCoolantPreheatedState 3553;
BA_ "SigType" SG_ 2566810366 EngCoolantPreheatedState 4;
BA_ "SPN" SG_ 2633929726 TurningGearEngaged 1206;
BA_ "SigType" SG_ 2633929726 TurningGearEngaged 4;
BA_ "SPN" SG_ 2633929726 SafetyWireStatus 1205;
BA_ "SigType" SG_ 2633929726 SafetyWireStatus 4;
BA_ "SPN" SG_ 2633929726 ElectricalLoad 1204;
BA_ "SigType" SG_ 2633929726 ElectricalLoad 1;
BA_ "SPN" SG_ 2566772222 EngVrableGeometryTurbo1CtrlMode 5457;
BA_ "SigType" SG_ 2566772222 EngVrableGeometryTurbo1CtrlMode 4;
BA_ "SPN" SG_ 2566772222 EngTrb1ClcltedTurbineIntakeTemp 2789;
BA_ "SigType" SG_ 2566772222 EngTrb1ClcltedTurbineIntakeTemp 1;
BA_ "SPN" SG_ 2566772222 EngExhstGsRcrculation1ValveCtrl 2791;
BA_ "SigType" SG_ 2566772222 EngExhstGsRcrculation1ValveCtrl 1;
BA_ "SPN" SG_ 2566772222 EngVrblGometryTurbo1ActuatorPos 2795;
BA_ "SigType" SG_ 2566772222 EngVrblGometryTurbo1ActuatorPos 1;
BA_ "SPN" SG_ 2566772222 EngVrblGmtryTrbArCtrlShtffValve 2792;
BA_ "SigType" SG_ 2566772222 EngVrblGmtryTrbArCtrlShtffValve 4;
BA_ "SPN" SG_ 2566772222 EngTrb1ClcltedTurbineOutletTemp 2790;
BA_ "SigType" SG_ 2566772222 EngTrb1ClcltedTurbineOutletTemp 1;
BA_ "SPN" SG_ 2633940734 EngRotationDirection 3669;
BA_ "SigType" SG_ 2633940734 EngRotationDirection 4;
BA_ "SPN" SG_ 2633940734 CrnkAttmptCntOnPrsntStrtAttempt 3671;
BA_ "SigType" SG_ 2633940734 CrnkAttmptCntOnPrsntStrtAttempt 1;
BA_ "SPN" SG_ 2633940734 EngIntakeManifoldPressCtrlMode 5465;
BA_ "SigType" SG_ 2633940734 EngIntakeManifoldPressCtrlMode 4;
BA_ "SPN" SG_ 2633940734 EngRatedSpeed 189;
BA_ "SigType" SG_ 2633940734 EngRatedSpeed 1;
BA_ "SPN" SG_ 2633940734 EngRatedPower 166;
BA_ "SigType" SG_ 2633940734 EngRatedPower 1;
BA_ "SPN" SG_ 2566840318 EngsDsrdOprtngSpdAsymmtryAdjstmn 519;
BA_ "SigType" SG_ 2566840318 EngsDsrdOprtngSpdAsymmtryAdjstmn 1;
BA_ "SystemSignalLongSymbol" SG_ 2566840318 EngsDsrdOprtngSpdAsymmtryAdjstmn "EngsDsrdOprtngSpdAsymmtryAdjstmnt";
BA_ "SPN" SG_ 2566840318 Aftrtratment1ExhaustGasMassFlow 3236;
BA_ "SigType" SG_ 2566840318 Aftrtratment1ExhaustGasMassFlow 1;
BA_ "SPN" SG_ 2566840318 Aftertreatment2IntakeDewPoint 3239;
BA_ "SigType" SG_ 2566840318 Aftertreatment2IntakeDewPoint 4;
BA_ "SPN" SG_ 2566840318 Aftertreatment2ExhaustDewPoint 3240;
BA_ "SigType" SG_ 2566840318 Aftertreatment2ExhaustDewPoint 4;
BA_ "SPN" SG_ 2566840318 Aftertreatment1IntakeDewPoint 3237;
BA_ "SigType" SG_ 2566840318 Aftertreatment1IntakeDewPoint 4;
BA_ "SPN" SG_ 2566840318 Aftertreatment1ExhaustDewPoint 3238;
BA_ "SigType" SG_ 2566840318 Aftertreatment1ExhaustDewPoint 4;
BA_ "SPN" SG_ 2566840318 EstEngPrsticLossesPercentTorque 2978;
BA_ "SigType" SG_ 2566840318 EstEngPrsticLossesPercentTorque 1;
BA_ "SPN" SG_ 2566840318 EngsDesiredOperatingSpeed 515;
BA_ "SigType" SG_ 2566840318 EngsDesiredOperatingSpeed 1;
BA_ "SPN" SG_ 2566840318 NominalFrictionPercentTorque 514;
BA_ "SigType" SG_ 2566840318 NominalFrictionPercentTorque 1;
BA_ "SPN" SG_ 2364539902 SCRThermalManagementActive 5400;
BA_ "SigType" SG_ 2364539902 SCRThermalManagementActive 4;
BA_ "SPN" SG_ 2364539902 MmntryEngMaxPowerEnableFeedback 5021;
BA_ "SigType" SG_ 2364539902 MmntryEngMaxPowerEnableFeedback 4;
BA_ "SPN" SG_ 2364539902 EstPumpingPercentTorque 5398;
BA_ "SigType" SG_ 2364539902 EstPumpingPercentTorque 1;
BA_ "SPN" SG_ 2364539902 DPFThermalManagementActive 5399;
BA_ "SigType" SG_ 2364539902 DPFThermalManagementActive 4;
BA_ "SPN" SG_ 2364539902 ActlMxAvailableEngPercentTorque 3357;
BA_ "SigType" SG_ 2364539902 ActlMxAvailableEngPercentTorque 1;
BA_ "SPN" SG_ 2364539902 AccelPedalPos2 29;
BA_ "SigType" SG_ 2364539902 AccelPedalPos2 1;
BA_ "SPN" SG_ 2364539902 VhclAccelerationRateLimitStatus 2979;
BA_ "SigType" SG_ 2364539902 VhclAccelerationRateLimitStatus 4;
BA_ "SPN" SG_ 2364539902 EngPercentLoadAtCurrentSpeed 92;
BA_ "SigType" SG_ 2364539902 EngPercentLoadAtCurrentSpeed 1;
BA_ "SPN" SG_ 2364539902 AccelPedal2LowIdleSwitch 2970;
BA_ "SigType" SG_ 2364539902 AccelPedal2LowIdleSwitch 4;
BA_ "SPN" SG_ 2364539902 RoadSpeedLimitStatus 1437;
BA_ "SigType" SG_ 2364539902 RoadSpeedLimitStatus 4;
BA_ "SPN" SG_ 2364539902 AccelPedalKickdownSwitch 559;
BA_ "SigType" SG_ 2364539902 AccelPedalKickdownSwitch 4;
BA_ "SPN" SG_ 2364539902 AccelPedal1LowIdleSwitch 558;
BA_ "SigType" SG_ 2364539902 AccelPedal1LowIdleSwitch 4;
BA_ "SPN" SG_ 2364539902 RemoteAccelPedalPos 974;
BA_ "SigType" SG_ 2364539902 RemoteAccelPedalPos 1;
BA_ "SPN" SG_ 2364539902 AccelPedalPos1 91;
BA_ "SigType" SG_ 2364539902 AccelPedalPos1 1;
BA_ "SPN" SG_ 2364540158 SrcAddrssOfCtrllngDvcFrEngCntrl 1483;
BA_ "SigType" SG_ 2364540158 SrcAddrssOfCtrllngDvcFrEngCntrl 1;
BA_ "SPN" SG_ 2364540158 ActlEngPrcntTrqueHighResolution 4154;
BA_ "SigType" SG_ 2364540158 ActlEngPrcntTrqueHighResolution 1;
BA_ "SPN" SG_ 2364540158 EngDemandPercentTorque 2432;
BA_ "SigType" SG_ 2364540158 EngDemandPercentTorque 1;
BA_ "SPN" SG_ 2364540158 EngStarterMode 1675;
BA_ "SigType" SG_ 2364540158 EngStarterMode 4;
BA_ "SPN" SG_ 2364540158 EngSpeed 190;
BA_ "SigType" SG_ 2364540158 EngSpeed 1;
BA_ "SPN" SG_ 2364540158 ActualEngPercentTorque 513;
BA_ "SigType" SG_ 2364540158 ActualEngPercentTorque 1;
BA_ "SPN" SG_ 2364540158 DriversDemandEngPercentTorque 512;
BA_ "SigType" SG_ 2364540158 DriversDemandEngPercentTorque 1;
BA_ "SPN" SG_ 2364540158 EngTorqueMode 899;
BA_ "SigType" SG_ 2364540158 EngTorqueMode 4;
BA_ "SPN" SG_ 2566768126 ECUType 2904;
BA_ "SigType" SG_ 2566768126 ECUType 8;
BA_ "SPN" SG_ 2566768126 ECULocation 2903;
BA_ "SigType" SG_ 2566768126 ECULocation 8;
BA_ "SPN" SG_ 2566768126 ECUSerialNumber 2902;
BA_ "SigType" SG_ 2566768126 ECUSerialNumber 8;
BA_ "SPN" SG_ 2566768126 ECUPartNumber 2901;
BA_ "SigType" SG_ 2566768126 ECUPartNumber 8;
BA_ "SPN" SG_ 2566804734 EngLwLmtThrshldFrMxTrqFrmEngine 1770;
BA_ "SigType" SG_ 2566804734 EngLwLmtThrshldFrMxTrqFrmEngine 1;
BA_ "SPN" SG_ 2566804734 EngLwLmtThrshldFrMxRPMFrmEngine 1768;
BA_ "SigType" SG_ 2566804734 EngLwLmtThrshldFrMxRPMFrmEngine 1;
BA_ "SPN" SG_ 2566804734 EngHghLmtThrshldFrMnCntnsTrqFrmE 1771;
BA_ "SigType" SG_ 2566804734 EngHghLmtThrshldFrMnCntnsTrqFrmE 1;
BA_ "SystemSignalLongSymbol" SG_ 2566804734 EngHghLmtThrshldFrMnCntnsTrqFrmE "EngHghLmtThrshldFrMnCntnsTrqFrmEngn";
BA_ "SPN" SG_ 2566804734 EngHghLmtThrshldFrMnCntnsEngnRPM 1769;
BA_ "SigType" SG_ 2566804734 EngHghLmtThrshldFrMnCntnsEngnRPM 1;
BA_ "SPN" SG_ 2566804734 EngMinContinuousTorque 1775;
BA_ "SigType" SG_ 2566804734 EngMinContinuousTorque 1;
BA_ "SPN" SG_ 2566804734 EngMaxContinuousTorque 1774;
BA_ "SigType" SG_ 2566804734 EngMaxContinuousTorque 1;
BA_ "SPN" SG_ 2566804734 EngMinContinuousRPM 1773;
BA_ "SigType" SG_ 2566804734 EngMinContinuousRPM 1;
BA_ "SPN" SG_ 2566804734 EngMaxContinuousRPM 1772;
BA_ "SigType" SG_ 2566804734 EngMaxContinuousRPM 1;
BA_ "SPN" SG_ 2566841342 SupportTSC1CtrlPurposeGroup4 3348;
BA_ "SigType" SG_ 2566841342 SupportTSC1CtrlPurposeGroup4 1;
BA_ "SPN" SG_ 2566841342 SupportTSC1CtrlPurposeGroup3 3347;
BA_ "SigType" SG_ 2566841342 SupportTSC1CtrlPurposeGroup3 1;
BA_ "SPN" SG_ 2566841342 SupportTSC1CtrlPurposeGroup2 3346;
BA_ "SigType" SG_ 2566841342 SupportTSC1CtrlPurposeGroup2 1;
BA_ "SPN" SG_ 2566841342 SupportTSC1CtrlPurposeGroup1 3345;
BA_ "SigType" SG_ 2566841342 SupportTSC1CtrlPurposeGroup1 1;
BA_ "SPN" SG_ 2566841342 SupportVariableRateTSC1Message 3344;
BA_ "SigType" SG_ 2566841342 SupportVariableRateTSC1Message 1;
BA_ "SPN" SG_ 2566841342 EngDefaultTorqueLimit 1846;
BA_ "SigType" SG_ 2566841342 EngDefaultTorqueLimit 1;
BA_ "SPN" SG_ 2566841342 EngMomentOfInertia 1794;
BA_ "SigType" SG_ 2566841342 EngMomentOfInertia 1;
BA_ "SPN" SG_ 2566841342 EngExRngRqdSpdCtrlRngUpperLimit 1712;
BA_ "SigType" SG_ 2566841342 EngExRngRqdSpdCtrlRngUpperLimit 1;
BA_ "SPN" SG_ 2566841342 EngRqdTorqueCtrlRangeUpperLimit 538;
BA_ "SigType" SG_ 2566841342 EngRqdTorqueCtrlRangeUpperLimit 1;
BA_ "SPN" SG_ 2566841342 EngRqdTorqueCtrlRangeLowerLimit 537;
BA_ "SigType" SG_ 2566841342 EngRqdTorqueCtrlRangeLowerLimit 1;
BA_ "SPN" SG_ 2566841342 EngRqedSpeedCtrlRangeUpperLimit 536;
BA_ "SigType" SG_ 2566841342 EngRqedSpeedCtrlRangeUpperLimit 1;
BA_ "SPN" SG_ 2566841342 EngRqedSpeedCtrlRangeLowerLimit 535;
BA_ "SigType" SG_ 2566841342 EngRqedSpeedCtrlRangeLowerLimit 1;
BA_ "SPN" SG_ 2566841342 EngMxMomentaryOverrideTimeLimit 534;
BA_ "SigType" SG_ 2566841342 EngMxMomentaryOverrideTimeLimit 1;
BA_ "SPN" SG_ 2566841342 EngMxMmntaryOverrideSpeedPoint7 533;
BA_ "SigType" SG_ 2566841342 EngMxMmntaryOverrideSpeedPoint7 1;
BA_ "SPN" SG_ 2566841342 EngReferenceTorque 544;
BA_ "SigType" SG_ 2566841342 EngReferenceTorque 1;
BA_ "SPN" SG_ 2566841342 EngSpeedAtHighIdlePoint6 532;
BA_ "SigType" SG_ 2566841342 EngSpeedAtHighIdlePoint6 1;
BA_ "SPN" SG_ 2566841342 EngGainOfEndspeedGovernor 545;
BA_ "SigType" SG_ 2566841342 EngGainOfEndspeedGovernor 1;
BA_ "SPN" SG_ 2566841342 EngPercentTorqueAtPoint5 543;
BA_ "SigType" SG_ 2566841342 EngPercentTorqueAtPoint5 1;
BA_ "SPN" SG_ 2566841342 EngSpeedAtPoint5 531;
BA_ "SigType" SG_ 2566841342 EngSpeedAtPoint5 1;
BA_ "SPN" SG_ 2566841342 EngPercentTorqueAtPoint4 542;
BA_ "SigType" SG_ 2566841342 EngPercentTorqueAtPoint4 1;
BA_ "SPN" SG_ 2566841342 EngSpeedAtPoint4 530;
BA_ "SigType" SG_ 2566841342 EngSpeedAtPoint4 1;
BA_ "SPN" SG_ 2566841342 EngPercentTorqueAtPoint3 541;
BA_ "SigType" SG_ 2566841342 EngPercentTorqueAtPoint3 1;
BA_ "SPN" SG_ 2566841342 EngSpeedAtPoint3 529;
BA_ "SigType" SG_ 2566841342 EngSpeedAtPoint3 1;
BA_ "SPN" SG_ 2566841342 EngPercentTorqueAtPoint2 540;
BA_ "SigType" SG_ 2566841342 EngPercentTorqueAtPoint2 1;
BA_ "SPN" SG_ 2566841342 EngSpeedAtPoint2 528;
BA_ "SigType" SG_ 2566841342 EngSpeedAtPoint2 1;
BA_ "SPN" SG_ 2566841342 EngPercentTorqueAtIdlePoint1 539;
BA_ "SigType" SG_ 2566841342 EngPercentTorqueAtIdlePoint1 1;
BA_ "SPN" SG_ 2566841342 EngSpeedAtIdlePoint1 188;
BA_ "SigType" SG_ 2566841342 EngSpeedAtIdlePoint1 1;
BA_ "SPN" SG_ 2566767870 BrakeTempWarning 3839;
BA_ "SigType" SG_ 2566767870 BrakeTempWarning 4;
BA_ "SPN" SG_ 2566767870 PrkngBrkeActuatorFullyActivated 5275;
BA_ "SigType" SG_ 2566767870 PrkngBrkeActuatorFullyActivated 4;
BA_ "SPN" SG_ 2566767870 XBRAccelerationLimit 2921;
BA_ "SigType" SG_ 2566767870 XBRAccelerationLimit 1;
BA_ "SPN" SG_ 2566767870 XBRActiveCtrlMode 2918;
BA_ "SigType" SG_ 2566767870 XBRActiveCtrlMode 4;
BA_ "SPN" SG_ 2566767870 XBRSystemState 2917;
BA_ "SigType" SG_ 2566767870 XBRSystemState 4;
BA_ "SPN" SG_ 2566767870 FoundationBrakeUse 2919;
BA_ "SigType" SG_ 2566767870 FoundationBrakeUse 4;
BA_ "SPN" SG_ 2566767870 HillHolderMode 2912;
BA_ "SPN" SG_ 2566767870 HaltBrakeMode 2913;
BA_ "SPN" SG_ 2633936126 BrkLnngRmnngRearAxle3RightWheel 1106;
BA_ "SigType" SG_ 2633936126 BrkLnngRmnngRearAxle3RightWheel 1;
BA_ "SPN" SG_ 2633936126 BrkLnngRmningRearAxle3LeftWheel 1105;
BA_ "SigType" SG_ 2633936126 BrkLnngRmningRearAxle3LeftWheel 1;
BA_ "SPN" SG_ 2633936126 BrkLnngRmnngRearAxle2RightWheel 1104;
BA_ "SigType" SG_ 2633936126 BrkLnngRmnngRearAxle2RightWheel 1;
BA_ "SPN" SG_ 2633936126 BrkLnngRmningRearAxle2LeftWheel 1103;
BA_ "SigType" SG_ 2633936126 BrkLnngRmningRearAxle2LeftWheel 1;
BA_ "SPN" SG_ 2633936126 BrkLnngRmnngRearAxle1RightWheel 1102;
BA_ "SigType" SG_ 2633936126 BrkLnngRmnngRearAxle1RightWheel 1;
BA_ "SPN" SG_ 2633936126 BrkLnngRmningRearAxle1LeftWheel 1101;
BA_ "SigType" SG_ 2633936126 BrkLnngRmningRearAxle1LeftWheel 1;
BA_ "SPN" SG_ 2633936126 BrkLnngRmnngFrontAxleRightWheel 1100;
BA_ "SigType" SG_ 2633936126 BrkLnngRmnngFrontAxleRightWheel 1;
BA_ "SPN" SG_ 2633936126 BrkLnngRmningFrontAxleLeftWheel 1099;
BA_ "SigType" SG_ 2633936126 BrkLnngRmningFrontAxleLeftWheel 1;
BA_ "SPN" SG_ 2566827518 BrkAppPrssHghRngRrAxl3RghtWheel 1098;
BA_ "SigType" SG_ 2566827518 BrkAppPrssHghRngRrAxl3RghtWheel 1;
BA_ "SPN" SG_ 2566827518 BrkAppPrssHghRngRrAxl3LeftWheel 1097;
BA_ "SigType" SG_ 2566827518 BrkAppPrssHghRngRrAxl3LeftWheel 1;
BA_ "SPN" SG_ 2566827518 BrkAppPrssHghRngRrAxl2RghtWheel 1096;
BA_ "SigType" SG_ 2566827518 BrkAppPrssHghRngRrAxl2RghtWheel 1;
BA_ "SPN" SG_ 2566827518 BrkAppPrssHghRngRrAxl2LeftWheel 1095;
BA_ "SigType" SG_ 2566827518 BrkAppPrssHghRngRrAxl2LeftWheel 1;
BA_ "SPN" SG_ 2566827518 BrkAppPrssHghRngRrAxl1RghtWheel 1094;
BA_ "SigType" SG_ 2566827518 BrkAppPrssHghRngRrAxl1RghtWheel 1;
BA_ "SPN" SG_ 2566827518 BrkAppPrssHghRngRrAxl1LeftWheel 1093;
BA_ "SigType" SG_ 2566827518 BrkAppPrssHghRngRrAxl1LeftWheel 1;
BA_ "SPN" SG_ 2566827518 BrkAppPrssHghRngFrntAxlRghtWhel 1092;
BA_ "SigType" SG_ 2566827518 BrkAppPrssHghRngFrntAxlRghtWhel 1;
BA_ "SPN" SG_ 2566827518 BrkAppPrssHghRngFrntAxlLftWheel 1091;
BA_ "SigType" SG_ 2566827518 BrkAppPrssHghRngFrntAxlLftWheel 1;
BA_ "SPN" SG_ 2566832126 RlativeSpeedRearAxle2RightWheel 910;
BA_ "SigType" SG_ 2566832126 RlativeSpeedRearAxle2RightWheel 1;
BA_ "SPN" SG_ 2566832126 RelativeSpeedRearAxle2LeftWheel 909;
BA_ "SigType" SG_ 2566832126 RelativeSpeedRearAxle2LeftWheel 1;
BA_ "SPN" SG_ 2566832126 RlativeSpeedRearAxle1RightWheel 908;
BA_ "SigType" SG_ 2566832126 RlativeSpeedRearAxle1RightWheel 1;
BA_ "SPN" SG_ 2566832126 RelativeSpeedRearAxle1LeftWheel 907;
BA_ "SigType" SG_ 2566832126 RelativeSpeedRearAxle1LeftWheel 1;
BA_ "SPN" SG_ 2566832126 RlativeSpeedFrontAxleRightWheel 906;
BA_ "SigType" SG_ 2566832126 RlativeSpeedFrontAxleRightWheel 1;
BA_ "SPN" SG_ 2566832126 RelativeSpeedFrontAxleLeftWheel 905;
BA_ "SigType" SG_ 2566832126 RelativeSpeedFrontAxleLeftWheel 1;
BA_ "SPN" SG_ 2566832126 FrontAxleSpeed 904;
BA_ "SigType" SG_ 2566832126 FrontAxleSpeed 1;
BA_ "SPN" SG_ 2565865982 EngAuxShutdownSwitch 970;
BA_ "SigType" SG_ 2565865982 EngAuxShutdownSwitch 4;
BA_ "SPN" SG_ 2565865982 SrcAddrssOfCtrllngDvcFrBrkCntrl 1481;
BA_ "SigType" SG_ 2565865982 SrcAddrssOfCtrllngDvcFrBrkCntrl 1;
BA_ "SPN" SG_ 2565865982 BrakePedalPos 521;
BA_ "SigType" SG_ 2565865982 BrakePedalPos 1;
BA_ "SPN" SG_ 2565865982 TrctrMntdTrilerABSWarningSignal 1792;
BA_ "SigType" SG_ 2565865982 TrctrMntdTrilerABSWarningSignal 4;
BA_ "SPN" SG_ 2565865982 TrailerABSStatus 1836;
BA_ "SigType" SG_ 2565865982 TrailerABSStatus 4;
BA_ "SPN" SG_ 2565865982 HaltBrakeSwitch 2911;
BA_ "SigType" SG_ 2565865982 HaltBrakeSwitch 4;
BA_ "SPN" SG_ 2565865982 ATC_ASRInformationSignal 1793;
BA_ "SigType" SG_ 2565865982 ATC_ASRInformationSignal 4;
BA_ "SPN" SG_ 2565865982 ABS_EBSAmberWarningSignal 1438;
BA_ "SigType" SG_ 2565865982 ABS_EBSAmberWarningSignal 4;
BA_ "SPN" SG_ 2565865982 EBSRedWarningSignal 1439;
BA_ "SigType" SG_ 2565865982 EBSRedWarningSignal 4;
BA_ "SPN" SG_ 2565865982 ABSFullyOperational 1243;
BA_ "SigType" SG_ 2565865982 ABSFullyOperational 4;
BA_ "SPN" SG_ 2565865982 EngRetarderSelection 973;
BA_ "SigType" SG_ 2565865982 EngRetarderSelection 1;
BA_ "SPN" SG_ 2565865982 RemoteAccelEnableSwitch 969;
BA_ "SigType" SG_ 2565865982 RemoteAccelEnableSwitch 4;
BA_ "SPN" SG_ 2565865982 EngDerateSwitch 971;
BA_ "SigType" SG_ 2565865982 EngDerateSwitch 4;
BA_ "SPN" SG_ 2565865982 AccelInterlockSwitch 972;
BA_ "SigType" SG_ 2565865982 AccelInterlockSwitch 4;
BA_ "SPN" SG_ 2565865982 TractionCtrlOverrideSwitch 1238;
BA_ "SigType" SG_ 2565865982 TractionCtrlOverrideSwitch 4;
BA_ "SPN" SG_ 2565865982 ASRHillHolderSwitch 577;
BA_ "SigType" SG_ 2565865982 ASRHillHolderSwitch 4;
BA_ "SPN" SG_ 2565865982 ASROffroadSwitch 576;
BA_ "SigType" SG_ 2565865982 ASROffroadSwitch 4;
BA_ "SPN" SG_ 2565865982 ABSOffroadSwitch 575;
BA_ "SigType" SG_ 2565865982 ABSOffroadSwitch 4;
BA_ "SPN" SG_ 2565865982 EBSBrakeSwitch 1121;
BA_ "SigType" SG_ 2565865982 EBSBrakeSwitch 4;
BA_ "SPN" SG_ 2565865982 AntiLockBrakingActive 563;
BA_ "SigType" SG_ 2565865982 AntiLockBrakingActive 4;
BA_ "SPN" SG_ 2565865982 ASRBrakeCtrlActive 562;
BA_ "SigType" SG_ 2565865982 ASRBrakeCtrlActive 4;
BA_ "SPN" SG_ 2565865982 ASREngCtrlActive 561;
BA_ "SigType" SG_ 2565865982 ASREngCtrlActive 4;
BA_ "SPN" SG_ 2565867262 RearAxleGroupEngagementStatus 3820;
BA_ "SigType" SG_ 2565867262 RearAxleGroupEngagementStatus 4;
BA_ "SPN" SG_ 2565867262 FrontAxleGroupEngagementStatus 3819;
BA_ "SigType" SG_ 2565867262 FrontAxleGroupEngagementStatus 4;
BA_ "SPN" SG_ 2565867262 DiffLockStateCentralRear 566;
BA_ "SigType" SG_ 2565867262 DiffLockStateCentralRear 4;
BA_ "SPN" SG_ 2565867262 DiffLockStateCentralFront 565;
BA_ "SigType" SG_ 2565867262 DiffLockStateCentralFront 4;
BA_ "SPN" SG_ 2565867262 DiffLockStateCentral 564;
BA_ "SigType" SG_ 2565867262 DiffLockStateCentral 4;
BA_ "SPN" SG_ 2565867262 DiffLockStateRearAxle2 570;
BA_ "SigType" SG_ 2565867262 DiffLockStateRearAxle2 4;
BA_ "SPN" SG_ 2565867262 DiffLockStateRearAxle1 569;
BA_ "SigType" SG_ 2565867262 DiffLockStateRearAxle1 4;
BA_ "SPN" SG_ 2565867262 DiffLockStateFrontAxle2 568;
BA_ "SigType" SG_ 2565867262 DiffLockStateFrontAxle2 4;
BA_ "SPN" SG_ 2565867262 DiffLockStateFrontAxle1 567;
BA_ "SigType" SG_ 2565867262 DiffLockStateFrontAxle1 4;
BA_ "SPN" SG_ 2565867262 Location 927;
BA_ "SigType" SG_ 2565867262 Location 1;
BA_ "SPN" SG_ 2566821118 SeaWaterPumpOutletPress 2435;
BA_ "SigType" SG_ 2566821118 SeaWaterPumpOutletPress 1;
BA_ "SPN" SG_ 2566821118 EngAuxCoolantTemp 1212;
BA_ "SigType" SG_ 2566821118 EngAuxCoolantTemp 1;
BA_ "SPN" SG_ 2566821118 EngAuxCoolantPress 1203;
BA_ "SigType" SG_ 2566821118 EngAuxCoolantPress 1;
BA_ "SPN" SG_ 2566810622 Driver2 1626;
BA_ "SigType" SG_ 2566810622 Driver2 8;
BA_ "SPN" SG_ 2566810622 Driver1 1625;
BA_ "SigType" SG_ 2566810622 Driver1 8;
BA_ "SPN" SG_ 2566847742 FuelLevel2 38;
BA_ "SigType" SG_ 2566847742 FuelLevel2 1;
BA_ "SPN" SG_ 2566847742 FuelLevel1 96;
BA_ "SigType" SG_ 2566847742 FuelLevel1 1;
BA_ "SPN" SG_ 2566847742 CargoAmbientTemp 169;
BA_ "SigType" SG_ 2566847742 CargoAmbientTemp 1;
BA_ "SPN" SG_ 2566847742 EngOilFilterDiffPress 99;
BA_ "SigType" SG_ 2566847742 EngOilFilterDiffPress 1;
BA_ "SPN" SG_ 2566847742 EngFuelFilterDiffPress 1382;
BA_ "SigType" SG_ 2566847742 EngFuelFilterDiffPress 1;
BA_ "SPN" SG_ 2566847742 WasherFluidLevel 80;
BA_ "SigType" SG_ 2566847742 WasherFluidLevel 1;
BA_ "SPN" SG_ 2566811902 PoweredVehicleWeight 1585;
BA_ "SigType" SG_ 2566811902 PoweredVehicleWeight 1;
BA_ "SPN" SG_ 2566811902 GrossCombinationVehicleWeight 1760;
BA_ "SigType" SG_ 2566811902 GrossCombinationVehicleWeight 1;
BA_ "SPN" SG_ 2563768062 MxCntnuousRetarderTorqueLimitRq 1791;
BA_ "SigType" SG_ 2563768062 MxCntnuousRetarderTorqueLimitRq 1;
BA_ "SPN" SG_ 2563768062 MnCntnuousRetarderTorqueLimitRq 1790;
BA_ "SigType" SG_ 2563768062 MnCntnuousRetarderTorqueLimitRq 1;
BA_ "SPN" SG_ 2563768062 MxCntinuousRetarderSpeedLimitRq 1789;
BA_ "SigType" SG_ 2563768062 MxCntinuousRetarderSpeedLimitRq 1;
BA_ "SPN" SG_ 2563768062 MnCntinuousRetarderSpeedLimitRq 1788;
BA_ "SigType" SG_ 2563768062 MnCntinuousRetarderSpeedLimitRq 1;
BA_ "SPN" SG_ 2563768062 EngTorqueLimitRqMaxContinuous 1787;
BA_ "SigType" SG_ 2563768062 EngTorqueLimitRqMaxContinuous 1;
BA_ "SPN" SG_ 2563768062 EngTorqueLimitRqMinContinuous 1786;
BA_ "SigType" SG_ 2563768062 EngTorqueLimitRqMinContinuous 1;
BA_ "SPN" SG_ 2563768062 EngSpeedLimitRqMaxContinuous 1785;
BA_ "SigType" SG_ 2563768062 EngSpeedLimitRqMaxContinuous 1;
BA_ "SPN" SG_ 2563768062 EngSpeedLimitRqMinContinuous 1784;
BA_ "SigType" SG_ 2563768062 EngSpeedLimitRqMinContinuous 1;
BA_ "SPN" SG_ 2633924862 EngAverageCombustionTime 1465;
BA_ "SigType" SG_ 2633924862 EngAverageCombustionTime 1;
BA_ "SPN" SG_ 2633924862 EngDesiredCombustionTime 1464;
BA_ "SigType" SG_ 2633924862 EngDesiredCombustionTime 1;
BA_ "SPN" SG_ 2633924606 EngCyl20CombustionTime 1463;
BA_ "SigType" SG_ 2633924606 EngCyl20CombustionTime 1;
BA_ "SPN" SG_ 2633924606 EngCyl19CombustionTime 1462;
BA_ "SigType" SG_ 2633924606 EngCyl19CombustionTime 1;
BA_ "SPN" SG_ 2633924606 EngCyl18CombustionTime 1461;
BA_ "SigType" SG_ 2633924606 EngCyl18CombustionTime 1;
BA_ "SPN" SG_ 2633924606 EngCyl17CombustionTime 1460;
BA_ "SigType" SG_ 2633924606 EngCyl17CombustionTime 1;
BA_ "SPN" SG_ 2633924350 EngCyl16CombustionTime 1459;
BA_ "SigType" SG_ 2633924350 EngCyl16CombustionTime 1;
BA_ "SPN" SG_ 2633924350 EngCyl15CombustionTime 1458;
BA_ "SigType" SG_ 2633924350 EngCyl15CombustionTime 1;
BA_ "SPN" SG_ 2633924350 EngCyl14CombustionTime 1457;
BA_ "SigType" SG_ 2633924350 EngCyl14CombustionTime 1;
BA_ "SPN" SG_ 2633924350 EngCyl13CombustionTime 1456;
BA_ "SigType" SG_ 2633924350 EngCyl13CombustionTime 1;
BA_ "SPN" SG_ 2633924094 EngCyl12CombustionTime 1455;
BA_ "SigType" SG_ 2633924094 EngCyl12CombustionTime 1;
BA_ "SPN" SG_ 2633924094 EngCyl11CombustionTime 1454;
BA_ "SigType" SG_ 2633924094 EngCyl11CombustionTime 1;
BA_ "SPN" SG_ 2633924094 EngCyl10CombustionTime 1453;
BA_ "SigType" SG_ 2633924094 EngCyl10CombustionTime 1;
BA_ "SPN" SG_ 2633924094 EngCyl9CombustionTime 1452;
BA_ "SigType" SG_ 2633924094 EngCyl9CombustionTime 1;
BA_ "SPN" SG_ 2633923838 EngCyl8CombustionTime 1451;
BA_ "SigType" SG_ 2633923838 EngCyl8CombustionTime 1;
BA_ "SPN" SG_ 2633923838 EngCyl7CombustionTime 1450;
BA_ "SigType" SG_ 2633923838 EngCyl7CombustionTime 1;
BA_ "SPN" SG_ 2633923838 EngCyl6CombustionTime 1449;
BA_ "SigType" SG_ 2633923838 EngCyl6CombustionTime 1;
BA_ "SPN" SG_ 2633923838 EngCyl5CombustionTime 1448;
BA_ "SigType" SG_ 2633923838 EngCyl5CombustionTime 1;
BA_ "SPN" SG_ 2633923582 EngCyl4CombustionTime 1447;
BA_ "SigType" SG_ 2633923582 EngCyl4CombustionTime 1;
BA_ "SPN" SG_ 2633923582 EngCyl3CombustionTime 1446;
BA_ "SigType" SG_ 2633923582 EngCyl3CombustionTime 1;
BA_ "SPN" SG_ 2633923582 EngCyl2CombustionTime 1445;
BA_ "SigType" SG_ 2633923582 EngCyl2CombustionTime 1;
BA_ "SPN" SG_ 2633923582 EngCyl1CombustionTime 1444;
BA_ "SigType" SG_ 2633923582 EngCyl1CombustionTime 1;
BA_ "SPN" SG_ 2633878014 TotalCountOfConfigChangesMade 2887;
BA_ "SigType" SG_ 2633878014 TotalCountOfConfigChangesMade 1;
BA_ "SPN" SG_ 2566771966 TransOilLevelRq 3809;
BA_ "SigType" SG_ 2566771966 TransOilLevelRq 4;
BA_ "SPN" SG_ 2566771966 FifthWheelReleaseCtrl 3314;
BA_ "SigType" SG_ 2566771966 FifthWheelReleaseCtrl 4;
BA_ "SPN" SG_ 2566771966 FfthWhlRlaseCtrlSecurityLockout 3315;
BA_ "SigType" SG_ 2566771966 FfthWhlRlaseCtrlSecurityLockout 4;
BA_ "SPN" SG_ 2566771966 TransferCaseSelectorSwitch 2796;
BA_ "SPN" SG_ 2564882174 DslPrtcltFltrRgnrtonForceSwitch 3696;
BA_ "SigType" SG_ 2564882174 DslPrtcltFltrRgnrtonForceSwitch 4;
BA_ "SPN" SG_ 2564882174 DslPrtcltFltrRgnrtnInhbitSwitch 3695;
BA_ "SigType" SG_ 2564882174 DslPrtcltFltrRgnrtnInhbitSwitch 4;
BA_ "SPN" SG_ 2564882174 SelectedMaxVehicleSpeedLimit 2596;
BA_ "SigType" SG_ 2564882174 SelectedMaxVehicleSpeedLimit 1;
BA_ "SPN" SG_ 2564882174 RqCabZoneHeating 1686;
BA_ "SigType" SG_ 2564882174 RqCabZoneHeating 4;
BA_ "SPN" SG_ 2564882174 RqEngZoneHeating 1685;
BA_ "SigType" SG_ 2564882174 RqEngZoneHeating 4;
BA_ "SPN" SG_ 2564882174 AuxHeaterModeRq 1683;
BA_ "SigType" SG_ 2564882174 AuxHeaterModeRq 4;
BA_ "SPN" SG_ 2564882174 EngAutomaticStartEnableSwitch 1656;
BA_ "SigType" SG_ 2564882174 EngAutomaticStartEnableSwitch 4;
BA_ "SPN" SG_ 2564882174 AtmaticGearShiftingEnableSwitch 1666;
BA_ "SigType" SG_ 2564882174 AtmaticGearShiftingEnableSwitch 4;
BA_ "SPN" SG_ 2564882174 VhclLmtngSpdGvernorEnableSwitch 1653;
BA_ "SigType" SG_ 2564882174 VhclLmtngSpdGvernorEnableSwitch 4;
BA_ "SPN" SG_ 2564882174 VhclLmtngSpdGvrnrIncrmentSwitch 1654;
BA_ "SigType" SG_ 2564882174 VhclLmtngSpdGvrnrIncrmentSwitch 4;
BA_ "SPN" SG_ 2564882174 VhclLmtngSpdGvrnrDcrementSwitch 1655;
BA_ "SigType" SG_ 2564882174 VhclLmtngSpdGvrnrDcrementSwitch 4;
BA_ "SPN" SG_ 2564882174 SeatBeltSwitch 1856;
BA_ "SigType" SG_ 2564882174 SeatBeltSwitch 4;
BA_ "SPN" SG_ 2564882174 OperatorSeatDirectionSwitch 1714;
BA_ "SigType" SG_ 2564882174 OperatorSeatDirectionSwitch 4;
BA_ "SPN" SG_ 2564882174 BatteryMainSwitchHoldRq 1682;
BA_ "SigType" SG_ 2564882174 BatteryMainSwitchHoldRq 4;
BA_ "SPN" SG_ 2564882174 AuxHeaterCoolantPumpRq 1684;
BA_ "SigType" SG_ 2564882174 AuxHeaterCoolantPumpRq 4;
BA_ "SPN" SG_ 2564882174 CabInteriorTempCmd 1691;
BA_ "SigType" SG_ 2564882174 CabInteriorTempCmd 1;
BA_ "SPN" SG_ 2564882174 RqedPercentFanSpeed 986;
BA_ "SigType" SG_ 2564882174 RqedPercentFanSpeed 1;
BA_ "SPN" SG_ 2563833598 IlluminationBrightnessPercent 1487;
BA_ "SigType" SG_ 2563833598 IlluminationBrightnessPercent 1;
BA_ "SPN" SG_ 2566843390 UnitNumber 233;
BA_ "SigType" SG_ 2566843390 UnitNumber 8;
BA_ "SPN" SG_ 2566843390 SerialNumber 588;
BA_ "SigType" SG_ 2566843390 SerialNumber 8;
BA_ "SPN" SG_ 2566843390 Model 587;
BA_ "SigType" SG_ 2566843390 Model 8;
BA_ "SPN" SG_ 2566843390 Make 586;
BA_ "SigType" SG_ 2566843390 Make 8;
BA_ "SPN" SG_ 2566844926 ParkBrakeReleaseInhibitRq 3807;
BA_ "SigType" SG_ 2566844926 ParkBrakeReleaseInhibitRq 4;
BA_ "SPN" SG_ 2566844926 PTOGovernorState 976;
BA_ "SigType" SG_ 2566844926 PTOGovernorState 4;
BA_ "SPN" SG_ 2566844926 EngShutdownOverrideSwitch 1237;
BA_ "SigType" SG_ 2566844926 EngShutdownOverrideSwitch 4;
BA_ "SPN" SG_ 2566844926 EngTestModeSwitch 966;
BA_ "SigType" SG_ 2566844926 EngTestModeSwitch 4;
BA_ "SPN" SG_ 2566844926 EngIdleDecrementSwitch 967;
BA_ "SigType" SG_ 2566844926 EngIdleDecrementSwitch 4;
BA_ "SPN" SG_ 2566844926 EngIdleIncrementSwitch 968;
BA_ "SigType" SG_ 2566844926 EngIdleIncrementSwitch 4;
BA_ "SPN" SG_ 2566844926 CruiseCtrlStates 527;
BA_ "SPN" SG_ 2566844926 CruiseCtrlSetSpeed 86;
BA_ "SigType" SG_ 2566844926 CruiseCtrlSetSpeed 1;
BA_ "SPN" SG_ 2566844926 CruiseCtrlAccelerateSwitch 602;
BA_ "SigType" SG_ 2566844926 CruiseCtrlAccelerateSwitch 4;
BA_ "SPN" SG_ 2566844926 CruiseCtrlResumeSwitch 601;
BA_ "SigType" SG_ 2566844926 CruiseCtrlResumeSwitch 4;
BA_ "SPN" SG_ 2566844926 CruiseCtrlCoastSwitch 600;
BA_ "SigType" SG_ 2566844926 CruiseCtrlCoastSwitch 4;
BA_ "SPN" SG_ 2566844926 CruiseCtrlSetSwitch 599;
BA_ "SigType" SG_ 2566844926 CruiseCtrlSetSwitch 4;
BA_ "SPN" SG_ 2566844926 ClutchSwitch 598;
BA_ "SigType" SG_ 2566844926 ClutchSwitch 4;
BA_ "SPN" SG_ 2566844926 BrakeSwitch 597;
BA_ "SigType" SG_ 2566844926 BrakeSwitch 4;
BA_ "SPN" SG_ 2566844926 CruiseCtrlEnableSwitch 596;
BA_ "SigType" SG_ 2566844926 CruiseCtrlEnableSwitch 4;
BA_ "SPN" SG_ 2566844926 CruiseCtrlActive 595;
BA_ "SigType" SG_ 2566844926 CruiseCtrlActive 4;
BA_ "SPN" SG_ 2566844926 WheelBasedVehicleSpeed 84;
BA_ "SigType" SG_ 2566844926 WheelBasedVehicleSpeed 1;
BA_ "SPN" SG_ 2566844926 CruiseCtrlPauseSwitch 1633;
BA_ "SigType" SG_ 2566844926 CruiseCtrlPauseSwitch 4;
BA_ "SPN" SG_ 2566844926 ParkingBrakeSwitch 70;
BA_ "SigType" SG_ 2566844926 ParkingBrakeSwitch 4;
BA_ "SPN" SG_ 2566844926 TwoSpeedAxleSwitch 69;
BA_ "SigType" SG_ 2566844926 TwoSpeedAxleSwitch 4;
BA_ "SPN" SG_ 2566843902 CruiseCtrlLowSetLimitSpeed 88;
BA_ "SigType" SG_ 2566843902 CruiseCtrlLowSetLimitSpeed 1;
BA_ "SPN" SG_ 2566843902 CruiseCtrlHighSetLimitSpeed 87;
BA_ "SigType" SG_ 2566843902 CruiseCtrlHighSetLimitSpeed 1;
BA_ "SPN" SG_ 2566843902 MaxVehicleSpeedLimit 74;
BA_ "SigType" SG_ 2566843902 MaxVehicleSpeedLimit 1;
BA_ "SPN" SG_ 2566809598 AuxHeaterMaxOutputPower 1690;
BA_ "SigType" SG_ 2566809598 AuxHeaterMaxOutputPower 1;
BA_ "SPN" SG_ 2633940222 TripServiceBrakeApps 993;
BA_ "SigType" SG_ 2633940222 TripServiceBrakeApps 1;
BA_ "SPN" SG_ 2633940222 TripServiceBrakeDistance 992;
BA_ "SigType" SG_ 2633940222 TripServiceBrakeDistance 1;
BA_ "SPN" SG_ 2633940222 TripCompressionBrakeDistance 991;
BA_ "SigType" SG_ 2633940222 TripCompressionBrakeDistance 1;
BA_ "SPN" SG_ 2633940222 TotalCompressionBrakeDistance 990;
BA_ "SigType" SG_ 2633940222 TotalCompressionBrakeDistance 1;
BA_ "SPN" SG_ 2566775294 CbA_CRfrgrntCmprssorOutletPress 2609;
BA_ "SigType" SG_ 2566775294 CbA_CRfrgrntCmprssorOutletPress 1;
BA_ "SPN" SG_ 2566803710 Battery2Temp 1801;
BA_ "SigType" SG_ 2566803710 Battery2Temp 1;
BA_ "SPN" SG_ 2566803710 Battery1Temp 1800;
BA_ "SigType" SG_ 2566803710 Battery1Temp 1;
BA_ "SPN" SG_ 2365400830 Joystick9Button9PressedStatus 4697;
BA_ "SigType" SG_ 2365400830 Joystick9Button9PressedStatus 4;
BA_ "SPN" SG_ 2365400830 Joystick9Button10PressedStatus 4696;
BA_ "SigType" SG_ 2365400830 Joystick9Button10PressedStatus 4;
BA_ "SPN" SG_ 2365400830 Joystick9Button11PressedStatus 4695;
BA_ "SigType" SG_ 2365400830 Joystick9Button11PressedStatus 4;
BA_ "SPN" SG_ 2365400830 Joystick9Button12PressedStatus 4694;
BA_ "SigType" SG_ 2365400830 Joystick9Button12PressedStatus 4;
BA_ "SPN" SG_ 2365400830 Joystick9Button5PressedStatus 4693;
BA_ "SigType" SG_ 2365400830 Joystick9Button5PressedStatus 4;
BA_ "SPN" SG_ 2365400830 Joystick9Button6PressedStatus 4692;
BA_ "SigType" SG_ 2365400830 Joystick9Button6PressedStatus 4;
BA_ "SPN" SG_ 2365400830 Joystick9Button7PressedStatus 4691;
BA_ "SigType" SG_ 2365400830 Joystick9Button7PressedStatus 4;
BA_ "SPN" SG_ 2365400830 Joystick9Button8PressedStatus 4690;
BA_ "SigType" SG_ 2365400830 Joystick9Button8PressedStatus 4;
BA_ "SPN" SG_ 2365400830 Joystick9Button1PressedStatus 4689;
BA_ "SigType" SG_ 2365400830 Joystick9Button1PressedStatus 4;
BA_ "SPN" SG_ 2365400830 Joystick9Button2PressedStatus 4688;
BA_ "SigType" SG_ 2365400830 Joystick9Button2PressedStatus 4;
BA_ "SPN" SG_ 2365400830 Joystick9Button3PressedStatus 4687;
BA_ "SigType" SG_ 2365400830 Joystick9Button3PressedStatus 4;
BA_ "SPN" SG_ 2365400830 Joystick9Button4PressedStatus 4686;
BA_ "SigType" SG_ 2365400830 Joystick9Button4PressedStatus 4;
BA_ "SPN" SG_ 2365400830 Joystick9XAxisDetentPosStatus 4685;
BA_ "SigType" SG_ 2365400830 Joystick9XAxisDetentPosStatus 4;
BA_ "SPN" SG_ 2365400830 Joystick9YAxisDetentPosStatus 4684;
BA_ "SigType" SG_ 2365400830 Joystick9YAxisDetentPosStatus 4;
BA_ "SPN" SG_ 2365400830 Joystick9YAxisPos 4683;
BA_ "SigType" SG_ 2365400830 Joystick9YAxisPos 1;
BA_ "SPN" SG_ 2365400830 Jystck9YAxsLvrFrwrdPstvPsStatus 4682;
BA_ "SigType" SG_ 2365400830 Jystck9YAxsLvrFrwrdPstvPsStatus 4;
BA_ "SPN" SG_ 2365400830 Jystck9YAxsLvrBckNgtvePosStatus 4681;
BA_ "SigType" SG_ 2365400830 Jystck9YAxsLvrBckNgtvePosStatus 4;
BA_ "SPN" SG_ 2365400830 Joystick9YAxisNeutralPosStatus 4680;
BA_ "SigType" SG_ 2365400830 Joystick9YAxisNeutralPosStatus 4;
BA_ "SPN" SG_ 2365400830 Joystick9XAxisPos 4679;
BA_ "SigType" SG_ 2365400830 Joystick9XAxisPos 1;
BA_ "SPN" SG_ 2365400830 Jystck9XAxsLvrRghtPstvPosStatus 4678;
BA_ "SigType" SG_ 2365400830 Jystck9XAxsLvrRghtPstvPosStatus 4;
BA_ "SPN" SG_ 2365400830 Jystck9XAxsLvrLftNgtvePosStatus 4677;
BA_ "SigType" SG_ 2365400830 Jystck9XAxsLvrLftNgtvePosStatus 4;
BA_ "SPN" SG_ 2365400830 Joystick9XAxisNeutralPosStatus 4676;
BA_ "SigType" SG_ 2365400830 Joystick9XAxisNeutralPosStatus 4;
BA_ "SPN" SG_ 2365401342 Joystick8Button9PressedStatus 4660;
BA_ "SigType" SG_ 2365401342 Joystick8Button9PressedStatus 4;
BA_ "SPN" SG_ 2365401342 Joystick8Button10PressedStatus 4659;
BA_ "SigType" SG_ 2365401342 Joystick8Button10PressedStatus 4;
BA_ "SPN" SG_ 2365401342 Joystick8Button11PressedStatus 4658;
BA_ "SigType" SG_ 2365401342 Joystick8Button11PressedStatus 4;
BA_ "SPN" SG_ 2365401342 Joystick8Button12PressedStatus 4657;
BA_ "SigType" SG_ 2365401342 Joystick8Button12PressedStatus 4;
BA_ "SPN" SG_ 2365401342 Joystick8Button5PressedStatus 4656;
BA_ "SigType" SG_ 2365401342 Joystick8Button5PressedStatus 4;
BA_ "SPN" SG_ 2365401342 Joystick8Button6PressedStatus 4655;
BA_ "SigType" SG_ 2365401342 Joystick8Button6PressedStatus 4;
BA_ "SPN" SG_ 2365401342 Joystick8Button7PressedStatus 4654;
BA_ "SigType" SG_ 2365401342 Joystick8Button7PressedStatus 4;
BA_ "SPN" SG_ 2365401342 Joystick8Button8PressedStatus 4653;
BA_ "SigType" SG_ 2365401342 Joystick8Button8PressedStatus 4;
BA_ "SPN" SG_ 2365401342 Joystick8Button1PressedStatus 4652;
BA_ "SigType" SG_ 2365401342 Joystick8Button1PressedStatus 4;
BA_ "SPN" SG_ 2365401342 Joystick8Button2PressedStatus 4651;
BA_ "SigType" SG_ 2365401342 Joystick8Button2PressedStatus 4;
BA_ "SPN" SG_ 2365401342 Joystick8Button3PressedStatus 4650;
BA_ "SigType" SG_ 2365401342 Joystick8Button3PressedStatus 4;
BA_ "SPN" SG_ 2365401342 Joystick8Button4PressedStatus 4649;
BA_ "SigType" SG_ 2365401342 Joystick8Button4PressedStatus 4;
BA_ "SPN" SG_ 2365401342 Joystick8XAxisDetentPosStatus 4648;
BA_ "SigType" SG_ 2365401342 Joystick8XAxisDetentPosStatus 4;
BA_ "SPN" SG_ 2365401342 Joystick8YAxisDetentPosStatus 4647;
BA_ "SigType" SG_ 2365401342 Joystick8YAxisDetentPosStatus 4;
BA_ "SPN" SG_ 2365401342 Joystick8YAxisPos 4646;
BA_ "SigType" SG_ 2365401342 Joystick8YAxisPos 1;
BA_ "SPN" SG_ 2365401342 Jystck8YAxsLvrFrwrdPstvPsStatus 4645;
BA_ "SigType" SG_ 2365401342 Jystck8YAxsLvrFrwrdPstvPsStatus 4;
BA_ "SPN" SG_ 2365401342 Jystck8YAxsLvrBckNgtvePosStatus 4644;
BA_ "SigType" SG_ 2365401342 Jystck8YAxsLvrBckNgtvePosStatus 4;
BA_ "SPN" SG_ 2365401342 Joystick8YAxisNeutralPosStatus 4643;
BA_ "SigType" SG_ 2365401342 Joystick8YAxisNeutralPosStatus 4;
BA_ "SPN" SG_ 2365401342 Joystick8XAxisPos 4642;
BA_ "SigType" SG_ 2365401342 Joystick8XAxisPos 1;
BA_ "SPN" SG_ 2365401342 Jystck8XAxsLvrRghtPstvPosStatus 4641;
BA_ "SigType" SG_ 2365401342 Jystck8XAxsLvrRghtPstvPosStatus 4;
BA_ "SPN" SG_ 2365401342 Jystck8XAxsLvrLftNgtvePosStatus 4640;
BA_ "SigType" SG_ 2365401342 Jystck8XAxsLvrLftNgtvePosStatus 4;
BA_ "SPN" SG_ 2365401342 Joystick8XAxisNeutralPosStatus 4639;
BA_ "SigType" SG_ 2365401342 Joystick8XAxisNeutralPosStatus 4;
BA_ "SPN" SG_ 2365401854 Joystick7Button9PressedStatus 4623;
BA_ "SigType" SG_ 2365401854 Joystick7Button9PressedStatus 4;
BA_ "SPN" SG_ 2365401854 Joystick7Button10PressedStatus 4622;
BA_ "SigType" SG_ 2365401854 Joystick7Button10PressedStatus 4;
BA_ "SPN" SG_ 2365401854 Joystick7Button11PressedStatus 4621;
BA_ "SigType" SG_ 2365401854 Joystick7Button11PressedStatus 4;
BA_ "SPN" SG_ 2365401854 Joystick7Button12PressedStatus 4620;
BA_ "SigType" SG_ 2365401854 Joystick7Button12PressedStatus 4;
BA_ "SPN" SG_ 2365401854 Joystick7Button5PressedStatus 4619;
BA_ "SigType" SG_ 2365401854 Joystick7Button5PressedStatus 4;
BA_ "SPN" SG_ 2365401854 Joystick7Button6PressedStatus 4618;
BA_ "SigType" SG_ 2365401854 Joystick7Button6PressedStatus 4;
BA_ "SPN" SG_ 2365401854 Joystick7Button7PressedStatus 4617;
BA_ "SigType" SG_ 2365401854 Joystick7Button7PressedStatus 4;
BA_ "SPN" SG_ 2365401854 Joystick7Button8PressedStatus 4616;
BA_ "SigType" SG_ 2365401854 Joystick7Button8PressedStatus 4;
BA_ "SPN" SG_ 2365401854 Joystick7Button1PressedStatus 4615;
BA_ "SigType" SG_ 2365401854 Joystick7Button1PressedStatus 4;
BA_ "SPN" SG_ 2365401854 Joystick7Button2PressedStatus 4614;
BA_ "SigType" SG_ 2365401854 Joystick7Button2PressedStatus 4;
BA_ "SPN" SG_ 2365401854 Joystick7Button3PressedStatus 4613;
BA_ "SigType" SG_ 2365401854 Joystick7Button3PressedStatus 4;
BA_ "SPN" SG_ 2365401854 Joystick7Button4PressedStatus 4612;
BA_ "SigType" SG_ 2365401854 Joystick7Button4PressedStatus 4;
BA_ "SPN" SG_ 2365401854 Joystick7XAxisDetentPosStatus 4611;
BA_ "SigType" SG_ 2365401854 Joystick7XAxisDetentPosStatus 4;
BA_ "SPN" SG_ 2365401854 Joystick7YAxisDetentPosStatus 4610;
BA_ "SigType" SG_ 2365401854 Joystick7YAxisDetentPosStatus 4;
BA_ "SPN" SG_ 2365401854 Joystick7YAxisPos 4609;
BA_ "SigType" SG_ 2365401854 Joystick7YAxisPos 1;
BA_ "SPN" SG_ 2365401854 Jystck7YAxsLvrFrwrdPstvPsStatus 4608;
BA_ "SigType" SG_ 2365401854 Jystck7YAxsLvrFrwrdPstvPsStatus 4;
BA_ "SPN" SG_ 2365401854 Jystck7YAxsLvrBckNgtvePosStatus 4607;
BA_ "SigType" SG_ 2365401854 Jystck7YAxsLvrBckNgtvePosStatus 4;
BA_ "SPN" SG_ 2365401854 Joystick7YAxisNeutralPosStatus 4606;
BA_ "SigType" SG_ 2365401854 Joystick7YAxisNeutralPosStatus 4;
BA_ "SPN" SG_ 2365401854 Joystick7XAxisPos 4605;
BA_ "SigType" SG_ 2365401854 Joystick7XAxisPos 1;
BA_ "SPN" SG_ 2365401854 Jystck7XAxsLvrRghtPstvPosStatus 4604;
BA_ "SigType" SG_ 2365401854 Jystck7XAxsLvrRghtPstvPosStatus 4;
BA_ "SPN" SG_ 2365401854 Jystck7XAxsLvrLftNgtvePosStatus 4603;
BA_ "SigType" SG_ 2365401854 Jystck7XAxsLvrLftNgtvePosStatus 4;
BA_ "SPN" SG_ 2365401854 Joystick7XAxisNeutralPosStatus 4602;
BA_ "SigType" SG_ 2365401854 Joystick7XAxisNeutralPosStatus 4;
BA_ "SPN" SG_ 2365402366 Joystick6Button9PressedStatus 4586;
BA_ "SigType" SG_ 2365402366 Joystick6Button9PressedStatus 4;
BA_ "SPN" SG_ 2365402366 Joystick6Button10PressedStatus 4585;
BA_ "SigType" SG_ 2365402366 Joystick6Button10PressedStatus 4;
BA_ "SPN" SG_ 2365402366 Joystick6Button11PressedStatus 4584;
BA_ "SigType" SG_ 2365402366 Joystick6Button11PressedStatus 4;
BA_ "SPN" SG_ 2365402366 Joystick6Button12PressedStatus 4583;
BA_ "SigType" SG_ 2365402366 Joystick6Button12PressedStatus 4;
BA_ "SPN" SG_ 2365402366 Joystick6Button5PressedStatus 4582;
BA_ "SigType" SG_ 2365402366 Joystick6Button5PressedStatus 4;
BA_ "SPN" SG_ 2365402366 Joystick6Button6PressedStatus 4581;
BA_ "SigType" SG_ 2365402366 Joystick6Button6PressedStatus 4;
BA_ "SPN" SG_ 2365402366 Joystick6Button7PressedStatus 4580;
BA_ "SigType" SG_ 2365402366 Joystick6Button7PressedStatus 4;
BA_ "SPN" SG_ 2365402366 Joystick6Button8PressedStatus 4579;
BA_ "SigType" SG_ 2365402366 Joystick6Button8PressedStatus 4;
BA_ "SPN" SG_ 2365402366 Joystick6Button1PressedStatus 4578;
BA_ "SigType" SG_ 2365402366 Joystick6Button1PressedStatus 4;
BA_ "SPN" SG_ 2365402366 Joystick6Button2PressedStatus 4577;
BA_ "SigType" SG_ 2365402366 Joystick6Button2PressedStatus 4;
BA_ "SPN" SG_ 2365402366 Joystick6Button3PressedStatus 4576;
BA_ "SigType" SG_ 2365402366 Joystick6Button3PressedStatus 4;
BA_ "SPN" SG_ 2365402366 Joystick6Button4PressedStatus 4575;
BA_ "SigType" SG_ 2365402366 Joystick6Button4PressedStatus 4;
BA_ "SPN" SG_ 2365402366 Joystick6XAxisDetentPosStatus 4574;
BA_ "SigType" SG_ 2365402366 Joystick6XAxisDetentPosStatus 4;
BA_ "SPN" SG_ 2365402366 Joystick6YAxisDetentPosStatus 4573;
BA_ "SigType" SG_ 2365402366 Joystick6YAxisDetentPosStatus 4;
BA_ "SPN" SG_ 2365402366 Joystick6YAxisPos 4572;
BA_ "SigType" SG_ 2365402366 Joystick6YAxisPos 1;
BA_ "SPN" SG_ 2365402366 Jystck6YAxsLvrFrwrdPstvPsStatus 4571;
BA_ "SigType" SG_ 2365402366 Jystck6YAxsLvrFrwrdPstvPsStatus 4;
BA_ "SPN" SG_ 2365402366 Jystck6YAxsLvrBckNgtvePosStatus 4570;
BA_ "SigType" SG_ 2365402366 Jystck6YAxsLvrBckNgtvePosStatus 4;
BA_ "SPN" SG_ 2365402366 Joystick6YAxisNeutralPosStatus 4569;
BA_ "SigType" SG_ 2365402366 Joystick6YAxisNeutralPosStatus 4;
BA_ "SPN" SG_ 2365402366 Joystick6XAxisPos 4568;
BA_ "SigType" SG_ 2365402366 Joystick6XAxisPos 1;
BA_ "SPN" SG_ 2365402366 Jystck6XAxsLvrRghtPstvPosStatus 4567;
BA_ "SigType" SG_ 2365402366 Jystck6XAxsLvrRghtPstvPosStatus 4;
BA_ "SPN" SG_ 2365402366 Jystck6XAxsLvrLftNgtvePosStatus 4566;
BA_ "SigType" SG_ 2365402366 Jystck6XAxsLvrLftNgtvePosStatus 4;
BA_ "SPN" SG_ 2365402366 Joystick6XAxisNeutralPosStatus 4565;
BA_ "SigType" SG_ 2365402366 Joystick6XAxisNeutralPosStatus 4;
BA_ "SPN" SG_ 2365402878 Joystick5Button9PressedStatus 4549;
BA_ "SigType" SG_ 2365402878 Joystick5Button9PressedStatus 4;
BA_ "SPN" SG_ 2365402878 Joystick5Button10PressedStatus 4548;
BA_ "SigType" SG_ 2365402878 Joystick5Button10PressedStatus 4;
BA_ "SPN" SG_ 2365402878 Joystick5Button11PressedStatus 4547;
BA_ "SigType" SG_ 2365402878 Joystick5Button11PressedStatus 4;
BA_ "SPN" SG_ 2365402878 Joystick5Button12PressedStatus 4546;
BA_ "SigType" SG_ 2365402878 Joystick5Button12PressedStatus 4;
BA_ "SPN" SG_ 2365402878 Joystick5Button5PressedStatus 4545;
BA_ "SigType" SG_ 2365402878 Joystick5Button5PressedStatus 4;
BA_ "SPN" SG_ 2365402878 Joystick5Button6PressedStatus 4544;
BA_ "SigType" SG_ 2365402878 Joystick5Button6PressedStatus 4;
BA_ "SPN" SG_ 2365402878 Joystick5Button7PressedStatus 4543;
BA_ "SigType" SG_ 2365402878 Joystick5Button7PressedStatus 4;
BA_ "SPN" SG_ 2365402878 Joystick5Button8PressedStatus 4542;
BA_ "SigType" SG_ 2365402878 Joystick5Button8PressedStatus 4;
BA_ "SPN" SG_ 2365402878 Joystick5Button1PressedStatus 4541;
BA_ "SigType" SG_ 2365402878 Joystick5Button1PressedStatus 4;
BA_ "SPN" SG_ 2365402878 Joystick5Button2PressedStatus 4540;
BA_ "SigType" SG_ 2365402878 Joystick5Button2PressedStatus 4;
BA_ "SPN" SG_ 2365402878 Joystick5Button3PressedStatus 4539;
BA_ "SigType" SG_ 2365402878 Joystick5Button3PressedStatus 4;
BA_ "SPN" SG_ 2365402878 Joystick5Button4PressedStatus 4538;
BA_ "SigType" SG_ 2365402878 Joystick5Button4PressedStatus 4;
BA_ "SPN" SG_ 2365402878 Joystick5XAxisDetentPosStatus 4537;
BA_ "SigType" SG_ 2365402878 Joystick5XAxisDetentPosStatus 4;
BA_ "SPN" SG_ 2365402878 Joystick5YAxisDetentPosStatus 4536;
BA_ "SigType" SG_ 2365402878 Joystick5YAxisDetentPosStatus 4;
BA_ "SPN" SG_ 2365402878 Joystick5YAxisPos 4535;
BA_ "SigType" SG_ 2365402878 Joystick5YAxisPos 1;
BA_ "SPN" SG_ 2365402878 Jystck5YAxsLvrFrwrdPstvPsStatus 4534;
BA_ "SigType" SG_ 2365402878 Jystck5YAxsLvrFrwrdPstvPsStatus 4;
BA_ "SPN" SG_ 2365402878 Jystck5YAxsLvrBckNgtvePosStatus 4533;
BA_ "SigType" SG_ 2365402878 Jystck5YAxsLvrBckNgtvePosStatus 4;
BA_ "SPN" SG_ 2365402878 Joystick5YAxisNeutralPosStatus 4532;
BA_ "SigType" SG_ 2365402878 Joystick5YAxisNeutralPosStatus 4;
BA_ "SPN" SG_ 2365402878 Joystick5XAxisPos 4531;
BA_ "SigType" SG_ 2365402878 Joystick5XAxisPos 1;
BA_ "SPN" SG_ 2365402878 Jystck5XAxsLvrRghtPstvPosStatus 4530;
BA_ "SigType" SG_ 2365402878 Jystck5XAxsLvrRghtPstvPosStatus 4;
BA_ "SPN" SG_ 2365402878 Jystck5XAxsLvrLftNgtvePosStatus 4529;
BA_ "SigType" SG_ 2365402878 Jystck5XAxsLvrLftNgtvePosStatus 4;
BA_ "SPN" SG_ 2365402878 Joystick5XAxisNeutralPosStatus 4528;
BA_ "SigType" SG_ 2365402878 Joystick5XAxisNeutralPosStatus 4;
BA_ "SPN" SG_ 2365403390 Joystick4Button9PressedStatus 4512;
BA_ "SigType" SG_ 2365403390 Joystick4Button9PressedStatus 4;
BA_ "SPN" SG_ 2365403390 Joystick4Button10PressedStatus 4511;
BA_ "SigType" SG_ 2365403390 Joystick4Button10PressedStatus 4;
BA_ "SPN" SG_ 2365403390 Joystick4Button11PressedStatus 4510;
BA_ "SigType" SG_ 2365403390 Joystick4Button11PressedStatus 4;
BA_ "SPN" SG_ 2365403390 Joystick4Button12PressedStatus 4509;
BA_ "SigType" SG_ 2365403390 Joystick4Button12PressedStatus 4;
BA_ "SPN" SG_ 2365403390 Joystick4Button5PressedStatus 4508;
BA_ "SigType" SG_ 2365403390 Joystick4Button5PressedStatus 4;
BA_ "SPN" SG_ 2365403390 Joystick4Button6PressedStatus 4507;
BA_ "SigType" SG_ 2365403390 Joystick4Button6PressedStatus 4;
BA_ "SPN" SG_ 2365403390 Joystick4Button7PressedStatus 4506;
BA_ "SigType" SG_ 2365403390 Joystick4Button7PressedStatus 4;
BA_ "SPN" SG_ 2365403390 Joystick4Button8PressedStatus 4505;
BA_ "SigType" SG_ 2365403390 Joystick4Button8PressedStatus 4;
BA_ "SPN" SG_ 2365403390 Joystick4Button1PressedStatus 4504;
BA_ "SigType" SG_ 2365403390 Joystick4Button1PressedStatus 4;
BA_ "SPN" SG_ 2365403390 Joystick4Button2PressedStatus 4503;
BA_ "SigType" SG_ 2365403390 Joystick4Button2PressedStatus 4;
BA_ "SPN" SG_ 2365403390 Joystick4Button3PressedStatus 4502;
BA_ "SigType" SG_ 2365403390 Joystick4Button3PressedStatus 4;
BA_ "SPN" SG_ 2365403390 Joystick4Button4PressedStatus 4501;
BA_ "SigType" SG_ 2365403390 Joystick4Button4PressedStatus 4;
BA_ "SPN" SG_ 2365403390 Joystick4XAxisDetentPosStatus 4500;
BA_ "SigType" SG_ 2365403390 Joystick4XAxisDetentPosStatus 4;
BA_ "SPN" SG_ 2365403390 Joystick4YAxisDetentPosStatus 4499;
BA_ "SigType" SG_ 2365403390 Joystick4YAxisDetentPosStatus 4;
BA_ "SPN" SG_ 2365403390 Joystick4YAxisPos 4498;
BA_ "SigType" SG_ 2365403390 Joystick4YAxisPos 1;
BA_ "SPN" SG_ 2365403390 Jystck4YAxsLvrFrwrdPstvPsStatus 4497;
BA_ "SigType" SG_ 2365403390 Jystck4YAxsLvrFrwrdPstvPsStatus 4;
BA_ "SPN" SG_ 2365403390 Jystck4YAxsLvrBckNgtvePosStatus 4496;
BA_ "SigType" SG_ 2365403390 Jystck4YAxsLvrBckNgtvePosStatus 4;
BA_ "SPN" SG_ 2365403390 Joystick4YAxisNeutralPosStatus 4495;
BA_ "SigType" SG_ 2365403390 Joystick4YAxisNeutralPosStatus 4;
BA_ "SPN" SG_ 2365403390 Joystick4XAxisPos 4494;
BA_ "SigType" SG_ 2365403390 Joystick4XAxisPos 1;
BA_ "SPN" SG_ 2365403390 Jystck4XAxsLvrRghtPstvPosStatus 4493;
BA_ "SigType" SG_ 2365403390 Jystck4XAxsLvrRghtPstvPosStatus 4;
BA_ "SPN" SG_ 2365403390 Jystck4XAxsLvrLftNgtvePosStatus 4492;
BA_ "SigType" SG_ 2365403390 Jystck4XAxsLvrLftNgtvePosStatus 4;
BA_ "SPN" SG_ 2365403390 Joystick4XAxisNeutralPosStatus 4491;
BA_ "SigType" SG_ 2365403390 Joystick4XAxisNeutralPosStatus 4;
VAL_ 2365446142 Jystck1GripXAxisDetentPosStatus 0 "NotInDetentPos" 1 "InDetentPos" 2 "ErrorIndicator" 3 "NotAvailable";
VAL_ 2365446142 Jystck1GripYAxisDetentPosStatus 0 "NotInDetentPos" 1 "InDetentPos" 2 "ErrorIndicator" 3 "NotAvailable";
VAL_ 2365446142 Jystck1ThetaAxisDetentPosStatus 0 "NotInDetentPos" 1 "InDetentPos" 2 "ErrorIndicator" 3 "NotAvailable";
VAL_ 2365446142 Jystck1ThtAxsClckwsPstvPsStatus 0 "NotOnPositiveSideOfNeutral" 1 "OnPositiveSideOfNeutral" 2 "ErrorIndicator" 3 "NotAvailable";
VAL_ 2365446142 Jystck1ThtaAxisNeutralPosStatus 0 "NotInNeutralPos" 1 "InNeutralPos" 2 "ErrorIndicator" 3 "NotAvailable";
VAL_ 2365446142 Jystck1GrpYAxsLvrFrwrdPstvPsStts 0 "NotOnPositiveSideOfNeutral" 1 "OnPositiveSideOfNeutral" 2 "ErrorIndicator" 3 "NotAvailable";
VAL_ 2365446142 Jystck1GrpYAxsLvrBckNgtvPsSttus 0 "NotOnNegativeSideOfNeutral" 1 "OnNegativeSideOfNeutral" 2 "ErrorIndicator" 3 "NotAvailable";
VAL_ 2365446142 Jystck1GrpYAxisNeutralPosStatus 0 "NotInNeutralPos" 1 "InNeutralPos" 2 "ErrorIndicator" 3 "NotAvailable";
VAL_ 2365446142 Jystck1GrpXAxsLvrRghtPstvPsStts 0 "NotOnPositiveSideOfNeutral" 1 "OnPositiveSideOfNeutral" 2 "ErrorIndicator" 3 "NotAvailable";
VAL_ 2365446142 Jystck1GrpXAxsLvrLftNgtvPsSttus 0 "NotOnNegativeSideOfNeutral" 1 "OnNegativeSideOfNeutral" 2 "ErrorIndicator" 3 "NotAvailable";
VAL_ 2365446142 Jystck1GrpXAxisNeutralPosStatus 0 "NotInNeutralPos" 1 "InNeutralPos" 2 "ErrorIndicator" 3 "NotAvailable";
VAL_ 2365446142 Jystck1ThtAxsCntrClckwsNgtvPsStt 0 "NotOnNegativeSideOfNeutral" 1 "OnNegativeSideOfNeutral" 2 "ErrorIndicator" 3 "NotAvailable";
VAL_ 2566810366 FuelPumpPrimerStatus 0 "Off" 1 "On" 2 "Error" 3 "Unavailable";
VAL_ 2566810366 EngWasteOilReservoirLevel 4 "RepresentsCompletelyFull";
VAL_ 2566810366 EngVentilationStatus 0 "SufficientlyVented" 1 "VentilationNeeded" 2 "VentilationDelay" 3 "CurrentlyVenting" 5 "ReservedForSAEAssignment" 6 "NtAblTDtrmnIfSufficientlyVented" 7 "NotAvailableNotInstalle";
VAL_ 2566810366 EngOilPrimingState 0 "NotSufficientlyLubricated" 1 "SufficientlyLubricated" 2 "UnblTDtrmnIfSffcentlyLubricated" 3 "NotAvailableNotInstalled";
VAL_ 2566810366 EngOilPrimingPumpSwitch 0 "Off" 1 "On" 2 "Error" 3 "NotAvailableNotInstalled";
VAL_ 2566810366 EngOilPreHeatedState 0 "NotSufficientlyPreheated" 1 "SufficientlyPreheated" 2 "UnblTDtrmnIfEngOlIsPrhtdSffcntl" 3 "NotAvailableNotInstalled";
VAL_ 2566810366 EngCoolantPreheatedState 0 "NotSufficientlyPreheated" 1 "SufficientlyPreheated" 2 "UnblTDtrmnEngClntPrhtdSffcently" 3 "NotAvailableNotInstalled";
VAL_ 2633929726 TurningGearEngaged 0 "TurningGearIsNotEngaged" 1 "TurningGearIsEngaged" 2 "Error" 3 "NotAvailable";
VAL_ 2633929726 SafetyWireStatus 0 "SafetyWireHasNotBeenActivated" 1 "SafetyWireHasBeenActivated" 2 "Error" 3 "NotAvailable";
VAL_ 2566772222 EngVrableGeometryTurbo1CtrlMode 0 "openLoop" 1 "closedLoop" 2 "SAEReserved" 3 "notAvailable";
VAL_ 2566772222 EngVrblGmtryTrbArCtrlShtffValve 0 "VGTAirCtrlShutoffValveIsOff" 1 "VGTAirCtrlShutoffValveIsOn" 2 "Reserved" 3 "NotAvailable";
VAL_ 2633940734 EngRotationDirection 0 "CounterClockWise" 1 "ClockWise" 2 "Reserved" 3 "NotAvailable";
VAL_ 2633940734 EngIntakeManifoldPressCtrlMode 0 "OpenLoop" 1 "ClosedLoop" 2 "SAEReserved" 3 "NotAvailable";
VAL_ 2566840318 Aftertreatment2IntakeDewPoint 0 "NotExceededDewPoint" 1 "ExceededDewPoint" 2 "Error" 3 "NotAvailable";
VAL_ 2566840318 Aftertreatment2ExhaustDewPoint 0 "NotExceededDewPoint" 1 "ExceededDewPoint" 2 "Error" 3 "NotAvailable";
VAL_ 2566840318 Aftertreatment1IntakeDewPoint 0 "NotExceededDewPoint" 1 "ExceededDewPoint" 2 "Error" 3 "NotAvailable";
VAL_ 2566840318 Aftertreatment1ExhaustDewPoint 0 "NotExceededDewPoint" 1 "ExceededDewPoint" 2 "Error" 3 "NotAvailable";
VAL_ 2566840318 EstEngPrsticLossesPercentTorque 251 "LossesAreIncludedInSPN514";
VAL_ 2364539902 SCRThermalManagementActive 0 "SCRThermalManagementIsNotActive" 1 "SCRThermalManagementIsActive" 2 "Reserved" 3 "DontCare";
VAL_ 2364539902 MmntryEngMaxPowerEnableFeedback 0 "disabled" 1 "supported" 2 "reserved" 3 "dontCare";
VAL_ 2364539902 DPFThermalManagementActive 0 "DPFThermalManagementIsNotActive" 1 "DPFThermalManagementIsActive" 2 "Reserved" 3 "DontCare";
VAL_ 2364539902 VhclAccelerationRateLimitStatus 0 "LimitNotActive" 1 "LimitActive" 2 "Reserved" 3 "NotAvailable";
VAL_ 2364539902 AccelPedal2LowIdleSwitch 0 "AcclPedal2NotInLowIdleCondition" 1 "AccelPedal2InLowIdleCondition" 2 "Error" 3 "NotAvailable";
VAL_ 2364539902 RoadSpeedLimitStatus 0 "Active" 1 "NotActive" 2 "Error" 3 "NotAvailable";
VAL_ 2364539902 AccelPedalKickdownSwitch 0 "KickdownPassive" 1 "KickdownActive" 2 "Error" 3 "NotAvailable";
VAL_ 2364539902 AccelPedal1LowIdleSwitch 0 "AcclPedal1NotInLowIdleCondition" 1 "AccelPedal1InLowIdleCondition" 2 "Error" 3 "NotAvailable";
VAL_ 2364540158 ActlEngPrcntTrqueHighResolution 0 "0000" 1 "0125" 7 "0875" 8 "1111NotAvailable";
VAL_ 2364540158 EngStarterMode 0 "startNotRqed" 1 "starterActiveGearNotEngaged" 2 "starterActiveGearEngaged" 3 "strtFnshdStrtrNtActvAftrHvngBnA" 4 "strtrInhbtdDToEngAlreadyRunning" 5 "strtrInhbtdDTEngNtReadyForStart" 6 "strtrInhbtdDTDrvlnEnggdOthrTrns" 7 "strtrInhbtdDToActiveImmobilizer" 8 "strtrInhbtdDueToStarterOvertemp" 9 "1011Reserved" 12 "starterInhibitedReasonUnknown" 14 "error" 15 "notAvailable";
VAL_ 2364540158 EngTorqueMode 0 "Low idle governor/no request (de" 1 "Accelerator pedal/operator selec" 2 "Cruise control" 3 "PTO governor" 4 "Road speed governor" 5 "ASR control" 6 "Transmission control" 7 "ABS control" 8 "Torque limiting" 9 "High speed governor" 10 "Braking system" 11 "Remote accelerator" 15 "Not available";
VAL_ 2566841342 SupportTSC1CtrlPurposeGroup4 1 "P25ReservedForAssignmentBySAE";
VAL_ 2566841342 SupportTSC1CtrlPurposeGroup3 1 "P17ReservedForAssignmentBySAE";
VAL_ 2566841342 SupportTSC1CtrlPurposeGroup2 1 "P9ReservedForAssignmentBySAE";
VAL_ 2566841342 SupportTSC1CtrlPurposeGroup1 1 "P1AccelPedal_OperatorSelection";
VAL_ 2566841342 SupportVariableRateTSC1Message 1 "MsTransRate";
VAL_ 2566767870 BrakeTempWarning 0 "NotActive" 1 "Active" 2 "Reserved" 3 "notAvailable";
VAL_ 2566767870 PrkngBrkeActuatorFullyActivated 0 "PrkngBrkActtorNotFullyActivated" 1 "PrkngBrkeActuatorFullyActivated" 2 "Error" 3 "NotAvailable";
VAL_ 2566767870 XBRActiveCtrlMode 0 "NoBrakeDemandBeingExecuted" 1 "DrvrsBrkDmndBngExctdNExtlBrkDmn" 2 "AddtnMdOfXBRAcclrtnCtrlBngExctd" 3 "MxMdOfXBRAcclrtnCtrlBngExecuted" 4 "1110ReservedForSAEAssignment" 15 "NotAvailable";
VAL_ 2566767870 XBRSystemState 0 "AnyExtlBrkeDemandWillBeAccepted" 1 "OnlyExtlBrkDmndOfHghstXBRPrrtyW" 2 "NoExtlBrakeDemandWillBeAccepted" 3 "NotAvailable";
VAL_ 2566767870 FoundationBrakeUse 0 "FoundationBrakesNotInUse" 1 "FoundationBrakesInUse" 2 "Reserved" 3 "NotAvailable";
VAL_ 2566767870 HillHolderMode 0 "Inactive" 1 "Active" 2 "ActvBtWllChngTInctvInAShortTime" 3 "101Reserved" 6 "HillHolderNotFunctional" 7 "NotAvailable";
VAL_ 2566767870 HaltBrakeMode 0 "Inactive" 1 "Active" 2 "ActiveButNotFunctioningProperly" 3 "101NotDefined" 6 "Reserved" 7 "NotAvailable";
VAL_ 2565865982 EngAuxShutdownSwitch 0 "Off" 1 "On" 2 "Error" 3 "NotAvailable";
VAL_ 2565865982 TrctrMntdTrilerABSWarningSignal 0 "Off" 1 "On" 2 "Reserved" 3 "TakeNoAction";
VAL_ 2565865982 TrailerABSStatus 0 "InformationAvailableButNotActive" 1 "TrailerABSActive" 2 "Reserved" 3 "NotAvailableOrNotSupported";
VAL_ 2565865982 HaltBrakeSwitch 0 "HaltBrakeSwitchPassive" 1 "HaltBrakeSwitchActive" 2 "Error" 3 "NotAvailable";
VAL_ 2565865982 ATC_ASRInformationSignal 0 "Off" 1 "On" 2 "Reserved" 3 "TakeNoAction";
VAL_ 2565865982 ABS_EBSAmberWarningSignal 0 "Off" 1 "On" 2 "Reserved" 3 "TakeNoAction";
VAL_ 2565865982 EBSRedWarningSignal 0 "Off" 1 "On" 2 "Reserved" 3 "TakeNoAction";
VAL_ 2565865982 ABSFullyOperational 0 "NotFullyOperational" 1 "FullyOperational" 2 "Reserved" 3 "NotAvailable";
VAL_ 2565865982 RemoteAccelEnableSwitch 0 "Off" 1 "On" 2 "Error" 3 "NotAvailable";
VAL_ 2565865982 EngDerateSwitch 0 "Off" 1 "On" 2 "Error" 3 "NotAvailable";
VAL_ 2565865982 AccelInterlockSwitch 0 "Off" 1 "On" 2 "Error" 3 "NotAvailable";
VAL_ 2565865982 TractionCtrlOverrideSwitch 0 "Off" 1 "On" 2 "Error" 3 "NotAvailableNotInstalled";
VAL_ 2565865982 ASRHillHolderSwitch 0 "ASRHillHolderSwitchPassive" 1 "ASRHillHolderSwitchActive" 2 "Error" 3 "NotAvailable";
VAL_ 2565865982 ASROffroadSwitch 0 "ASROffroadSwitchPassive" 1 "ASROffroadSwitchActive" 2 "Error" 3 "NotAvailable";
VAL_ 2565865982 ABSOffroadSwitch 0 "ABSOffroadSwitchPassive" 1 "ABSOffroadSwitchActive" 2 "Error" 3 "NotAvailable";
VAL_ 2565865982 EBSBrakeSwitch 0 "BrakePedalIsNotBeingPressed" 1 "BrakePedalIsBeingPressed" 2 "Error" 3 "NotAvailable";
VAL_ 2565865982 AntiLockBrakingActive 0 "ABSPassiveButInstalled" 1 "ABSActive" 2 "Reserved" 3 "NotAvailable";
VAL_ 2565865982 ASRBrakeCtrlActive 0 "ASRBrakeCtrlPassiveButInstalled" 1 "ASRBrakeCtrlActive" 2 "Reserved" 3 "NotAvailable";
VAL_ 2565865982 ASREngCtrlActive 0 "ASREngCtrlPassiveButInstalled" 1 "ASREngCtrlActive" 2 "Reserved" 3 "NotAvailable";
VAL_ 2565867262 RearAxleGroupEngagementStatus 0 "rearAxleGroupDisengaged" 1 "rearAxleGroupEngaged" 2 "error" 3 "notAvailable";
VAL_ 2565867262 FrontAxleGroupEngagementStatus 0 "frontAxleGroupDisengaged" 1 "frontAxleGroupEngaged" 2 "error" 3 "notAvailable";
VAL_ 2565867262 DiffLockStateCentralRear 0 "DiffLockDisengaged" 1 "DiffLockEngaged" 2 "Error" 3 "NotAvailable";
VAL_ 2565867262 DiffLockStateCentralFront 0 "DiffLockDisengaged" 1 "DiffLockEngaged" 2 "Error" 3 "NotAvailable";
VAL_ 2565867262 DiffLockStateCentral 0 "DiffLockDisengaged" 1 "DiffLockEngaged" 2 "Error" 3 "NotAvailable";
VAL_ 2565867262 DiffLockStateRearAxle2 0 "DiffLockDisengaged" 1 "DiffLockEngaged" 2 "Error" 3 "NotAvailable";
VAL_ 2565867262 DiffLockStateRearAxle1 0 "DiffLockDisengaged" 1 "DiffLockEngaged" 2 "Error" 3 "NotAvailable";
VAL_ 2565867262 DiffLockStateFrontAxle2 0 "DiffLockDisengaged" 1 "DiffLockEngaged" 2 "Error" 3 "NotAvailable";
VAL_ 2565867262 DiffLockStateFrontAxle1 0 "DiffLockDisengaged" 1 "DiffLockEngaged" 2 "Error" 3 "NotAvailable";
VAL_ 2566771966 TransOilLevelRq 0 "NoTransOilLevelReadingDesired" 1 "TransOilLevelReadingDesired" 2 "Reserved" 3 "DontCare_TakeNoAction";
VAL_ 2566771966 FifthWheelReleaseCtrl 0 "CouplerLocked" 1 "CplrUnlckdTrlrCnBUnhtchdHitched" 2 "Error" 3 "NotAvailable";
VAL_ 2566771966 FfthWhlRlaseCtrlSecurityLockout 0 "FifthWheelReleaseDisabled" 1 "FifthWheelReleaseEnabled" 2 "Error" 3 "NotAvailable";
VAL_ 2566771966 TransferCaseSelectorSwitch 0 "2WheelHigh" 1 "4WheelHigh" 2 "Neutral" 3 "2WheelLow" 4 "4WheelLow" 5 "ReservedForSAEAssignment" 6 "ErrorIndicator" 7 "NotAvailable";
VAL_ 2564882174 DslPrtcltFltrRgnrtonForceSwitch 0 "notActive" 1 "active" 2 "error" 3 "notAvailable";
VAL_ 2564882174 DslPrtcltFltrRgnrtnInhbitSwitch 0 "notActive" 1 "active" 2 "error" 3 "notAvailable";
VAL_ 2564882174 SelectedMaxVehicleSpeedLimit 0 "sUsdTIndctThtAMxVhclSpdIsNtSlct";
VAL_ 2564882174 RqCabZoneHeating 0 "DoNotCabEngZone" 1 "HeatCabZone" 2 "Reserved" 3 "DontCare_TakeNoAction";
VAL_ 2564882174 RqEngZoneHeating 0 "DoNotHeatEngZone" 1 "HeatEngZone" 2 "Reserved" 3 "DontCare_TakeNoAction";
VAL_ 2564882174 AuxHeaterModeRq 0 "DeactivateAuxHeater" 1 "OffDTADRPrErpnRgltnsFrTrnsprtOf" 2 "EconomyMode" 3 "NormalMode" 4 "1101NotDefined" 14 "Reserved" 15 "DontCare_TakeNoAction";
VAL_ 2564882174 EngAutomaticStartEnableSwitch 0 "SwitchInOffState" 1 "SwitchInOnState" 2 "Error" 3 "NotAvailable";
VAL_ 2564882174 AtmaticGearShiftingEnableSwitch 0 "AutomatedGearShiftingIsDisabled" 1 "AutomatedGearShiftingIsEnabled" 2 "Error" 3 "NotAvailable";
VAL_ 2564882174 VhclLmtngSpdGvernorEnableSwitch 0 "SwitchDisabled" 1 "SwitchedEnabled" 2 "Error" 3 "NotAvailable";
VAL_ 2564882174 VhclLmtngSpdGvrnrIncrmentSwitch 0 "SwitchInOffState" 1 "SwitchInOnStateIncrease" 2 "Error" 3 "NotAvailable";
VAL_ 2564882174 VhclLmtngSpdGvrnrDcrementSwitch 0 "SwitchInOffState" 1 "SwitchInOnStateDecrease" 2 "Error" 3 "NotAvailable";
VAL_ 2564882174 SeatBeltSwitch 0 "NOTBuckled" 1 "OKSeatBeltIsBuckled" 2 "ErrrSwtchStteCannotBeDetermined" 3 "NotAvailable";
VAL_ 2564882174 OperatorSeatDirectionSwitch 0 "OperatorSeatNotFacingForward" 1 "OperatorSeatIsFacingForward" 2 "Error" 3 "NotAvailable";
VAL_ 2564882174 BatteryMainSwitchHoldRq 0 "ReleaseBatteryMainSwitch" 1 "HoldBatteryMainSwitch" 2 "undefined" 3 "DontCare_TakeNoAction";
VAL_ 2564882174 AuxHeaterCoolantPumpRq 0 "DeactivateWaterPump" 1 "ActivateWaterPump" 2 "Reserved" 3 "DontCare_TakeNoAction";
VAL_ 2566844926 ParkBrakeReleaseInhibitRq 0 "ParkBrakeReleaseInhibitNotRqed" 1 "ParkBrakeReleaseInhibitRqed" 2 "SAEReserved" 3 "Unavailable";
VAL_ 2566844926 PTOGovernorState 0 "Off_Disabled" 1 "Hold" 2 "RemoteHold" 3 "Standby" 4 "RemoteStandby" 5 "Set" 6 "Decelerate_Coast" 7 "Resume" 8 "Accelerate" 9 "AccelOverride" 10 "PreprogrammedSetSpeed1" 11 "PreprogrammedSetSpeed2" 12 "PreprogrammedSetSpeed3" 13 "PreprogrammedSetSpeed4" 14 "PreprogrammedSetSpeed5" 15 "PreprogrammedSetSpeed6" 16 "PreprogrammedSetSpeed7" 17 "PreprogrammedSetSpeed8" 18 "PTOSetSpeedMemory1" 19 "PTOSetSpeedMemory2" 20 "11110NotDefined" 31 "NotAvailable";
VAL_ 2566844926 EngShutdownOverrideSwitch 0 "Off" 1 "On" 2 "Error" 3 "NotAvailable";
VAL_ 2566844926 EngTestModeSwitch 0 "Off" 1 "On" 2 "Error" 3 "NotAvailable";
VAL_ 2566844926 EngIdleDecrementSwitch 0 "Off" 1 "On" 2 "Error" 3 "NotAvailable";
VAL_ 2566844926 EngIdleIncrementSwitch 0 "Off" 1 "On" 2 "Error" 3 "NotAvailable";
VAL_ 2566844926 CruiseCtrlStates 0 "Off_Disabled" 1 "Hold" 2 "Accelerate" 3 "Decelerate" 4 "Resume" 5 "Set" 6 "AccelOverride" 7 "NotAvailable";
VAL_ 2566844926 CruiseCtrlAccelerateSwitch 0 "CrsCtrlActvtrNotInPosAccelerate" 1 "CrsCtrlActivatorInPosAccelerate" 2 "Error" 3 "NotAvailable";
VAL_ 2566844926 CruiseCtrlResumeSwitch 0 "CrseCtrlActivatorNotInPosResume" 1 "CruiseCtrlActivatorInPosResume" 2 "Error" 3 "NotAvailable";
VAL_ 2566844926 CruiseCtrlCoastSwitch 0 "CriseCtrlActivatorNotInPosCoast" 1 "CruiseCtrlActivatorInPosCoast" 2 "Error" 3 "NotAvailable";
VAL_ 2566844926 CruiseCtrlSetSwitch 0 "CruiseCtrlActivatorNotInPosSet" 1 "CruiseCtrlActivatorInPosSet" 2 "Error" 3 "NotAvailable";
VAL_ 2566844926 ClutchSwitch 0 "ClutchPedalReleased" 1 "ClutchPedalDepressed" 2 "Error" 3 "NotAvailable";
VAL_ 2566844926 BrakeSwitch 0 "BrakePedalReleased" 1 "BrakePedalDepressed" 2 "Error" 3 "NotAvailable";
VAL_ 2566844926 CruiseCtrlEnableSwitch 0 "CruiseCtrlDisabled" 1 "CruiseCtrlEnabled" 2 "Error" 3 "NotAvailable";
VAL_ 2566844926 CruiseCtrlActive 0 "CruiseCtrlSwitchedOff" 1 "CruiseCtrlSwitchedOn" 2 "Error" 3 "NotAvailable";
VAL_ 2566844926 CruiseCtrlPauseSwitch 0 "Off" 1 "On" 2 "ErrorIndicator" 3 "TakeNoAction";
VAL_ 2566844926 ParkingBrakeSwitch 0 "ParkingBrakeNotSet" 1 "ParkingBrakeSet" 2 "Error" 3 "NotAvailable";
VAL_ 2566844926 TwoSpeedAxleSwitch 0 "LowSpeedRange" 1 "HighSpeedRange" 2 "Error" 3 "NotAvailable";
VAL_ 2365400830 Joystick9Button9PressedStatus 0 "ButtonNotPressed" 1 "ButtonPressed" 2 "ErrorIndicator" 3 "NotAvailable";
VAL_ 2365400830 Joystick9Button10PressedStatus 0 "ButtonNotPressed" 1 "ButtonPressed" 2 "ErrorIndicator" 3 "NotAvailable";
VAL_ 2365400830 Joystick9Button11PressedStatus 0 "ButtonNotPressed" 1 "ButtonPressed" 2 "ErrorIndicator" 3 "NotAvailable";
VAL_ 2365400830 Joystick9Button12PressedStatus 0 "ButtonNotPressed" 1 "ButtonPressed" 2 "ErrorIndicator" 3 "NotAvailable";
VAL_ 2365400830 Joystick9Button5PressedStatus 0 "ButtonNotPressed" 1 "ButtonPressed" 2 "ErrorIndicator" 3 "NotAvailable";
VAL_ 2365400830 Joystick9Button6PressedStatus 0 "ButtonNotPressed" 1 "ButtonPressed" 2 "ErrorIndicator" 3 "NotAvailable";
VAL_ 2365400830 Joystick9Button7PressedStatus 0 "ButtonNotPressed" 1 "ButtonPressed" 2 "ErrorIndicator" 3 "NotAvailable";
VAL_ 2365400830 Joystick9Button8PressedStatus 0 "ButtonNotPressed" 1 "ButtonPressed" 2 "ErrorIndicator" 3 "NotAvailable";
VAL_ 2365400830 Joystick9Button1PressedStatus 0 "ButtonNotPressed" 1 "ButtonPressed" 2 "ErrorIndicator" 3 "NotAvailable";
VAL_ 2365400830 Joystick9Button2PressedStatus 0 "ButtonNotPressed" 1 "ButtonPressed" 2 "ErrorIndicator" 3 "NotAvailable";
VAL_ 2365400830 Joystick9Button3PressedStatus 0 "ButtonNotPressed" 1 "ButtonPressed" 2 "ErrorIndicator" 3 "NotAvailable";
VAL_ 2365400830 Joystick9Button4PressedStatus 0 "ButtonNotPressed" 1 "ButtonPressed" 2 "ErrorIndicator" 3 "NotAvailable";
VAL_ 2365400830 Joystick9XAxisDetentPosStatus 0 "NotInDetentPos" 1 "InDetentPos" 2 "ErrorIndicator" 3 "NotAvailable";
VAL_ 2365400830 Joystick9YAxisDetentPosStatus 0 "NotInDetentPos" 1 "InDetentPos" 2 "ErrorIndicator" 3 "NotAvailable";
VAL_ 2365400830 Jystck9YAxsLvrFrwrdPstvPsStatus 0 "NotOnPositiveSideOfNeutral" 1 "OnPositiveSideOfNeutral" 2 "ErrorIndicator" 3 "NotAvailable";
VAL_ 2365400830 Jystck9YAxsLvrBckNgtvePosStatus 0 "NotOnNegativeSideOfNeutral" 1 "OnNegativeSideOfNeutral" 2 "ErrorIndicator" 3 "NotAvailable";
VAL_ 2365400830 Joystick9YAxisNeutralPosStatus 0 "NotInNeutralPos" 1 "InNeutralPos" 2 "ErrorIndicator" 3 "NotAvailable";
VAL_ 2365400830 Jystck9XAxsLvrRghtPstvPosStatus 0 "NotOnPositiveSideOfNeutral" 1 "OnPositiveSideOfNeutral" 2 "ErrorIndicator" 3 "NotAvailable";
VAL_ 2365400830 Jystck9XAxsLvrLftNgtvePosStatus 0 "NotOnNegativeSideOfNeutral" 1 "OnNegativeSideOfNeutral" 2 "ErrorIndicator" 3 "NotAvailable";
VAL_ 2365400830 Joystick9XAxisNeutralPosStatus 0 "NotInNeutralPos" 1 "InNeutralPos" 2 "ErrorIndicator" 3 "NotAvailable";
VAL_ 2365401342 Joystick8Button9PressedStatus 0 "ButtonNotPressed" 1 "ButtonPressed" 2 "ErrorIndicator" 3 "NotAvailable";
VAL_ 2365401342 Joystick8Button10PressedStatus 0 "ButtonNotPressed" 1 "ButtonPressed" 2 "ErrorIndicator" 3 "NotAvailable";
VAL_ 2365401342 Joystick8Button11PressedStatus 0 "ButtonNotPressed" 1 "ButtonPressed" 2 "ErrorIndicator" 3 "NotAvailable";
VAL_ 2365401342 Joystick8Button12PressedStatus 0 "ButtonNotPressed" 1 "ButtonPressed" 2 "ErrorIndicator" 3 "NotAvailable";
VAL_ 2365401342 Joystick8Button5PressedStatus 0 "ButtonNotPressed" 1 "ButtonPressed" 2 "ErrorIndicator" 3 "NotAvailable";
VAL_ 2365401342 Joystick8Button6PressedStatus 0 "ButtonNotPressed" 1 "ButtonPressed" 2 "ErrorIndicator" 3 "NotAvailable";
VAL_ 2365401342 Joystick8Button7PressedStatus 0 "ButtonNotPressed" 1 "ButtonPressed" 2 "ErrorIndicator" 3 "NotAvailable";
VAL_ 2365401342 Joystick8Button8PressedStatus 0 "ButtonNotPressed" 1 "ButtonPressed" 2 "ErrorIndicator" 3 "NotAvailable";
VAL_ 2365401342 Joystick8Button1PressedStatus 0 "ButtonNotPressed" 1 "ButtonPressed" 2 "ErrorIndicator" 3 "NotAvailable";
VAL_ 2365401342 Joystick8Button2PressedStatus 0 "ButtonNotPressed" 1 "ButtonPressed" 2 "ErrorIndicator" 3 "NotAvailable";
VAL_ 2365401342 Joystick8Button3PressedStatus 0 "ButtonNotPressed" 1 "ButtonPressed" 2 "ErrorIndicator" 3 "NotAvailable";
VAL_ 2365401342 Joystick8Button4PressedStatus 0 "ButtonNotPressed" 1 "ButtonPressed" 2 "ErrorIndicator" 3 "NotAvailable";
VAL_ 2365401342 Joystick8XAxisDetentPosStatus 0 "NotInDetentPos" 1 "InDetentPos" 2 "ErrorIndicator" 3 "NotAvailable";
VAL_ 2365401342 Joystick8YAxisDetentPosStatus 0 "NotInDetentPos" 1 "InDetentPos" 2 "ErrorIndicator" 3 "NotAvailable";
VAL_ 2365401342 Jystck8YAxsLvrFrwrdPstvPsStatus 0 "NotOnPositiveSideOfNeutral" 1 "OnPositiveSideOfNeutral" 2 "ErrorIndicator" 3 "NotAvailable";
VAL_ 2365401342 Jystck8YAxsLvrBckNgtvePosStatus 0 "NotOnNegativeSideOfNeutral" 1 "OnNegativeSideOfNeutral" 2 "ErrorIndicator" 3 "NotAvailable";
VAL_ 2365401342 Joystick8YAxisNeutralPosStatus 0 "NotInNeutralPos" 1 "InNeutralPos" 2 "ErrorIndicator" 3 "NotAvailable";
VAL_ 2365401342 Jystck8XAxsLvrRghtPstvPosStatus 0 "NotOnPositiveSideOfNeutral" 1 "OnPositiveSideOfNeutral" 2 "ErrorIndicator" 3 "NotAvailable";
VAL_ 2365401342 Jystck8XAxsLvrLftNgtvePosStatus 0 "NotOnNegativeSideOfNeutral" 1 "OnNegativeSideOfNeutral" 2 "ErrorIndicator" 3 "NotAvailable";
VAL_ 2365401342 Joystick8XAxisNeutralPosStatus 0 "NotInNeutralPos" 1 "InNeutralPos" 2 "ErrorIndicator" 3 "NotAvailable";
VAL_ 2365401854 Joystick7Button9PressedStatus 0 "ButtonNotPressed" 1 "ButtonPressed" 2 "ErrorIndicator" 3 "NotAvailable";
VAL_ 2365401854 Joystick7Button10PressedStatus 0 "ButtonNotPressed" 1 "ButtonPressed" 2 "ErrorIndicator" 3 "NotAvailable";
VAL_ 2365401854 Joystick7Button11PressedStatus 0 "ButtonNotPressed" 1 "ButtonPressed" 2 "ErrorIndicator" 3 "NotAvailable";
VAL_ 2365401854 Joystick7Button12PressedStatus 0 "ButtonNotPressed" 1 "ButtonPressed" 2 "ErrorIndicator" 3 "NotAvailable";
VAL_ 2365401854 Joystick7Button5PressedStatus 0 "ButtonNotPressed" 1 "ButtonPressed" 2 "ErrorIndicator" 3 "NotAvailable";
VAL_ 2365401854 Joystick7Button6PressedStatus 0 "ButtonNotPressed" 1 "ButtonPressed" 2 "ErrorIndicator" 3 "NotAvailable";
VAL_ 2365401854 Joystick7Button7PressedStatus 0 "ButtonNotPressed" 1 "ButtonPressed" 2 "ErrorIndicator" 3 "NotAvailable";
VAL_ 2365401854 Joystick7Button8PressedStatus 0 "ButtonNotPressed" 1 "ButtonPressed" 2 "ErrorIndicator" 3 "NotAvailable";
VAL_ 2365401854 Joystick7Button1PressedStatus 0 "ButtonNotPressed" 1 "ButtonPressed" 2 "ErrorIndicator" 3 "NotAvailable";
VAL_ 2365401854 Joystick7Button2PressedStatus 0 "ButtonNotPressed" 1 "ButtonPressed" 2 "ErrorIndicator" 3 "NotAvailable";
VAL_ 2365401854 Joystick7Button3PressedStatus 0 "ButtonNotPressed" 1 "ButtonPressed" 2 "ErrorIndicator" 3 "NotAvailable";
VAL_ 2365401854 Joystick7Button4PressedStatus 0 "ButtonNotPressed" 1 "ButtonPressed" 2 "ErrorIndicator" 3 "NotAvailable";
VAL_ 2365401854 Joystick7XAxisDetentPosStatus 0 "NotInDetentPos" 1 "InDetentPos" 2 "ErrorIndicator" 3 "NotAvailable";
VAL_ 2365401854 Joystick7YAxisDetentPosStatus 0 "NotInDetentPos" 1 "InDetentPos" 2 "ErrorIndicator" 3 "NotAvailable";
VAL_ 2365401854 Jystck7YAxsLvrFrwrdPstvPsStatus 0 "NotOnPositiveSideOfNeutral" 1 "OnPositiveSideOfNeutral" 2 "ErrorIndicator" 3 "NotAvailable";
VAL_ 2365401854 Jystck7YAxsLvrBckNgtvePosStatus 0 "NotOnNegativeSideOfNeutral" 1 "OnNegativeSideOfNeutral" 2 "ErrorIndicator" 3 "NotAvailable";
VAL_ 2365401854 Joystick7YAxisNeutralPosStatus 0 "NotInNeutralPos" 1 "InNeutralPos" 2 "ErrorIndicator" 3 "NotAvailable";
VAL_ 2365401854 Jystck7XAxsLvrRghtPstvPosStatus 0 "NotOnPositiveSideOfNeutral" 1 "OnPositiveSideOfNeutral" 2 "ErrorIndicator" 3 "NotAvailable";
VAL_ 2365401854 Jystck7XAxsLvrLftNgtvePosStatus 0 "NotOnNegativeSideOfNeutral" 1 "OnNegativeSideOfNeutral" 2 "ErrorIndicator" 3 "NotAvailable";
VAL_ 2365401854 Joystick7XAxisNeutralPosStatus 0 "NotInNeutralPos" 1 "InNeutralPos" 2 "ErrorIndicator" 3 "NotAvailable";
VAL_ 2365402366 Joystick6Button9PressedStatus 0 "ButtonNotPressed" 1 "ButtonPressed" 2 "ErrorIndicator" 3 "NotAvailable";
VAL_ 2365402366 Joystick6Button10PressedStatus 0 "ButtonNotPressed" 1 "ButtonPressed" 2 "ErrorIndicator" 3 "NotAvailable";
VAL_ 2365402366 Joystick6Button11PressedStatus 0 "ButtonNotPressed" 1 "ButtonPressed" 2 "ErrorIndicator" 3 "NotAvailable";
VAL_ 2365402366 Joystick6Button12PressedStatus 0 "ButtonNotPressed" 1 "ButtonPressed" 2 "ErrorIndicator" 3 "NotAvailable";
VAL_ 2365402366 Joystick6Button5PressedStatus 0 "ButtonNotPressed" 1 "ButtonPressed" 2 "ErrorIndicator" 3 "NotAvailable";
VAL_ 2365402366 Joystick6Button6PressedStatus 0 "ButtonNotPressed" 1 "ButtonPressed" 2 "ErrorIndicator" 3 "NotAvailable";
VAL_ 2365402366 Joystick6Button7PressedStatus 0 "ButtonNotPressed" 1 "ButtonPressed" 2 "ErrorIndicator" 3 "NotAvailable";
VAL_ 2365402366 Joystick6Button8PressedStatus 0 "ButtonNotPressed" 1 "ButtonPressed" 2 "ErrorIndicator" 3 "NotAvailable";
VAL_ 2365402366 Joystick6Button1PressedStatus 0 "ButtonNotPressed" 1 "ButtonPressed" 2 "ErrorIndicator" 3 "NotAvailable";
VAL_ 2365402366 Joystick6Button2PressedStatus 0 "ButtonNotPressed" 1 "ButtonPressed" 2 "ErrorIndicator" 3 "NotAvailable";
VAL_ 2365402366 Joystick6Button3PressedStatus 0 "ButtonNotPressed" 1 "ButtonPressed" 2 "ErrorIndicator" 3 "NotAvailable";
VAL_ 2365402366 Joystick6Button4PressedStatus 0 "ButtonNotPressed" 1 "ButtonPressed" 2 "ErrorIndicator" 3 "NotAvailable";
VAL_ 2365402366 Joystick6XAxisDetentPosStatus 0 "NotInDetentPos" 1 "InDetentPos" 2 "ErrorIndicator" 3 "NotAvailable";
VAL_ 2365402366 Joystick6YAxisDetentPosStatus 0 "NotInDetentPos" 1 "InDetentPos" 2 "ErrorIndicator" 3 "NotAvailable";
VAL_ 2365402366 Jystck6YAxsLvrFrwrdPstvPsStatus 0 "NotOnPositiveSideOfNeutral" 1 "OnPositiveSideOfNeutral" 2 "ErrorIndicator" 3 "NotAvailable";
VAL_ 2365402366 Jystck6YAxsLvrBckNgtvePosStatus 0 "NotOnNegativeSideOfNeutral" 1 "OnNegativeSideOfNeutral" 2 "ErrorIndicator" 3 "NotAvailable";
VAL_ 2365402366 Joystick6YAxisNeutralPosStatus 0 "NotInNeutralPos" 1 "InNeutralPos" 2 "ErrorIndicator" 3 "NotAvailable";
VAL_ 2365402366 Jystck6XAxsLvrRghtPstvPosStatus 0 "NotOnPositiveSideOfNeutral" 1 "OnPositiveSideOfNeutral" 2 "ErrorIndicator" 3 "NotAvailable";
VAL_ 2365402366 Jystck6XAxsLvrLftNgtvePosStatus 0 "NotOnNegativeSideOfNeutral" 1 "OnNegativeSideOfNeutral" 2 "ErrorIndicator" 3 "NotAvailable";
VAL_ 2365402366 Joystick6XAxisNeutralPosStatus 0 "NotInNeutralPos" 1 "InNeutralPos" 2 "ErrorIndicator" 3 "NotAvailable";
VAL_ 2365402878 Joystick5Button9PressedStatus 0 "ButtonNotPressed" 1 "ButtonPressed" 2 "ErrorIndicator" 3 "NotAvailable";
VAL_ 2365402878 Joystick5Button10PressedStatus 0 "ButtonNotPressed" 1 "ButtonPressed" 2 "ErrorIndicator" 3 "NotAvailable";
VAL_ 2365402878 Joystick5Button11PressedStatus 0 "ButtonNotPressed" 1 "ButtonPressed" 2 "ErrorIndicator" 3 "NotAvailable";
VAL_ 2365402878 Joystick5Button12PressedStatus 0 "ButtonNotPressed" 1 "ButtonPressed" 2 "ErrorIndicator" 3 "NotAvailable";
VAL_ 2365402878 Joystick5Button5PressedStatus 0 "ButtonNotPressed" 1 "ButtonPressed" 2 "ErrorIndicator" 3 "NotAvailable";
VAL_ 2365402878 Joystick5Button6PressedStatus 0 "ButtonNotPressed" 1 "ButtonPressed" 2 "ErrorIndicator" 3 "NotAvailable";
VAL_ 2365402878 Joystick5Button7PressedStatus 0 "ButtonNotPressed" 1 "ButtonPressed" 2 "ErrorIndicator" 3 "NotAvailable";
VAL_ 2365402878 Joystick5Button8PressedStatus 0 "ButtonNotPressed" 1 "ButtonPressed" 2 "ErrorIndicator" 3 "NotAvailable";
VAL_ 2365402878 Joystick5Button1PressedStatus 0 "ButtonNotPressed" 1 "ButtonPressed" 2 "ErrorIndicator" 3 "NotAvailable";
VAL_ 2365402878 Joystick5Button2PressedStatus 0 "ButtonNotPressed" 1 "ButtonPressed" 2 "ErrorIndicator" 3 "NotAvailable";
VAL_ 2365402878 Joystick5Button3PressedStatus 0 "ButtonNotPressed" 1 "ButtonPressed" 2 "ErrorIndicator" 3 "NotAvailable";
VAL_ 2365402878 Joystick5Button4PressedStatus 0 "ButtonNotPressed" 1 "ButtonPressed" 2 "ErrorIndicator" 3 "NotAvailable";
VAL_ 2365402878 Joystick5XAxisDetentPosStatus 0 "NotInDetentPos" 1 "InDetentPos" 2 "ErrorIndicator" 3 "NotAvailable";
VAL_ 2365402878 Joystick5YAxisDetentPosStatus 0 "NotInDetentPos" 1 "InDetentPos" 2 "ErrorIndicator" 3 "NotAvailable";
VAL_ 2365402878 Jystck5YAxsLvrFrwrdPstvPsStatus 0 "NotOnPositiveSideOfNeutral" 1 "OnPositiveSideOfNeutral" 2 "ErrorIndicator" 3 "NotAvailable";
VAL_ 2365402878 Jystck5YAxsLvrBckNgtvePosStatus 0 "NotOnNegativeSideOfNeutral" 1 "OnNegativeSideOfNeutral" 2 "ErrorIndicator" 3 "NotAvailable";
VAL_ 2365402878 Joystick5YAxisNeutralPosStatus 0 "NotInNeutralPos" 1 "InNeutralPos" 2 "ErrorIndicator" 3 "NotAvailable";
VAL_ 2365402878 Jystck5XAxsLvrRghtPstvPosStatus 0 "NotOnPositiveSideOfNeutral" 1 "OnPositiveSideOfNeutral" 2 "ErrorIndicator" 3 "NotAvailable";
VAL_ 2365402878 Jystck5XAxsLvrLftNgtvePosStatus 0 "NotOnNegativeSideOfNeutral" 1 "OnNegativeSideOfNeutral" 2 "ErrorIndicator" 3 "NotAvailable";
VAL_ 2365402878 Joystick5XAxisNeutralPosStatus 0 "NotInNeutralPos" 1 "InNeutralPos" 2 "ErrorIndicator" 3 "NotAvailable";
VAL_ 2365403390 Joystick4Button9PressedStatus 0 "ButtonNotPressed" 1 "ButtonPressed" 2 "ErrorIndicator" 3 "NotAvailable";
VAL_ 2365403390 Joystick4Button10PressedStatus 0 "ButtonNotPressed" 1 "ButtonPressed" 2 "ErrorIndicator" 3 "NotAvailable";
VAL_ 2365403390 Joystick4Button11PressedStatus 0 "ButtonNotPressed" 1 "ButtonPressed" 2 "ErrorIndicator" 3 "NotAvailable";
VAL_ 2365403390 Joystick4Button12PressedStatus 0 "ButtonNotPressed" 1 "ButtonPressed" 2 "ErrorIndicator" 3 "NotAvailable";
VAL_ 2365403390 Joystick4Button5PressedStatus 0 "ButtonNotPressed" 1 "ButtonPressed" 2 "ErrorIndicator" 3 "NotAvailable";
VAL_ 2365403390 Joystick4Button6PressedStatus 0 "ButtonNotPressed" 1 "ButtonPressed" 2 "ErrorIndicator" 3 "NotAvailable";
VAL_ 2365403390 Joystick4Button7PressedStatus 0 "ButtonNotPressed" 1 "ButtonPressed" 2 "ErrorIndicator" 3 "NotAvailable";
VAL_ 2365403390 Joystick4Button8PressedStatus 0 "ButtonNotPressed" 1 "ButtonPressed" 2 "ErrorIndicator" 3 "NotAvailable";
VAL_ 2365403390 Joystick4Button1PressedStatus 0 "ButtonNotPressed" 1 "ButtonPressed" 2 "ErrorIndicator" 3 "NotAvailable";
VAL_ 2365403390 Joystick4Button2PressedStatus 0 "ButtonNotPressed" 1 "ButtonPressed" 2 "ErrorIndicator" 3 "NotAvailable";
VAL_ 2365403390 Joystick4Button3PressedStatus 0 "ButtonNotPressed" 1 "ButtonPressed" 2 "ErrorIndicator" 3 "NotAvailable";
VAL_ 2365403390 Joystick4Button4PressedStatus 0 "ButtonNotPressed" 1 "ButtonPressed" 2 "ErrorIndicator" 3 "NotAvailable";
VAL_ 2365403390 Joystick4XAxisDetentPosStatus 0 "NotInDetentPos" 1 "InDetentPos" 2 "ErrorIndicator" 3 "NotAvailable";
VAL_ 2365403390 Joystick4YAxisDetentPosStatus 0 "NotInDetentPos" 1 "InDetentPos" 2 "ErrorIndicator" 3 "NotAvailable";
VAL_ 2365403390 Jystck4YAxsLvrFrwrdPstvPsStatus 0 "NotOnPositiveSideOfNeutral" 1 "OnPositiveSideOfNeutral" 2 "ErrorIndicator" 3 "NotAvailable";
VAL_ 2365403390 Jystck4YAxsLvrBckNgtvePosStatus 0 "NotOnNegativeSideOfNeutral" 1 "OnNegativeSideOfNeutral" 2 "ErrorIndicator" 3 "NotAvailable";
VAL_ 2365403390 Joystick4YAxisNeutralPosStatus 0 "NotInNeutralPos" 1 "InNeutralPos" 2 "ErrorIndicator" 3 "NotAvailable";
VAL_ 2365403390 Jystck4XAxsLvrRghtPstvPosStatus 0 "NotOnPositiveSideOfNeutral" 1 "OnPositiveSideOfNeutral" 2 "ErrorIndicator" 3 "NotAvailable";
VAL_ 2365403390 Jystck4XAxsLvrLftNgtvePosStatus 0 "NotOnNegativeSideOfNeutral" 1 "OnNegativeSideOfNeutral" 2 "ErrorIndicator" 3 "NotAvailable";
VAL_ 2365403390 Joystick4XAxisNeutralPosStatus 0 "NotInNeutralPos" 1 "InNeutralPos" 2 "ErrorIndicator" 3 "NotAvailable";
